VERSION ""

NS_ :

BS_:

BU_: GW_A CRR ADAS CRL MRR PDC VCU WCBS Tester

BO_ 128 ACU_ChimeTelltaleReq: 8 GW_A
 SG_ ACU_CoDSeatOccupSensorStat : 1|2@0+ (1,0) [0|3] ""  CRR,ADAS,CRL
 SG_ ACU_DSeatOccupSensorStat : 3|2@0+ (1,0) [0|3] ""  CRR,ADAS,CRL
 SG_ ACU_CoDSeatbeltBucklestatus : 4|1@0+ (1,0) [0|1] ""  CRR,ADAS,CRL
 SG_ ACU_DSeatbeltBucklestatus : 5|1@0+ (1,0) [0|1] ""  CRR,ADAS,CRL
 SG_ ACU_CoDAirbagStatus : 6|1@0+ (1,0) [0|1] ""  CRR,ADAS,CRL
 SG_ ACU_DAirbagStatus : 7|1@0+ (1,0) [0|1] ""  CRR,ADAS,CRL
 SG_ ACU_RPSeatOccupSensorStat : 9|2@0+ (1,0) [0|3] ""  CRR,ADAS,CRL
 SG_ ACU_MPSeatOccupSensorStat : 11|2@0+ (1,0) [0|3] ""  CRR,ADAS,CRL
 SG_ ACU_LPSeatOccupSensorStat : 13|2@0+ (1,0) [0|3] ""  CRR,ADAS,CRL
 SG_ ACU_RCABsts : 16|1@0+ (1,0) [0|1] ""  CRR,ADAS,CRL
 SG_ ACU_LCABsts : 17|1@0+ (1,0) [0|1] ""  CRR,ADAS,CRL
 SG_ ACU_RSABsts : 18|1@0+ (1,0) [0|1] ""  CRR,ADAS,CRL
 SG_ ACU_LSABsts : 19|1@0+ (1,0) [0|1] ""  CRR,ADAS,CRL
 SG_ ACU_RPSeatbeltBucklestatus : 20|1@0+ (1,0) [0|1] ""  CRR,ADAS,CRL
 SG_ ACU_MPSeatbeltBucklestatus : 21|1@0+ (1,0) [0|1] ""  CRR,ADAS,CRL
 SG_ ACU_LPSeatbeltBucklestatus : 22|1@0+ (1,0) [0|1] ""  CRR,ADAS,CRL
 SG_ ACU_CrashSts : 24|1@0+ (1,0) [0|1] ""  CRR,ADAS,CRL
 SG_ ACU_CrashRearOutputSts : 28|1@0+ (1,0) [0|1] ""  CRR,ADAS,CRL
 SG_ ACU_CrashRightOutputSts : 29|1@0+ (1,0) [0|1] ""  CRR,ADAS,CRL
 SG_ ACU_CrashLeftOutputSts : 30|1@0+ (1,0) [0|1] ""  CRR,ADAS,CRL
 SG_ ACU_CrashFrontOutputSts : 31|1@0+ (1,0) [0|1] ""  CRR,ADAS,CRL
 SG_ ACU_AirbagWarningStatus : 37|2@0+ (1,0) [0|3] ""  CRR,ADAS,CRL
 SG_ ACU_CoDSeatbletPTighten : 45|2@0+ (1,0) [0|3] ""  CRR,ADAS,CRL
 SG_ ACU_DSeatbletPTighten : 47|2@0+ (1,0) [0|3] ""  CRR,ADAS,CRL
 SG_ ACU_AliveCounter : 51|4@0+ (1,0) [0|15] ""  CRR,ADAS,CRL
 SG_ ACU_CheckSum : 63|8@0+ (1,0) [0|255] ""  CRR,ADAS,CRL

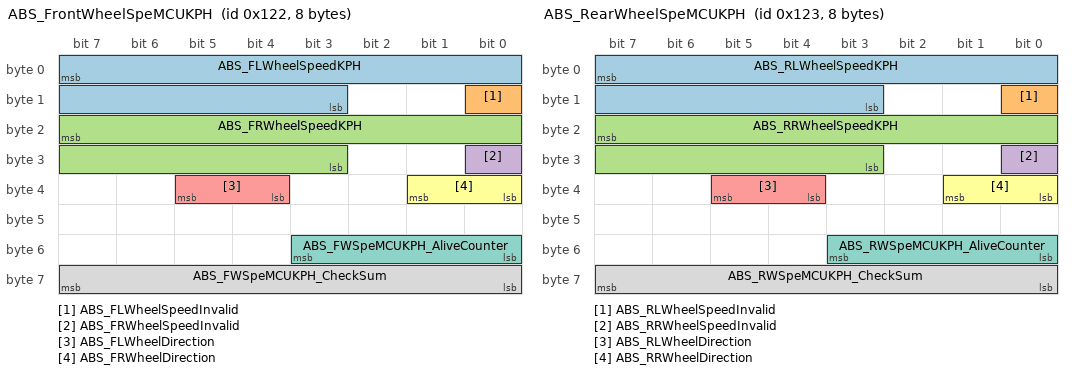
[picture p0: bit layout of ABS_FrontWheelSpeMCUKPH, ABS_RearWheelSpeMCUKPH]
BO_ 290 ABS_FrontWheelSpeMCUKPH: 8 GW_A
 SG_ ABS_FLWheelSpeedKPH : 7|13@0+ (0.05625,0) [0|460.6875] "Km/h"  CRR,ADAS,CRL,MRR
 SG_ ABS_FLWheelSpeedInvalid : 8|1@0+ (1,0) [0|1] ""  CRR,ADAS,CRL,MRR
 SG_ ABS_FRWheelSpeedKPH : 23|13@0+ (0.05625,0) [0|460.6875] "Km/h"  CRR,ADAS,CRL,MRR
 SG_ ABS_FRWheelSpeedInvalid : 24|1@0+ (1,0) [0|1] ""  CRR,ADAS,CRL,MRR
 SG_ ABS_FLWheelDirection : 37|2@0+ (1,0) [0|3] ""  CRR,ADAS,CRL,MRR
 SG_ ABS_FRWheelDirection : 33|2@0+ (1,0) [0|3] ""  CRR,ADAS,CRL,MRR
 SG_ ABS_FWSpeMCUKPH_AliveCounter : 51|4@0+ (1,0) [0|15] ""  CRR,ADAS,CRL,MRR
 SG_ ABS_FWSpeMCUKPH_CheckSum : 63|8@0+ (1,0) [0|255] ""  CRR,ADAS,CRL,MRR

BO_ 291 ABS_RearWheelSpeMCUKPH: 8 GW_A
 SG_ ABS_RLWheelSpeedKPH : 7|13@0+ (0.05625,0) [0|460.6875] "Km/h"  CRR,ADAS,CRL,MRR
 SG_ ABS_RLWheelSpeedInvalid : 8|1@0+ (1,0) [0|1] ""  CRR,ADAS,CRL,MRR
 SG_ ABS_RRWheelSpeedKPH : 23|13@0+ (0.05625,0) [0|460.6875] "Km/h"  CRR,ADAS,CRL,MRR
 SG_ ABS_RRWheelSpeedInvalid : 24|1@0+ (1,0) [0|1] ""  CRR,ADAS,CRL,MRR
 SG_ ABS_RLWheelDirection : 37|2@0+ (1,0) [0|3] ""  CRR,ADAS,CRL,MRR
 SG_ ABS_RRWheelDirection : 33|2@0+ (1,0) [0|3] ""  CRR,ADAS,CRL,MRR
 SG_ ABS_RWSpeMCUKPH_AliveCounter : 51|4@0+ (1,0) [0|15] ""  CRR,ADAS,CRL,MRR
 SG_ ABS_RWSpeMCUKPH_CheckSum : 63|8@0+ (1,0) [0|255] ""  CRR,ADAS,CRL,MRR

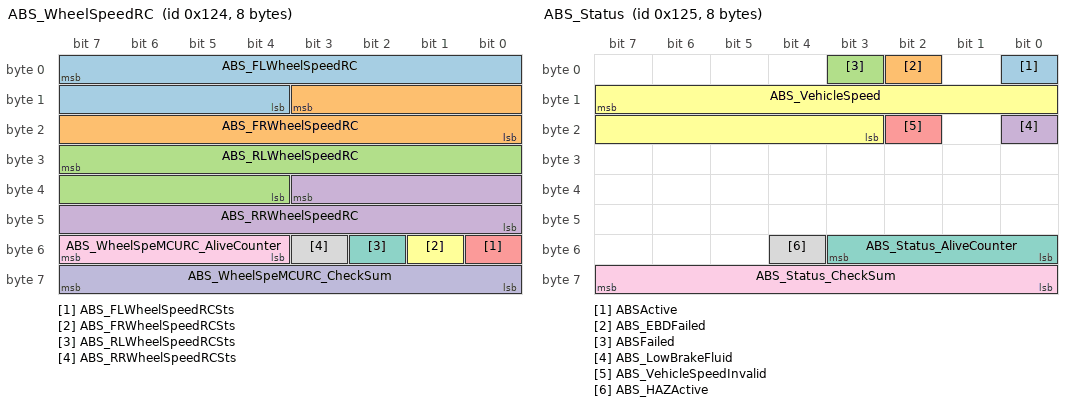
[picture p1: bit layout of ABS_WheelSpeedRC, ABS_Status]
BO_ 292 ABS_WheelSpeedRC: 8 GW_A
 SG_ ABS_FLWheelSpeedRC : 7|12@0+ (1,0) [0|4095] ""  ADAS
 SG_ ABS_FRWheelSpeedRC : 11|12@0+ (1,0) [0|4095] ""  ADAS
 SG_ ABS_RLWheelSpeedRC : 31|12@0+ (1,0) [0|4095] ""  ADAS
 SG_ ABS_RRWheelSpeedRC : 35|12@0+ (1,0) [0|4095] ""  ADAS
 SG_ ABS_FLWheelSpeedRCSts : 48|1@0+ (1,0) [0|1] ""  ADAS
 SG_ ABS_FRWheelSpeedRCSts : 49|1@0+ (1,0) [0|1] ""  ADAS
 SG_ ABS_RLWheelSpeedRCSts : 50|1@0+ (1,0) [0|1] ""  ADAS
 SG_ ABS_RRWheelSpeedRCSts : 51|1@0+ (1,0) [0|1] ""  ADAS
 SG_ ABS_WheelSpeMCURC_AliveCounter : 55|4@0+ (1,0) [0|15] ""  ADAS
 SG_ ABS_WheelSpeMCURC_CheckSum : 63|8@0+ (1,0) [0|255] ""  ADAS

BO_ 262 BCM_LIGHT_0x106: 8 GW_A
 SG_ CheckSum_0x106 : 7|8@0+ (1,0) [0|255] ""  CRR,ADAS,CRL,PDC
 SG_ RollingCounter_0x106 : 11|4@0+ (1,0) [0|15] ""  CRR,ADAS,CRL,PDC
 SG_ BCM_TurnIndicatorSts : 17|2@0+ (1,0) [0|3] ""  CRR,ADAS,CRL,PDC
 SG_ BCM_PosLmpSts : 19|2@0+ (1,0) [0|3] ""  CRR,ADAS,CRL,PDC
 SG_ BCM_LowBeamSts : 21|2@0+ (1,0) [0|3] ""  CRR,ADAS,CRL,PDC
 SG_ BCM_HighBeamSts : 23|2@0+ (1,0) [0|3] ""  CRR,ADAS,CRL,PDC
 SG_ BCM_RearFogLampLightSts : 25|2@0+ (1,0) [0|3] ""  CRR,ADAS,CRL,PDC
 SG_ BCM_BrakeLightSts : 27|2@0+ (1,0) [0|3] ""  CRR,ADAS,CRL,PDC
 SG_ BCM_ReverseLightSts : 29|2@0+ (1,0) [0|3] ""  CRR,ADAS,CRL,PDC
 SG_ BCM_DayRunningLampSts : 31|2@0+ (1,0) [0|3] ""  CRR,ADAS,CRL,PDC
 SG_ BCM_RMarkerLightSts : 33|2@0+ (1,0) [0|3] ""  CRR,ADAS,CRL,PDC
 SG_ BCM_Rr_domelampSts : 35|2@0+ (1,0) [0|3] ""  CRR,ADAS,CRL,PDC
 SG_ BCM_Fr_domelampSts : 37|2@0+ (1,0) [0|3] ""  CRR,ADAS,CRL,PDC
 SG_ BCM_LicensePlateLightSts : 39|2@0+ (1,0) [0|3] ""  CRR,ADAS,CRL,PDC
 SG_ BCM_HeadLight_adjustSts : 43|4@0+ (1,0) [0|15] ""  CRR,ADAS,CRL,PDC
 SG_ BCM_FrontFogLampLightSts : 45|2@0+ (1,0) [0|3] ""  CRR,ADAS,CRL,PDC
 SG_ BCM_STAT_InteriorLight : 47|2@0+ (1,0) [0|3] ""  CRR,ADAS,CRL,PDC
 SG_ BCM_STAT_SwLightBrightness : 54|7@0+ (1,0) [0|100] "%"  CRR,ADAS,CRL,PDC
 SG_ BCM_TurnLight_FaultSts : 59|2@0+ (1,0) [0|3] ""  CRR,ADAS,CRL,PDC
 SG_ BCM_AmbeLightZone2Sts : 61|2@0+ (1,0) [0|3] ""  CRR,ADAS,CRL,PDC
 SG_ BCM_AmbeLightZone1Sts : 63|2@0+ (1,0) [0|3] ""  CRR,ADAS,CRL,PDC

BO_ 293 ABS_Status: 8 GW_A
 SG_ ABSActive : 0|1@0+ (1,0) [0|1] ""  CRR,ADAS,CRL,MRR,PDC
 SG_ ABS_EBDFailed : 2|1@0+ (1,0) [0|1] ""  CRR,ADAS,CRL,MRR,PDC
 SG_ ABSFailed : 3|1@0+ (1,0) [0|1] ""  CRR,ADAS,CRL,MRR,PDC
 SG_ ABS_LowBrakeFluid : 16|1@0+ (1,0) [0|1] ""  CRR,ADAS,CRL,MRR,PDC
 SG_ ABS_VehicleSpeedInvalid : 18|1@0+ (1,0) [0|1] ""  CRR,ADAS,CRL,MRR,PDC
 SG_ ABS_VehicleSpeed : 15|13@0+ (0.05625,0) [0|460.63125] "Km/h"  CRR,ADAS,CRL,MRR,PDC
 SG_ ABS_Status_AliveCounter : 51|4@0+ (1,0) [0|15] ""  CRR,ADAS,CRL,MRR,PDC
 SG_ ABS_HAZActive : 52|1@0+ (1,0) [0|1] ""  CRR,ADAS,CRL,MRR,PDC
 SG_ ABS_Status_CheckSum : 63|8@0+ (1,0) [0|255] ""  CRR,ADAS,CRL,MRR,PDC

BO_ 306 ESC_Status_0x132: 8 GW_A
 SG_ Checksum_0x132 : 7|8@0+ (1,0) [0|255] ""  ADAS
 SG_ RollingCounter_0x132 : 11|4@0+ (1,0) [0|15] ""  ADAS
 SG_ ESC_SlopeGradeAngle : 23|8@0+ (0.35433,-45) [-45|45] "deg"  ADAS
 SG_ ESC_MasterCylinderPressureV : 28|1@0+ (1,0) [0|1] ""  ADAS
 SG_ ESC_MasterCylinderPressure : 27|12@0+ (0.1,-100) [-100|309.4] "bar"  ADAS
 SG_ ESC_HSA_Control_Status : 40|1@0+ (1,0) [0|1] ""  ADAS
 SG_ ESC_HSA_Status_Fault : 41|1@0+ (1,0) [0|1] ""  ADAS
 SG_ ESC_TcsDisableSts : 42|1@0+ (1,0) [0|1] ""  ADAS
 SG_ ESC_EscCtrlActv : 43|1@0+ (1,0) [0|1] ""  ADAS
 SG_ ESC_TcsCtrlActv : 44|1@0+ (1,0) [0|1] ""  ADAS
 SG_ ESC_EscFlgFlt : 45|1@0+ (1,0) [0|1] ""  ADAS
 SG_ ESC_TcsFlgFlt : 46|1@0+ (1,0) [0|1] ""  ADAS
 SG_ ESC_EscDisableSts : 47|1@0+ (1,0) [0|1] ""  ADAS
 SG_ ESC_HBAFlgFlt : 48|1@0+ (1,0) [0|1] ""  ADAS
 SG_ ESC_HbaCtrlActv : 49|1@0+ (1,0) [0|1] ""  ADAS
 SG_ BAS_FlgFlt : 50|1@0+ (1,0) [0|1] ""  ADAS
 SG_ BAS_CtrlActv : 51|1@0+ (1,0) [0|1] ""  ADAS
 SG_ IBS_ESCOFF_StsFB : 52|1@0+ (1,0) [0|1] ""  ADAS

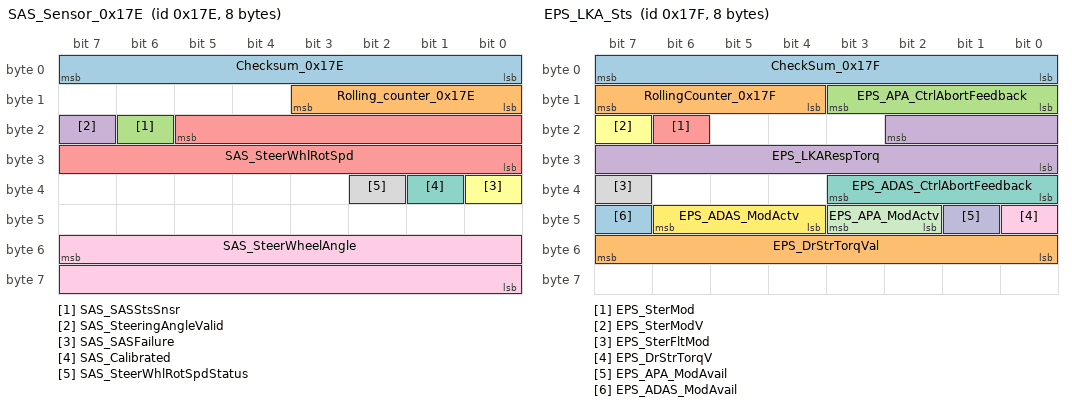
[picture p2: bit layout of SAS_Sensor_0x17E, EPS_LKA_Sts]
BO_ 382 SAS_Sensor_0x17E: 8 GW_A
 SG_ Checksum_0x17E : 7|8@0+ (1,0) [0|255] ""  CRR,ADAS,CRL,MRR,PDC
 SG_ Rolling_counter_0x17E : 11|4@0+ (1,0) [0|15] ""  CRR,ADAS,CRL,MRR,PDC
 SG_ SAS_SASStsSnsr : 22|1@0+ (1,0) [0|1] ""  CRR,ADAS,CRL,MRR,PDC
 SG_ SAS_SteeringAngleValid : 23|1@0+ (1,0) [0|1] ""  CRR,ADAS,CRL,MRR,PDC
 SG_ SAS_SteerWhlRotSpd : 21|14@0+ (0.125,-1024) [-1024|1023.75] "deg/s"  CRR,ADAS,CRL,MRR,PDC
 SG_ SAS_SASFailure : 32|1@0+ (1,0) [0|1] ""  CRR,ADAS,CRL,MRR,PDC
 SG_ SAS_Calibrated : 33|1@0+ (1,0) [0|1] ""  CRR,ADAS,CRL,MRR,PDC
 SG_ SAS_SteerWhlRotSpdStatus : 34|1@0+ (1,0) [0|1] ""  CRR,ADAS,CRL,MRR,PDC
 SG_ SAS_SteerWheelAngle : 55|16@0+ (0.0238,-780) [-780|779.7] "deg"  CRR,ADAS,CRL,MRR,PDC

BO_ 383 EPS_LKA_Sts: 8 GW_A
 SG_ CheckSum_0x17F : 7|8@0+ (1,0) [0|255] ""  ADAS
 SG_ RollingCounter_0x17F : 15|4@0+ (1,0) [0|15] ""  ADAS
 SG_ EPS_APA_CtrlAbortFeedback : 11|4@0+ (1,0) [0|15] ""  ADAS
 SG_ EPS_LKARespTorq : 18|11@0+ (0.01,-10) [-10|10] "Nm"  ADAS
 SG_ EPS_SterMod : 22|1@0+ (1,0) [0|1] ""  ADAS
 SG_ EPS_SterModV : 23|1@0+ (1,0) [0|1] ""  ADAS
 SG_ EPS_ADAS_CtrlAbortFeedback : 35|4@0+ (1,0) [0|15] ""  ADAS
 SG_ EPS_SterFltMod : 39|1@0+ (1,0) [0|1] ""  ADAS
 SG_ EPS_DrStrTorqV : 40|1@0+ (1,0) [0|1] ""  ADAS
 SG_ EPS_APA_ModAvail : 41|1@0+ (1,0) [0|1] ""  ADAS
 SG_ EPS_APA_ModActv : 43|2@0+ (1,0) [0|1] "" Vector__XXX
 SG_ EPS_ADAS_ModActv : 46|3@0+ (1,0) [0|2] "" Vector__XXX
 SG_ EPS_ADAS_ModAvail : 47|1@0+ (1,0) [0|1] "" Vector__XXX
 SG_ EPS_DrStrTorqVal : 55|8@0+ (0.1,-10) [-10|10] "Nm"  ADAS

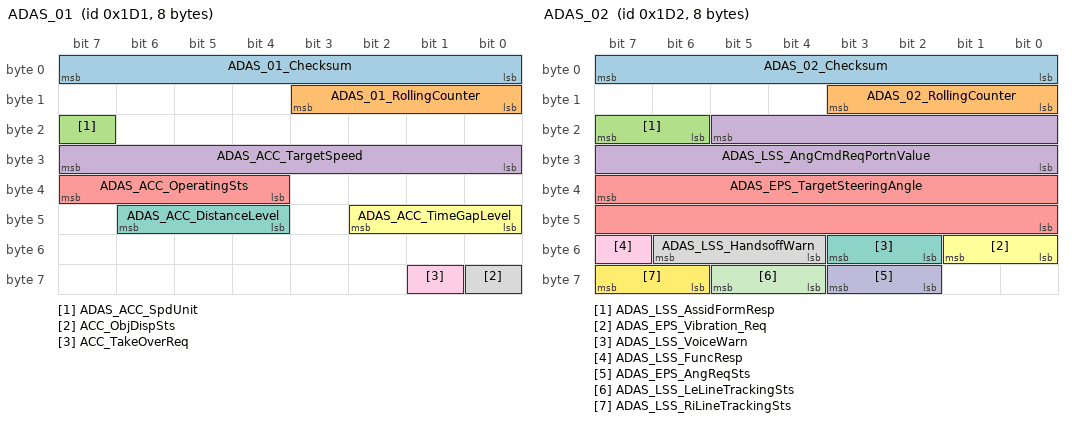
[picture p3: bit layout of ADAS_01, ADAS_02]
BO_ 465 ADAS_01: 8 ADAS
 SG_ ADAS_01_Checksum : 7|8@0+ (1,0) [0|255] ""  GW_A,VCU
 SG_ ADAS_01_RollingCounter : 11|4@0+ (1,0) [0|15] ""  GW_A,VCU
 SG_ ADAS_ACC_SpdUnit : 23|1@0+ (1,0) [0|1] ""  GW_A,VCU
 SG_ ADAS_ACC_TargetSpeed : 31|8@0+ (1,0) [0|255] ""  GW_A,VCU
 SG_ ADAS_ACC_OperatingSts : 39|4@0+ (1,0) [0|15] ""  GW_A,VCU
 SG_ ADAS_ACC_TimeGapLevel : 42|3@0+ (1,0) [0|7] ""  GW_A,VCU
 SG_ ADAS_ACC_DistanceLevel : 46|3@0+ (1,0) [0|7] ""  GW_A,VCU
 SG_ ACC_ObjDispSts : 56|1@0+ (1,0) [0|1] ""  GW_A,VCU
 SG_ ACC_TakeOverReq : 57|1@0+ (1,0) [0|1] ""  GW_A,VCU

BO_ 466 ADAS_02: 8 ADAS
 SG_ ADAS_02_Checksum : 7|8@0+ (1,0) [0|255] ""  GW_A
 SG_ ADAS_02_RollingCounter : 11|4@0+ (1,0) [0|15] ""  GW_A
 SG_ ADAS_LSS_AssidFormResp : 23|2@0+ (1,0) [0|3] ""  GW_A
 SG_ ADAS_LSS_AngCmdReqPortnValue : 21|14@0+ (0.1,-780) [-780|780] ""  GW_A
 SG_ ADAS_EPS_TargetSteeringAngle : 39|16@0+ (0.0238,-780) [-780|779.7] "deg"  GW_A
 SG_ ADAS_EPS_Vibration_Req : 49|2@0+ (1,0) [0|3] ""  GW_A
 SG_ ADAS_LSS_VoiceWarn : 51|2@0+ (1,0) [0|3] ""  GW_A
 SG_ ADAS_LSS_HandsoffWarn : 54|3@0+ (1,0) [0|7] ""  GW_A
 SG_ ADAS_LSS_FuncResp : 55|1@0+ (1,0) [0|1] ""  GW_A
 SG_ ADAS_EPS_AngReqSts : 59|2@0+ (1,0) [0|3] ""  GW_A
 SG_ ADAS_LSS_LeLineTrackingSts : 61|2@0+ (1,0) [0|3] ""  GW_A
 SG_ ADAS_LSS_RiLineTrackingSts : 63|2@0+ (1,0) [0|3] ""  GW_A

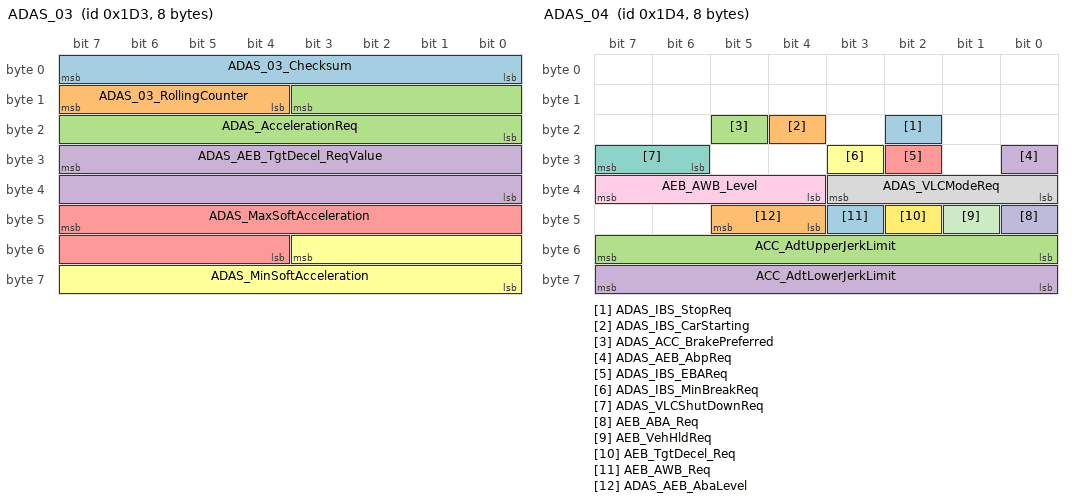
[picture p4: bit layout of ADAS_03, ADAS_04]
BO_ 467 ADAS_03: 8 ADAS
 SG_ ADAS_03_Checksum : 7|8@0+ (1,0) [0|255] ""  GW_A
 SG_ ADAS_03_RollingCounter : 15|4@0+ (1,0) [0|15] ""  GW_A
 SG_ ADAS_AccelerationReq : 11|12@0+ (0.005,-5) [-5|5] "m/s2"  GW_A
 SG_ ADAS_AEB_TgtDecel_ReqValue : 31|16@0+ (0.000488,-16) [-16|15.98059] "m/s2"  GW_A
 SG_ ADAS_MaxSoftAcceleration : 47|12@0+ (0.005,-5) [-5|5] "m/s2"  GW_A
 SG_ ADAS_MinSoftAcceleration : 51|12@0+ (0.005,-5) [-5|5] "m/s2"  GW_A

BO_ 468 ADAS_04: 8 ADAS
 SG_ ADAS_IBS_StopReq : 18|1@0+ (1,0) [0|1] ""  GW_A
 SG_ ADAS_IBS_CarStarting : 20|1@0+ (1,0) [0|1] ""  GW_A
 SG_ ADAS_ACC_BrakePreferred : 21|1@0+ (1,0) [0|1] ""  GW_A
 SG_ ADAS_AEB_AbpReq : 24|1@0+ (1,0) [0|1] ""  GW_A
 SG_ ADAS_IBS_EBAReq : 26|1@0+ (1,0) [0|1] ""  GW_A
 SG_ ADAS_IBS_MinBreakReq : 27|1@0+ (1,0) [0|1] ""  GW_A
 SG_ ADAS_VLCShutDownReq : 31|2@0+ (1,0) [0|3] ""  GW_A
 SG_ ADAS_VLCModeReq : 35|4@0+ (1,0) [0|15] ""  GW_A
 SG_ AEB_AWB_Level : 39|4@0+ (1,0) [0|15] ""  GW_A
 SG_ AEB_ABA_Req : 40|1@0+ (1,0) [0|1] ""  GW_A
 SG_ AEB_VehHldReq : 41|1@0+ (1,0) [0|1] ""  GW_A
 SG_ AEB_TgtDecel_Req : 42|1@0+ (1,0) [0|1] ""  GW_A
 SG_ AEB_AWB_Req : 43|1@0+ (1,0) [0|1] ""  GW_A
 SG_ ADAS_AEB_AbaLevel : 45|2@0+ (1,0) [0|3] ""  GW_A
 SG_ ACC_AdtUpperJerkLimit : 55|8@0+ (0.1,0) [0|12.7] "m/s3"  GW_A
 SG_ ACC_AdtLowerJerkLimit : 63|8@0+ (0.1,-12.7) [-12.7|0] "m/s3"  GW_A

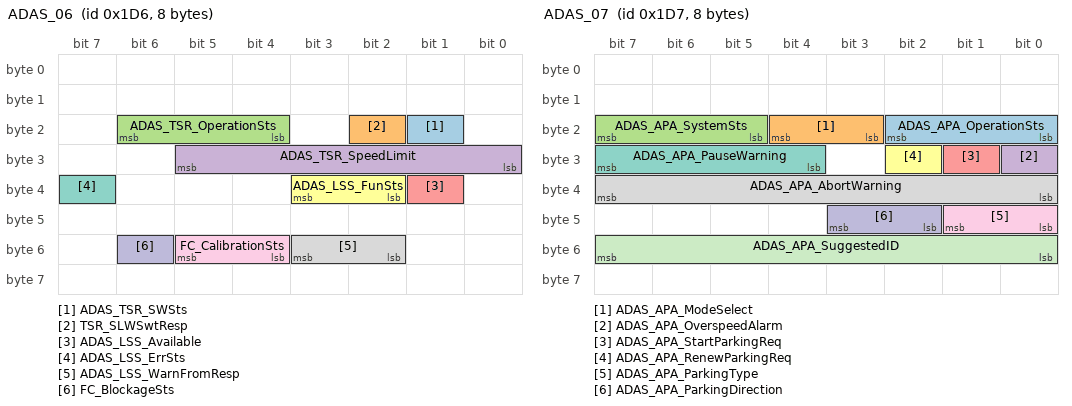
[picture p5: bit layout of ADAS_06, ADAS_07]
BO_ 470 ADAS_06: 8 ADAS
 SG_ ADAS_TSR_SWSts : 17|1@0+ (1,0) [0|1] ""  GW_A
 SG_ TSR_SLWSwtResp : 18|1@0+ (1,0) [0|1] ""  GW_A
 SG_ ADAS_TSR_OperationSts : 22|3@0+ (1,0) [0|7] ""  GW_A
 SG_ ADAS_TSR_SpeedLimit : 29|6@0+ (1,0) [0|63] ""  GW_A
 SG_ ADAS_LSS_Available : 33|1@0+ (1,0) [0|1] ""  GW_A
 SG_ ADAS_LSS_FunSts : 35|2@0+ (1,0) [0|3] ""  GW_A
 SG_ ADAS_LSS_ErrSts : 39|1@0+ (1,0) [0|1] ""  GW_A
 SG_ ADAS_LSS_WarnFromResp : 51|2@0+ (1,0) [0|3] ""  GW_A
 SG_ FC_CalibrationSts : 53|2@0+ (1,0) [0|3] ""  GW_A
 SG_ FC_BlockageSts : 54|1@0+ (1,0) [0|1] ""  GW_A

BO_ 471 ADAS_07: 8 ADAS
 SG_ ADAS_APA_OperationSts : 18|3@0+ (1,0) [0|7] ""  GW_A
 SG_ ADAS_APA_ModeSelect : 20|2@0+ (1,0) [0|3] ""  GW_A
 SG_ ADAS_APA_SystemSts : 23|3@0+ (1,0) [0|7] ""  GW_A
 SG_ ADAS_APA_OverspeedAlarm : 24|1@0+ (1,0) [0|1] ""  GW_A
 SG_ ADAS_APA_StartParkingReq : 25|1@0+ (1,0) [0|1] ""  GW_A
 SG_ ADAS_APA_RenewParkingReq : 26|1@0+ (1,0) [0|1] ""  GW_A
 SG_ ADAS_APA_PauseWarning : 31|4@0+ (1,0) [0|15] ""  GW_A
 SG_ ADAS_APA_AbortWarning : 39|8@0+ (1,0) [0|255] ""  GW_A
 SG_ ADAS_APA_ParkingType : 41|2@0+ (1,0) [0|3] ""  GW_A
 SG_ ADAS_APA_ParkingDirection : 43|2@0+ (1,0) [0|3] ""  GW_A
 SG_ ADAS_APA_SuggestedID : 55|8@0+ (1,0) [0|255] ""  GW_A

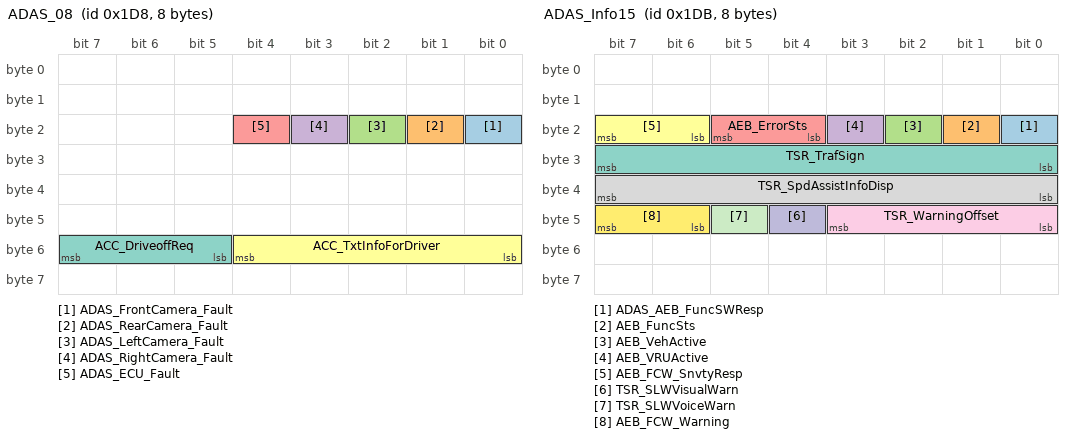
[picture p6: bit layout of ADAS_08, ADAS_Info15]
BO_ 472 ADAS_08: 8 ADAS
 SG_ ADAS_FrontCamera_Fault : 16|1@0+ (1,0) [0|1] ""  GW_A
 SG_ ADAS_RearCamera_Fault : 17|1@0+ (1,0) [0|1] ""  GW_A
 SG_ ADAS_LeftCamera_Fault : 18|1@0+ (1,0) [0|1] ""  GW_A
 SG_ ADAS_RightCamera_Fault : 19|1@0+ (1,0) [0|1] ""  GW_A
 SG_ ADAS_ECU_Fault : 20|1@0+ (1,0) [0|1] ""  GW_A
 SG_ ACC_TxtInfoForDriver : 52|5@0+ (1,0) [0|31] ""  GW_A
 SG_ ACC_DriveoffReq : 55|3@0+ (1,0) [0|7] ""  GW_A

BO_ 475 ADAS_Info15: 8 ADAS
 SG_ ADAS_AEB_FuncSWResp : 16|1@0+ (1,0) [0|1] ""  GW_A
 SG_ AEB_FuncSts : 17|1@0+ (1,0) [0|1] ""  GW_A
 SG_ AEB_VehActive : 18|1@0+ (1,0) [0|1] ""  GW_A
 SG_ AEB_VRUActive : 19|1@0+ (1,0) [0|1] ""  GW_A
 SG_ AEB_ErrorSts : 21|2@0+ (1,0) [0|3] ""  GW_A
 SG_ AEB_FCW_SnvtyResp : 23|2@0+ (1,0) [0|3] ""  GW_A
 SG_ TSR_TrafSign : 31|8@0+ (1,0) [0|255] ""  GW_A
 SG_ TSR_SpdAssistInfoDisp : 39|8@0+ (1,0) [0|255] ""  GW_A
 SG_ TSR_WarningOffset : 43|4@0+ (1,0) [0|15] ""  GW_A
 SG_ TSR_SLWVisualWarn : 44|1@0+ (1,0) [0|1] ""  GW_A
 SG_ TSR_SLWVoiceWarn : 45|1@0+ (1,0) [0|1] ""  GW_A
 SG_ AEB_FCW_Warning : 47|2@0+ (1,0) [0|3] ""  GW_A

BO_ 476 ADAS_Info16: 8 CRL
 SG_ BSD_LCA_FuncSwtResp : 18|1@0+ (1,0) [0|1] ""  GW_A
 SG_ RCTA_FuncSwtResp : 19|1@0+ (1,0) [0|1] ""  GW_A
 SG_ RCTA_FuncSts : 25|2@0+ (1,0) [0|3] ""  GW_A
 SG_ RCW_FuncSts : 27|2@0+ (1,0) [0|3] ""  GW_A
 SG_ RCR_SysErrorSts : 29|2@0+ (1,0) [0|3] ""  GW_A
 SG_ BSD_LCA_FuncSts : 31|2@0+ (1,0) [0|3] ""  GW_A
 SG_ BSD_LCA_WarningReqRight : 33|2@0+ (1,0) [0|3] ""  GW_A
 SG_ RCR_BlockagedSts : 34|1@0+ (1,0) [0|1] ""  GW_A
 SG_ RCW_FuncSwtResp : 35|1@0+ (1,0) [0|1] ""  GW_A
 SG_ BSD_LCA_WarningReqLeft : 37|2@0+ (1,0) [0|3] ""  GW_A
 SG_ RCR_VoiceWarningReq : 39|2@0+ (1,0) [0|3] ""  GW_A
 SG_ RCTA_WarningReqRight : 40|1@0+ (1,0) [0|1] ""  GW_A
 SG_ RCTA_WarningReqLeft : 41|1@0+ (1,0) [0|1] ""  GW_A
 SG_ RCW_WarningReq : 42|1@0+ (1,0) [0|1] ""  GW_A
 SG_ RCW_Hazard_lightReq : 43|1@0+ (1,0) [0|1] ""  GW_A
 SG_ DOW_WarningReqRight : 45|2@0+ (1,0) [0|3] ""  GW_A
 SG_ DOW_WarningReqLeft : 47|2@0+ (1,0) [0|3] ""  GW_A
 SG_ DOW_FuncSts : 49|2@0+ (1,0) [0|3] ""  GW_A
 SG_ DOW_FuncSwtResp : 52|1@0+ (1,0) [0|1] ""  GW_A

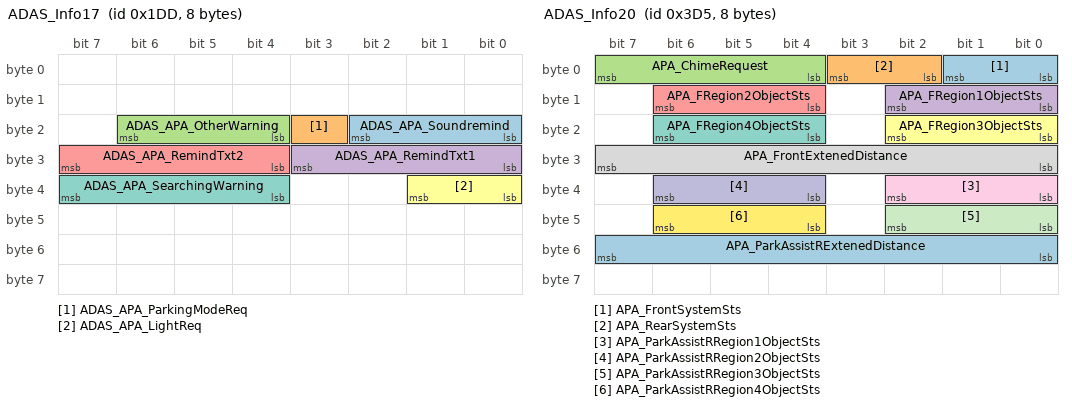
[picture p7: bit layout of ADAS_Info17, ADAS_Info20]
BO_ 477 ADAS_Info17: 8 ADAS
 SG_ ADAS_APA_Soundremind : 18|3@0+ (1,0) [0|7] ""  GW_A
 SG_ ADAS_APA_ParkingModeReq : 19|1@0+ (1,0) [0|1] ""  GW_A
 SG_ ADAS_APA_OtherWarning : 22|3@0+ (1,0) [0|7] ""  GW_A
 SG_ ADAS_APA_RemindTxt1 : 27|4@0+ (1,0) [0|15] ""  GW_A
 SG_ ADAS_APA_RemindTxt2 : 31|4@0+ (1,0) [0|15] ""  GW_A
 SG_ ADAS_APA_LightReq : 33|2@0+ (1,0) [0|3] ""  GW_A
 SG_ ADAS_APA_SearchingWarning : 39|4@0+ (1,0) [0|15] ""  GW_A

BO_ 981 ADAS_Info20: 8 ADAS
 SG_ APA_FrontSystemSts : 1|2@0+ (1,0) [0|3] ""  GW_A
 SG_ APA_RearSystemSts : 3|2@0+ (1,0) [0|3] ""  GW_A
 SG_ APA_ChimeRequest : 7|4@0+ (1,0) [0|15] ""  GW_A
 SG_ APA_FRegion1ObjectSts : 10|3@0+ (1,0) [0|7] ""  GW_A
 SG_ APA_FRegion2ObjectSts : 14|3@0+ (1,0) [0|7] ""  GW_A
 SG_ APA_FRegion3ObjectSts : 18|3@0+ (1,0) [0|7] ""  GW_A
 SG_ APA_FRegion4ObjectSts : 22|3@0+ (1,0) [0|7] ""  GW_A
 SG_ APA_FrontExtenedDistance : 31|8@0+ (1,0) [0|255] "cm"  GW_A
 SG_ APA_ParkAssistRRegion1ObjectSts : 34|3@0+ (1,0) [0|7] ""  GW_A
 SG_ APA_ParkAssistRRegion2ObjectSts : 38|3@0+ (1,0) [0|7] ""  GW_A
 SG_ APA_ParkAssistRRegion3ObjectSts : 42|3@0+ (1,0) [0|7] ""  GW_A
 SG_ APA_ParkAssistRRegion4ObjectSts : 46|3@0+ (1,0) [0|7] ""  GW_A
 SG_ APA_ParkAssistRExtenedDistance : 55|8@0+ (1,0) [0|255] "cm"  GW_A

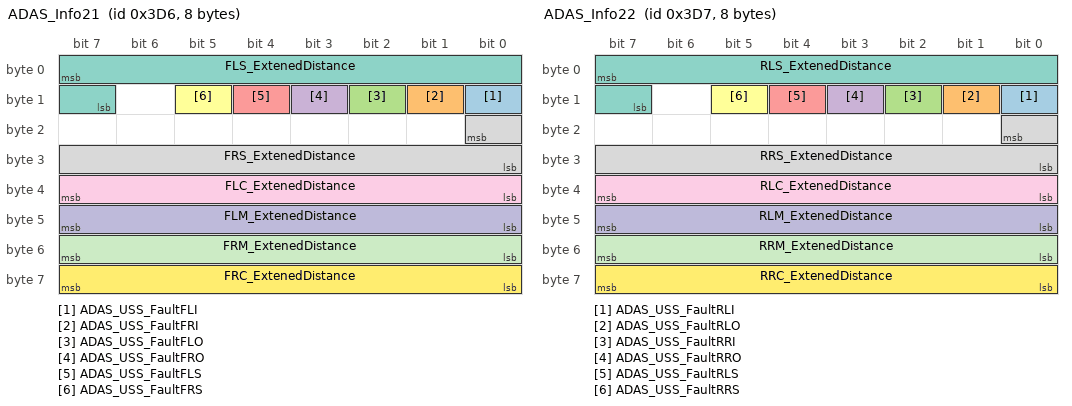
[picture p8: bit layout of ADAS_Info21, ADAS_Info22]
BO_ 982 ADAS_Info21: 8 ADAS
 SG_ ADAS_USS_FaultFLI : 8|1@0+ (1,0) [0|1] ""  GW_A
 SG_ ADAS_USS_FaultFRI : 9|1@0+ (1,0) [0|1] ""  GW_A
 SG_ ADAS_USS_FaultFLO : 10|1@0+ (1,0) [0|1] ""  GW_A
 SG_ ADAS_USS_FaultFRO : 11|1@0+ (1,0) [0|1] ""  GW_A
 SG_ ADAS_USS_FaultFLS : 12|1@0+ (1,0) [0|1] ""  GW_A
 SG_ ADAS_USS_FaultFRS : 13|1@0+ (1,0) [0|1] ""  GW_A
 SG_ FLS_ExtenedDistance : 7|9@0+ (1,0) [0|511] "cm"  GW_A
 SG_ FRS_ExtenedDistance : 16|9@0+ (1,0) [0|511] "cm"  GW_A
 SG_ FLC_ExtenedDistance : 39|8@0+ (1,0) [0|255] "cm"  GW_A
 SG_ FLM_ExtenedDistance : 47|8@0+ (1,0) [0|255] "cm"  GW_A
 SG_ FRM_ExtenedDistance : 55|8@0+ (1,0) [0|255] "cm"  GW_A
 SG_ FRC_ExtenedDistance : 63|8@0+ (1,0) [0|255] "cm"  GW_A

BO_ 983 ADAS_Info22: 8 ADAS
 SG_ ADAS_USS_FaultRLI : 8|1@0+ (1,0) [0|1] ""  GW_A
 SG_ ADAS_USS_FaultRLO : 9|1@0+ (1,0) [0|1] ""  GW_A
 SG_ ADAS_USS_FaultRRI : 10|1@0+ (1,0) [0|1] ""  GW_A
 SG_ ADAS_USS_FaultRRO : 11|1@0+ (1,0) [0|1] ""  GW_A
 SG_ ADAS_USS_FaultRLS : 12|1@0+ (1,0) [0|1] ""  GW_A
 SG_ ADAS_USS_FaultRRS : 13|1@0+ (1,0) [0|1] ""  GW_A
 SG_ RLS_ExtenedDistance : 7|9@0+ (1,0) [0|511] "cm"  GW_A
 SG_ RRS_ExtenedDistance : 16|9@0+ (1,0) [0|511] "cm"  GW_A
 SG_ RLC_ExtenedDistance : 39|8@0+ (1,0) [0|255] "cm"  GW_A
 SG_ RLM_ExtenedDistance : 47|8@0+ (1,0) [0|255] "cm"  GW_A
 SG_ RRM_ExtenedDistance : 55|8@0+ (1,0) [0|255] "cm"  GW_A
 SG_ RRC_ExtenedDistance : 63|8@0+ (1,0) [0|255] "cm"  GW_A

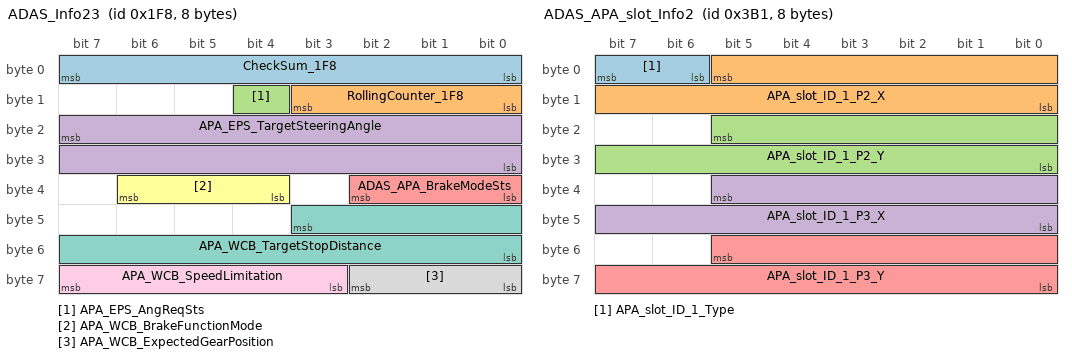
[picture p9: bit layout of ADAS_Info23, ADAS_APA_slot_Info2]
BO_ 504 ADAS_Info23: 8 ADAS
 SG_ CheckSum_1F8 : 7|8@0+ (1,0) [0|255] ""  GW_A
 SG_ RollingCounter_1F8 : 11|4@0+ (1,0) [0|15] ""  GW_A
 SG_ APA_EPS_AngReqSts : 12|1@0+ (1,0) [0|1] ""  GW_A
 SG_ APA_EPS_TargetSteeringAngle : 23|16@0+ (0.0238,-780) [-780|779.7] "deg"  GW_A
 SG_ ADAS_APA_BrakeModeSts : 34|3@0+ (1,0) [0|7] ""  GW_A
 SG_ APA_WCB_BrakeFunctionMode : 38|3@0+ (1,0) [0|7] ""  GW_A
 SG_ APA_WCB_TargetStopDistance : 43|12@0+ (1,0) [0|4095] "cm"  GW_A
 SG_ APA_WCB_ExpectedGearPosition : 58|3@0+ (1,0) [0|7] ""  GW_A
 SG_ APA_WCB_SpeedLimitation : 63|5@0+ (1,0) [0|31] "Km/h"  GW_A

BO_ 929 ADAS_APA_slot_Info1: 8 ADAS
 SG_ APA_slot_1 : 7|8@0+ (1,0) [0|255] ""  GW_A
 SG_ APA_slot_ID_1_P0_X : 15|14@0+ (1,0) [0|16383] ""  GW_A
 SG_ APA_slot_ID_1_P0_Y : 17|14@0+ (1,0) [0|16383] ""  GW_A
 SG_ APA_slot_ID_1_P1_X : 35|14@0+ (1,0) [0|16383] ""  GW_A
 SG_ APA_slot_ID_1_P1_Y : 53|14@0+ (1,0) [0|16383] ""  GW_A

BO_ 945 ADAS_APA_slot_Info2: 8 ADAS
 SG_ APA_slot_ID_1_Type : 7|2@0+ (1,0) [0|3] ""  GW_A
 SG_ APA_slot_ID_1_P2_X : 5|14@0+ (1,0) [0|16383] ""  GW_A
 SG_ APA_slot_ID_1_P2_Y : 21|14@0+ (1,0) [0|16383] ""  GW_A
 SG_ APA_slot_ID_1_P3_X : 37|14@0+ (1,0) [0|16383] ""  GW_A
 SG_ APA_slot_ID_1_P3_Y : 53|14@0+ (1,0) [0|16383] ""  GW_A

BO_ 930 ADAS_APA_slot_Info3: 8 ADAS
 SG_ APA_slot_2 : 7|8@0+ (1,0) [0|255] ""  GW_A
 SG_ APA_slot_ID_2_P0_X : 15|14@0+ (1,0) [0|16383] ""  GW_A
 SG_ APA_slot_ID_2_P0_Y : 17|14@0+ (1,0) [0|16383] ""  GW_A
 SG_ APA_slot_ID_2_P1_X : 35|14@0+ (1,0) [0|16383] ""  GW_A
 SG_ APA_slot_ID_2_P1_Y : 53|14@0+ (1,0) [0|16383] ""  GW_A

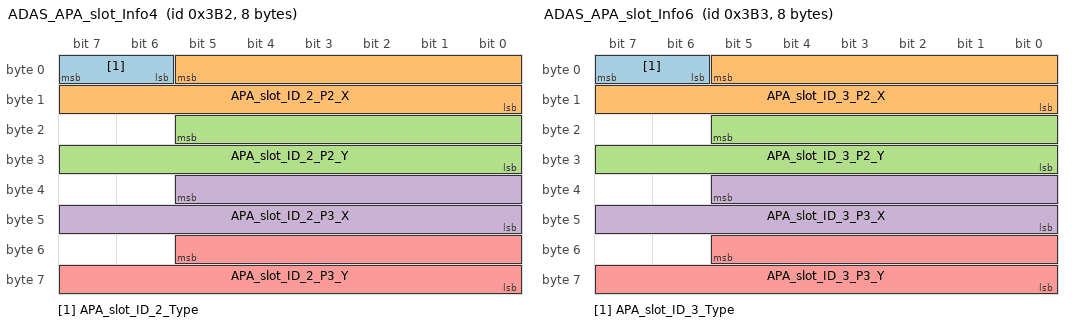
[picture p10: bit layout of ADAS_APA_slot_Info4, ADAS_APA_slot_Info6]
BO_ 946 ADAS_APA_slot_Info4: 8 ADAS
 SG_ APA_slot_ID_2_Type : 7|2@0+ (1,0) [0|3] ""  GW_A
 SG_ APA_slot_ID_2_P2_X : 5|14@0+ (1,0) [0|16383] ""  GW_A
 SG_ APA_slot_ID_2_P2_Y : 21|14@0+ (1,0) [0|16383] ""  GW_A
 SG_ APA_slot_ID_2_P3_X : 37|14@0+ (1,0) [0|16383] ""  GW_A
 SG_ APA_slot_ID_2_P3_Y : 53|14@0+ (1,0) [0|16383] ""  GW_A

BO_ 931 ADAS_APA_slot_Info5: 8 ADAS
 SG_ APA_slot_3 : 7|8@0+ (1,0) [0|255] ""  GW_A
 SG_ APA_slot_ID_3_P0_X : 15|14@0+ (1,0) [0|16383] ""  GW_A
 SG_ APA_slot_ID_3_P0_Y : 17|14@0+ (1,0) [0|16383] ""  GW_A
 SG_ APA_slot_ID_3_P1_X : 35|14@0+ (1,0) [0|16383] ""  GW_A
 SG_ APA_slot_ID_3_P1_Y : 53|14@0+ (1,0) [0|16383] ""  GW_A

BO_ 947 ADAS_APA_slot_Info6: 8 ADAS
 SG_ APA_slot_ID_3_Type : 7|2@0+ (1,0) [0|3] ""  GW_A
 SG_ APA_slot_ID_3_P2_X : 5|14@0+ (1,0) [0|16383] ""  GW_A
 SG_ APA_slot_ID_3_P2_Y : 21|14@0+ (1,0) [0|16383] ""  GW_A
 SG_ APA_slot_ID_3_P3_X : 37|14@0+ (1,0) [0|16383] ""  GW_A
 SG_ APA_slot_ID_3_P3_Y : 53|14@0+ (1,0) [0|16383] ""  GW_A

BO_ 932 ADAS_APA_slot_Info7: 8 ADAS
 SG_ APA_slot_4 : 7|8@0+ (1,0) [0|255] ""  GW_A
 SG_ APA_slot_ID_4_P0_X : 15|14@0+ (1,0) [0|16383] ""  GW_A
 SG_ APA_slot_ID_4_P0_Y : 17|14@0+ (1,0) [0|16383] ""  GW_A
 SG_ APA_slot_ID_4_P1_X : 35|14@0+ (1,0) [0|16383] ""  GW_A
 SG_ APA_slot_ID_4_P1_Y : 53|14@0+ (1,0) [0|16383] ""  GW_A

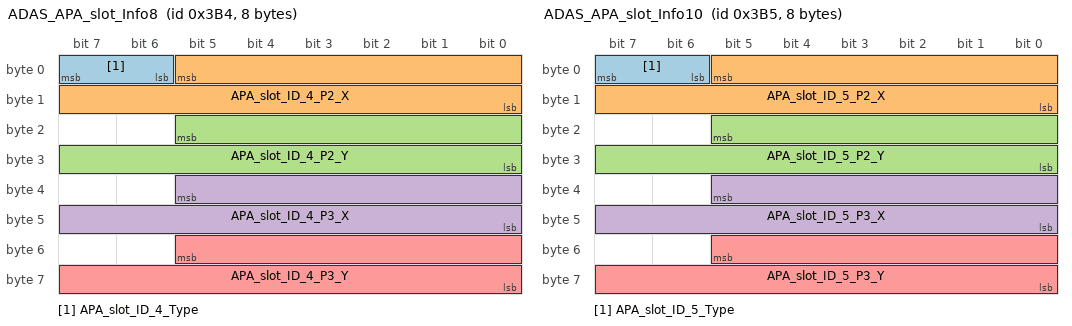
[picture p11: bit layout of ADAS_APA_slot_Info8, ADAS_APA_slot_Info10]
BO_ 948 ADAS_APA_slot_Info8: 8 ADAS
 SG_ APA_slot_ID_4_Type : 7|2@0+ (1,0) [0|3] ""  GW_A
 SG_ APA_slot_ID_4_P2_X : 5|14@0+ (1,0) [0|16383] ""  GW_A
 SG_ APA_slot_ID_4_P2_Y : 21|14@0+ (1,0) [0|16383] ""  GW_A
 SG_ APA_slot_ID_4_P3_X : 37|14@0+ (1,0) [0|16383] ""  GW_A
 SG_ APA_slot_ID_4_P3_Y : 53|14@0+ (1,0) [0|16383] ""  GW_A

BO_ 933 ADAS_APA_slot_Info9: 8 ADAS
 SG_ APA_slot_5 : 7|8@0+ (1,0) [0|255] ""  GW_A
 SG_ APA_slot_ID_5_P0_X : 15|14@0+ (1,0) [0|16383] ""  GW_A
 SG_ APA_slot_ID_5_P0_Y : 17|14@0+ (1,0) [0|16383] ""  GW_A
 SG_ APA_slot_ID_5_P1_X : 35|14@0+ (1,0) [0|16383] ""  GW_A
 SG_ APA_slot_ID_5_P1_Y : 53|14@0+ (1,0) [0|16383] ""  GW_A

BO_ 949 ADAS_APA_slot_Info10: 8 ADAS
 SG_ APA_slot_ID_5_Type : 7|2@0+ (1,0) [0|3] ""  GW_A
 SG_ APA_slot_ID_5_P2_X : 5|14@0+ (1,0) [0|16383] ""  GW_A
 SG_ APA_slot_ID_5_P2_Y : 21|14@0+ (1,0) [0|16383] ""  GW_A
 SG_ APA_slot_ID_5_P3_X : 37|14@0+ (1,0) [0|16383] ""  GW_A
 SG_ APA_slot_ID_5_P3_Y : 53|14@0+ (1,0) [0|16383] ""  GW_A

BO_ 934 ADAS_APA_slot_Info11: 8 ADAS
 SG_ APA_slot_6 : 7|8@0+ (1,0) [0|255] ""  GW_A
 SG_ APA_slot_ID_6_P0_X : 15|14@0+ (1,0) [0|16383] ""  GW_A
 SG_ APA_slot_ID_6_P0_Y : 17|14@0+ (1,0) [0|16383] ""  GW_A
 SG_ APA_slot_ID_6_P1_X : 35|14@0+ (1,0) [0|16383] ""  GW_A
 SG_ APA_slot_ID_6_P1_Y : 53|14@0+ (1,0) [0|16383] ""  GW_A

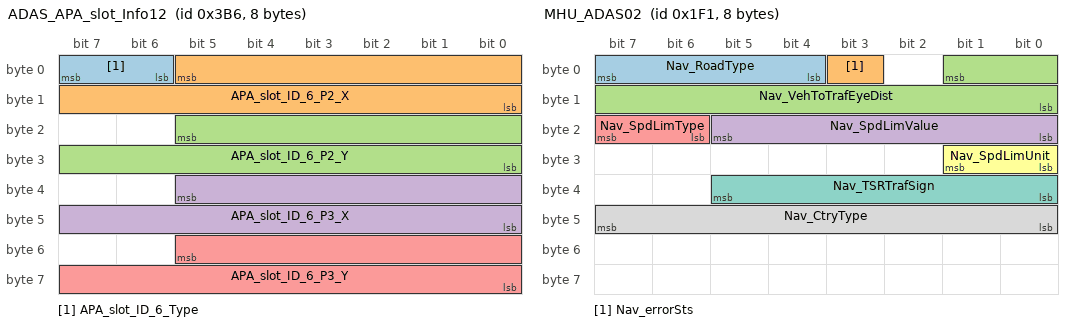
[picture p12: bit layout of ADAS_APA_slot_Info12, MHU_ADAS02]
BO_ 950 ADAS_APA_slot_Info12: 8 ADAS
 SG_ APA_slot_ID_6_Type : 7|2@0+ (1,0) [0|3] ""  GW_A
 SG_ APA_slot_ID_6_P2_X : 5|14@0+ (1,0) [0|16383] ""  GW_A
 SG_ APA_slot_ID_6_P2_Y : 21|14@0+ (1,0) [0|16383] ""  GW_A
 SG_ APA_slot_ID_6_P3_X : 37|14@0+ (1,0) [0|16383] ""  GW_A
 SG_ APA_slot_ID_6_P3_Y : 53|14@0+ (1,0) [0|16383] ""  GW_A

BO_ 935 ADAS_APA_slot_Info13: 8 ADAS
 SG_ APA_slot_7 : 7|8@0+ (1,0) [0|255] ""  GW_A
 SG_ APA_slot_ID_7_P0_X : 15|14@0+ (1,0) [0|16383] ""  GW_A
 SG_ APA_slot_ID_7_P0_Y : 17|14@0+ (1,0) [0|16383] ""  GW_A
 SG_ APA_slot_ID_7_P1_X : 35|14@0+ (1,0) [0|16383] ""  GW_A
 SG_ APA_slot_ID_7_P1_Y : 53|14@0+ (1,0) [0|16383] ""  GW_A

BO_ 951 ADAS_APA_slot_Info14: 8 ADAS
 SG_ APA_slot_ID_7_Type : 7|2@0+ (1,0) [0|3] ""  GW_A
 SG_ APA_slot_ID_7_P2_X : 5|14@0+ (1,0) [0|16383] ""  GW_A
 SG_ APA_slot_ID_7_P2_Y : 21|14@0+ (1,0) [0|16383] ""  GW_A
 SG_ APA_slot_ID_7_P3_X : 37|14@0+ (1,0) [0|16383] ""  GW_A
 SG_ APA_slot_ID_7_P3_Y : 53|14@0+ (1,0) [0|16383] ""  GW_A

BO_ 936 ADAS_APA_slot_Info15: 8 ADAS
 SG_ APA_slot_8 : 7|8@0+ (1,0) [0|255] ""  GW_A
 SG_ APA_slot_ID_8_P0_X : 15|14@0+ (1,0) [0|16383] ""  GW_A
 SG_ APA_slot_ID_8_P0_Y : 17|14@0+ (1,0) [0|16383] ""  GW_A
 SG_ APA_slot_ID_8_P1_X : 35|14@0+ (1,0) [0|16383] ""  GW_A
 SG_ APA_slot_ID_8_P1_Y : 53|14@0+ (1,0) [0|16383] ""  GW_A

BO_ 952 ADAS_APA_slot_Info16: 8 ADAS
 SG_ APA_slot_ID_8_Type : 7|2@0+ (1,0) [0|3] ""  GW_A
 SG_ APA_slot_ID_8_P2_X : 5|14@0+ (1,0) [0|16383] ""  GW_A
 SG_ APA_slot_ID_8_P2_Y : 21|14@0+ (1,0) [0|16383] ""  GW_A
 SG_ APA_slot_ID_8_P3_X : 37|14@0+ (1,0) [0|16383] ""  GW_A
 SG_ APA_slot_ID_8_P3_Y : 53|14@0+ (1,0) [0|16383] ""  GW_A

BO_ 937 ADAS_APA_slot_Info17: 8 ADAS
 SG_ APA_slot_9 : 7|8@0+ (1,0) [0|255] ""  GW_A
 SG_ APA_slot_ID_9_P0_X : 15|14@0+ (1,0) [0|16383] ""  GW_A
 SG_ APA_slot_ID_9_P0_Y : 17|14@0+ (1,0) [0|16383] ""  GW_A
 SG_ APA_slot_ID_9_P1_X : 35|14@0+ (1,0) [0|16383] ""  GW_A
 SG_ APA_slot_ID_9_P1_Y : 53|14@0+ (1,0) [0|16383] ""  GW_A

BO_ 953 ADAS_APA_slot_Info18: 8 ADAS
 SG_ APA_slot_ID_9_Type : 7|2@0+ (1,0) [0|3] ""  GW_A
 SG_ APA_slot_ID_9_P2_X : 5|14@0+ (1,0) [0|16383] ""  GW_A
 SG_ APA_slot_ID_9_P2_Y : 21|14@0+ (1,0) [0|16383] ""  GW_A
 SG_ APA_slot_ID_9_P3_X : 37|14@0+ (1,0) [0|16383] ""  GW_A
 SG_ APA_slot_ID_9_P3_Y : 53|14@0+ (1,0) [0|16383] ""  GW_A

BO_ 938 ADAS_APA_slot_Info19: 8 ADAS
 SG_ APA_slot_10 : 7|8@0+ (1,0) [0|255] ""  GW_A
 SG_ APA_slot_ID_10_P0_X : 15|14@0+ (1,0) [0|16383] ""  GW_A
 SG_ APA_slot_ID_10_P0_Y : 17|14@0+ (1,0) [0|16383] ""  GW_A
 SG_ APA_slot_ID_10_P1_X : 35|14@0+ (1,0) [0|16383] ""  GW_A
 SG_ APA_slot_ID_10_P1_Y : 53|14@0+ (1,0) [0|16383] ""  GW_A

BO_ 954 ADAS_APA_slot_Info20: 8 ADAS
 SG_ APA_slot_ID_10_Type : 7|2@0+ (1,0) [0|3] ""  GW_A
 SG_ APA_slot_ID_10_P2_X : 5|14@0+ (1,0) [0|16383] ""  GW_A
 SG_ APA_slot_ID_10_P2_Y : 21|14@0+ (1,0) [0|16383] ""  GW_A
 SG_ APA_slot_ID_10_P3_X : 37|14@0+ (1,0) [0|16383] ""  GW_A
 SG_ APA_slot_ID_10_P3_Y : 53|14@0+ (1,0) [0|16383] ""  GW_A

BO_ 939 ADAS_APA_slot_Info21: 8 ADAS
 SG_ APA_slot_11 : 7|8@0+ (1,0) [0|255] ""  GW_A
 SG_ APA_slot_ID_11_P0_X : 15|14@0+ (1,0) [0|16383] ""  GW_A
 SG_ APA_slot_ID_11_P0_Y : 17|14@0+ (1,0) [0|16383] ""  GW_A
 SG_ APA_slot_ID_11_P1_X : 35|14@0+ (1,0) [0|16383] ""  GW_A
 SG_ APA_slot_ID_11_P1_Y : 53|14@0+ (1,0) [0|16383] ""  GW_A

BO_ 955 ADAS_APA_slot_Info22: 8 ADAS
 SG_ APA_slot_ID_11_Type : 7|2@0+ (1,0) [0|3] ""  GW_A
 SG_ APA_slot_ID_11_P2_X : 5|14@0+ (1,0) [0|16383] ""  GW_A
 SG_ APA_slot_ID_11_P2_Y : 21|14@0+ (1,0) [0|16383] ""  GW_A
 SG_ APA_slot_ID_11_P3_X : 37|14@0+ (1,0) [0|16383] ""  GW_A
 SG_ APA_slot_ID_11_P3_Y : 53|14@0+ (1,0) [0|16383] ""  GW_A

BO_ 940 ADAS_APA_slot_Info23: 8 ADAS
 SG_ APA_slot_12 : 7|8@0+ (1,0) [0|255] ""  GW_A
 SG_ APA_slot_ID_12_P0_X : 15|14@0+ (1,0) [0|16383] ""  GW_A
 SG_ APA_slot_ID_12_P0_Y : 17|14@0+ (1,0) [0|16383] ""  GW_A
 SG_ APA_slot_ID_12_P1_X : 35|14@0+ (1,0) [0|16383] ""  GW_A
 SG_ APA_slot_ID_12_P1_Y : 53|14@0+ (1,0) [0|16383] ""  GW_A

BO_ 956 ADAS_APA_slot_Info24: 8 ADAS
 SG_ APA_slot_ID_12_Type : 7|2@0+ (1,0) [0|3] ""  GW_A
 SG_ APA_slot_ID_12_P2_X : 5|14@0+ (1,0) [0|16383] ""  GW_A
 SG_ APA_slot_ID_12_P2_Y : 21|14@0+ (1,0) [0|16383] ""  GW_A
 SG_ APA_slot_ID_12_P3_X : 37|14@0+ (1,0) [0|16383] ""  GW_A
 SG_ APA_slot_ID_12_P3_Y : 53|14@0+ (1,0) [0|16383] ""  GW_A

BO_ 496 MHU_ADSA01: 8 GW_A
 SG_ MHU_APA_Req : 1|2@0+ (1,0) [0|3] ""  ADAS,CRL
 SG_ MHU_APA_ParkIn_Req : 3|2@0+ (1,0) [0|3] ""  ADAS,CRL
 SG_ MHU_APA_ParkOut_Req : 5|2@0+ (1,0) [0|3] ""  ADAS,CRL
 SG_ MHU_APA_ParkingStart_Req : 7|2@0+ (1,0) [0|3] ""  ADAS,CRL
 SG_ MHU_APA_ParkingReCover_Req : 9|2@0+ (1,0) [0|3] ""  ADAS,CRL
 SG_ MHU_APA_ParkOut_Direction : 11|2@0+ (1,0) [0|3] ""  ADAS,CRL
 SG_ MHU_APA_ParkOut_Mode : 14|3@0+ (1,0) [0|7] ""  ADAS,CRL
 SG_ MHU_LSS_Req : 29|2@0+ (1,0) [0|3] ""  ADAS,CRL
 SG_ MHU_LSS_Mode : 31|2@0+ (1,0) [0|3] ""  ADAS,CRL
 SG_ MHU_LSS_WarningMethod : 33|2@0+ (1,0) [0|3] ""  ADAS,CRL
 SG_ MHU_TSR_Req : 35|2@0+ (1,0) [0|3] ""  ADAS,CRL
 SG_ TSR_SpdWarningOffs_S : 39|4@0+ (1,0) [0|15] ""  ADAS,CRL
 SG_ TSR_SLWFuncSwtReq : 41|2@0+ (1,0) [0|3] ""  ADAS,CRL
 SG_ AEB_FuncSwtReq : 43|2@0+ (1,0) [0|3] ""  ADAS,CRL
 SG_ AEB_FCW_SnvtyReq : 46|3@0+ (1,0) [0|7] ""  ADAS,CRL
 SG_ BSD_LCA_FuncSWReq : 49|2@0+ (1,0) [0|3] ""  ADAS,CRL
 SG_ RCTA_FuncSWReq : 51|2@0+ (1,0) [0|3] ""  ADAS,CRL
 SG_ DOW_FuncSWReq : 53|2@0+ (1,0) [0|3] ""  ADAS,CRL
 SG_ RCW_FuncSWReq : 55|2@0+ (1,0) [0|3] ""  ADAS,CRL
 SG_ MHU_APA_ParkingSpace_ID : 63|8@0+ (1,0) [0|255] ""  ADAS,CRL

BO_ 497 MHU_ADAS02: 8 GW_A
 SG_ Nav_RoadType : 7|4@0+ (1,0) [0|15] ""  ADAS
 SG_ Nav_errorSts : 3|1@0+ (1,0) [0|1] ""  ADAS
 SG_ Nav_VehToTrafEyeDist : 1|10@0+ (1,0) [0|1000] "m"  ADAS
 SG_ Nav_SpdLimValue : 21|6@0+ (1,0) [0|63] ""  ADAS
 SG_ Nav_SpdLimType : 23|2@0+ (1,0) [0|3] ""  ADAS
 SG_ Nav_SpdLimUnit : 25|2@0+ (1,0) [0|3] ""  ADAS
 SG_ Nav_TSRTrafSign : 37|6@0+ (1,0) [0|63] ""  ADAS
 SG_ Nav_CtryType : 47|8@0+ (1,0) [0|255] ""  ADAS

BO_ 498 MHU_ADAS03: 8 GW_A
 SG_ Nav_TimeMod : 0|1@0+ (1,0) [0|1] ""  ADAS
 SG_ Nav_TimeIndcn : 5|2@0+ (1,0) [0|3] ""  ADAS

BO_ 514 BCM_WindowSts: 8 GW_A
 SG_ BCM_FLWin_Postion : 19|4@0+ (1,0) [0|15] ""  ADAS
 SG_ BCM_FRWin_Postion : 23|4@0+ (1,0) [0|15] ""  ADAS
 SG_ BCM_RLWinIN_Postion : 27|4@0+ (1,0) [0|15] ""  ADAS
 SG_ BCM_RRWin_Postion : 31|4@0+ (1,0) [0|15] ""  ADAS
 SG_ BCM_WinLockSts : 36|1@0+ (1,0) [0|1] ""  ADAS
 SG_ BCM_RLWinAntipinchSts : 40|1@0+ (1,0) [0|1] ""  ADAS
 SG_ BCM_RRWinAntipinchSts : 42|1@0+ (1,0) [0|1] ""  ADAS
 SG_ BCM_FLWinAntipinchSts : 44|1@0+ (1,0) [0|1] ""  ADAS
 SG_ BCM_FRWinAntipinchSts : 46|1@0+ (1,0) [0|1] ""  ADAS
 SG_ BCM_FrontWipeSWSts : 50|3@0+ (1,0) [0|7] ""  ADAS
 SG_ BCM_AutoWipeSts : 51|1@0+ (1,0) [0|1] ""  ADAS
 SG_ BCM_FrontWipeSts : 53|2@0+ (1,0) [0|3] ""  ADAS
 SG_ BCM_FrontWipeReturn : 54|1@0+ (1,0) [0|1] ""  ADAS
 SG_ BCM_FrontWinWashSWSts : 55|1@0+ (1,0) [0|1] ""  ADAS
 SG_ BCM_RearWipeSWSts : 58|3@0+ (1,0) [0|7] ""  ADAS
 SG_ BCM_RearWipeSts : 61|2@0+ (1,0) [0|3] ""  ADAS
 SG_ BCM_RearWipeReturn : 62|1@0+ (1,0) [0|1] ""  ADAS
 SG_ BCM_RearWinWashSWSts : 63|1@0+ (1,0) [0|1] ""  ADAS

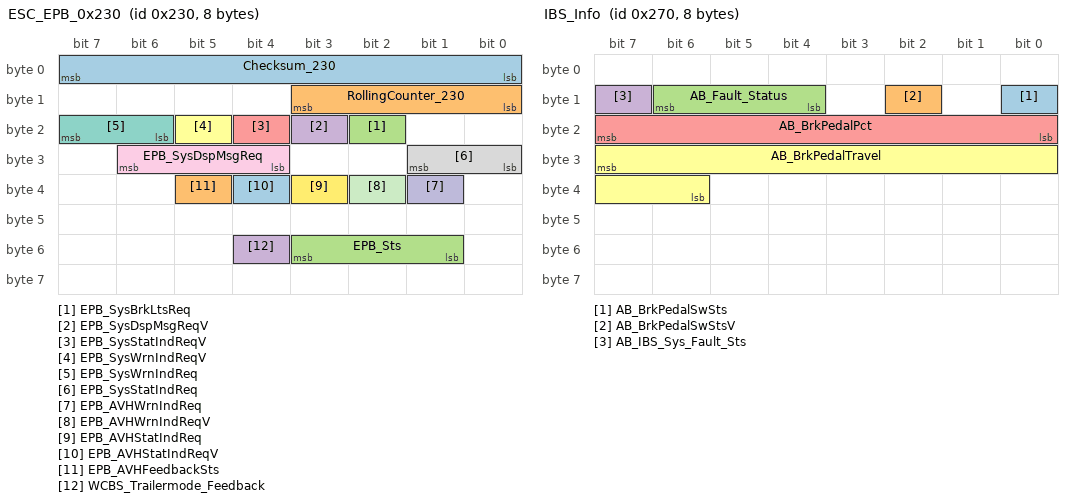
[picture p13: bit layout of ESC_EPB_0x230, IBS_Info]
BO_ 560 ESC_EPB_0x230: 8 GW_A
 SG_ Checksum_230 : 7|8@0+ (1,0) [0|255] ""  CRR,ADAS,CRL,MRR,PDC
 SG_ RollingCounter_230 : 11|4@0+ (1,0) [0|15] ""  CRR,ADAS,CRL,MRR,PDC
 SG_ EPB_SysBrkLtsReq : 18|1@0+ (1,0) [0|1] ""  CRR,ADAS,CRL,MRR,PDC
 SG_ EPB_SysDspMsgReqV : 19|1@0+ (1,0) [0|1] ""  CRR,ADAS,CRL,MRR,PDC
 SG_ EPB_SysStatIndReqV : 20|1@0+ (1,0) [0|1] ""  CRR,ADAS,CRL,MRR,PDC
 SG_ EPB_SysWrnIndReqV : 21|1@0+ (1,0) [0|1] ""  CRR,ADAS,CRL,MRR,PDC
 SG_ EPB_SysWrnIndReq : 23|2@0+ (1,0) [0|3] ""  CRR,ADAS,CRL,MRR,PDC
 SG_ EPB_SysStatIndReq : 25|2@0+ (1,0) [0|3] ""  CRR,ADAS,CRL,MRR,PDC
 SG_ EPB_SysDspMsgReq : 30|3@0+ (1,0) [0|7] ""  CRR,ADAS,CRL,MRR,PDC
 SG_ EPB_AVHWrnIndReq : 33|1@0+ (1,0) [0|1] ""  CRR,ADAS,CRL,MRR,PDC
 SG_ EPB_AVHWrnIndReqV : 34|1@0+ (1,0) [0|1] ""  CRR,ADAS,CRL,MRR,PDC
 SG_ EPB_AVHStatIndReq : 35|1@0+ (1,0) [0|1] ""  CRR,ADAS,CRL,MRR,PDC
 SG_ EPB_AVHStatIndReqV : 36|1@0+ (1,0) [0|1] ""  CRR,ADAS,CRL,MRR,PDC
 SG_ EPB_AVHFeedbackSts : 37|1@0+ (1,0) [0|1] ""  CRR,ADAS,CRL,MRR,PDC
 SG_ EPB_Sts : 51|3@0+ (1,0) [0|7] ""  CRR,ADAS,CRL,MRR,PDC
 SG_ WCBS_Trailermode_Feedback : 52|1@0+ (1,0) [0|1] ""  CRR,ADAS,CRL,MRR,PDC

BO_ 617 IBS_ADAS_Info: 8 GW_A
 SG_ WCBS_ACC_VLC_Active : 4|1@0+ (1,0) [0|1] ""  ADAS
 SG_ WCBS_ACC_CDD_Active : 5|1@0+ (1,0) [0|1] ""  ADAS
 SG_ WCBS_ACC_VLC_Avl : 6|1@0+ (1,0) [0|1] ""  ADAS
 SG_ WCBS_ACC_CDD_Avl : 7|1@0+ (1,0) [0|1] ""  ADAS
 SG_ WCBS_ACC_VLC_AccInTar : 3|12@0+ (0.003125,-7) [-7|5] "m/s2"  ADAS
 SG_ WCBS_ABAAtv : 28|1@0+ (1,0) [0|1] ""  ADAS
 SG_ WCBS_ABAAva : 29|1@0+ (1,0) [0|1] ""  ADAS
 SG_ WCBS_ABPAtv : 30|1@0+ (1,0) [0|1] ""  ADAS
 SG_ WCBS_ABPAva : 31|1@0+ (1,0) [0|1] ""  ADAS
 SG_ WCBS_AWBAtv : 32|1@0+ (1,0) [0|1] ""  ADAS
 SG_ WCBS_AWBAvl : 33|1@0+ (1,0) [0|1] ""  ADAS
 SG_ WCBS_AEBAtv : 34|1@0+ (1,0) [0|1] ""  ADAS
 SG_ WCBS_AEBAva : 35|1@0+ (1,0) [0|1] ""  ADAS
 SG_ WCBS_VStandstillSta : 37|2@0+ (1,0) [0|3] ""  ADAS
 SG_ WCBS_BrkFrcSta : 38|1@0+ (1,0) [0|1] ""  ADAS
 SG_ WCBS_ESCDeteACCErroSta : 47|2@0+ (1,0) [0|3] ""  ADAS
 SG_ WCBS_APA_VLC_FailureStatus : 51|4@0+ (1,0) [0|15] ""  ADAS
 SG_ WCBS_APA_VLC_Status : 54|3@0+ (1,0) [0|7] ""  ADAS
 SG_ WCBS_APA_VLC_Available : 56|1@0+ (1,0) [0|1] ""  ADAS
 SG_ WCBS_APA_VLC_Active : 57|1@0+ (1,0) [0|1] ""  ADAS
 SG_ WCBS_APA_EmgyBrkAvlb : 58|1@0+ (1,0) [0|1] ""  ADAS
 SG_ WCBS_APA_CDD_Active : 59|1@0+ (1,0) [0|1] ""  ADAS

BO_ 624 IBS_Info: 8 GW_A
 SG_ AB_BrkPedalSwSts : 8|1@0+ (1,0) [0|1] ""  ADAS
 SG_ AB_BrkPedalSwStsV : 10|1@0+ (1,0) [0|1] ""  ADAS
 SG_ AB_Fault_Status : 14|3@0+ (1,0) [0|7] ""  ADAS
 SG_ AB_IBS_Sys_Fault_Sts : 15|1@0+ (1,0) [0|1] ""  ADAS
 SG_ AB_BrkPedalPct : 23|8@0+ (0.4,0) [0|100] "%"  ADAS
 SG_ AB_BrkPedalTravel : 31|10@0+ (0.1,0) [0|100] "%"  ADAS

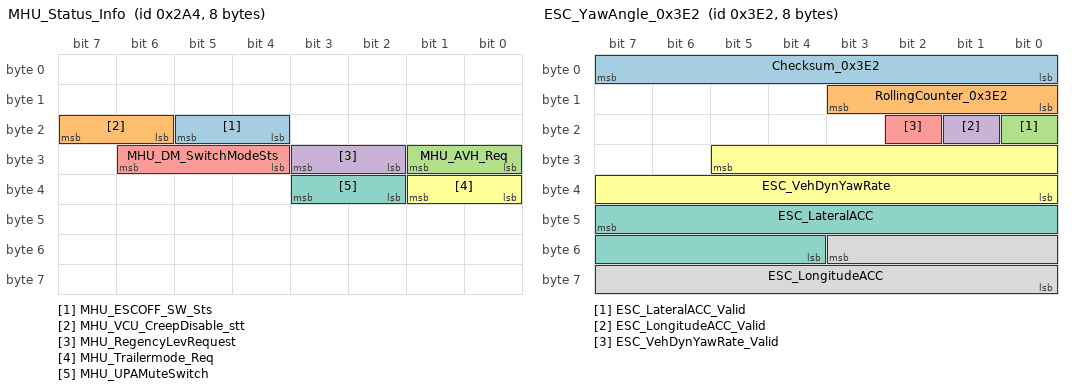
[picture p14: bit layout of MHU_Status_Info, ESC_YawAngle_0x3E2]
BO_ 676 MHU_Status_Info: 8 GW_A
 SG_ MHU_ESCOFF_SW_Sts : 21|2@0+ (1,0) [0|3] ""  ADAS
 SG_ MHU_VCU_CreepDisable_stt : 23|2@0+ (1,0) [0|3] ""  ADAS
 SG_ MHU_AVH_Req : 25|2@0+ (1,0) [0|3] ""  ADAS
 SG_ MHU_RegencyLevRequest : 27|2@0+ (1,0) [0|3] ""  ADAS
 SG_ MHU_DM_SwitchModeSts : 30|3@0+ (1,0) [0|7] ""  ADAS
 SG_ MHU_Trailermode_Req : 33|2@0+ (1,0) [0|3] ""  ADAS
 SG_ MHU_UPAMuteSwitch : 35|2@0+ (1,0) [0|3] ""  ADAS

BO_ 994 ESC_YawAngle_0x3E2: 8 WCBS
 SG_ Checksum_0x3E2 : 7|8@0+ (1,0) [0|255] ""  CRR,ADAS,CRL,MRR
 SG_ RollingCounter_0x3E2 : 11|4@0+ (1,0) [0|15] ""  CRR,ADAS,CRL,MRR
 SG_ ESC_LateralACC_Valid : 16|1@0+ (1,0) [0|1] ""  CRR,ADAS,CRL,MRR
 SG_ ESC_LongitudeACC_Valid : 17|1@0+ (1,0) [0|1] ""  CRR,ADAS,CRL,MRR
 SG_ ESC_VehDynYawRate_Valid : 18|1@0+ (1,0) [0|1] ""  CRR,ADAS,CRL,MRR
 SG_ ESC_VehDynYawRate : 29|14@0+ (0.03125,-256) [-256|255.96875] "deg/s"  CRR,ADAS,CRL,MRR
 SG_ ESC_LateralACC : 47|12@0+ (0.01,-20) [-20|20] "m/s2"  CRR,ADAS,CRL,MRR
 SG_ ESC_LongitudeACC : 51|12@0+ (0.01,-20) [-20|20] "m/s2"  CRR,ADAS,CRL,MRR

BO_ 1009 IPC_TotalOdometer: 8 GW_A
 SG_ IPC_IPCTotalOdometer : 7|24@0+ (0.1,0) [0|999999] "km"  CRR,ADAS,CRL,MRR,PDC
 SG_ IPC_IPCTotalOdometerV : 24|1@0+ (1,0) [0|1] ""  CRR,ADAS,CRL,MRR,PDC
 SG_ IPC_Remain_Maintenance : 39|16@0+ (1,0) [0|50000] "km"  CRR,ADAS,CRL,MRR,PDC
 SG_ RollingCounter_0x3F1 : 51|4@0+ (1,0) [0|15] ""  CRR,ADAS,CRL,MRR,PDC
 SG_ CheckSum_0x3F1 : 63|8@0+ (1,0) [0|255] ""  CRR,ADAS,CRL,MRR,PDC

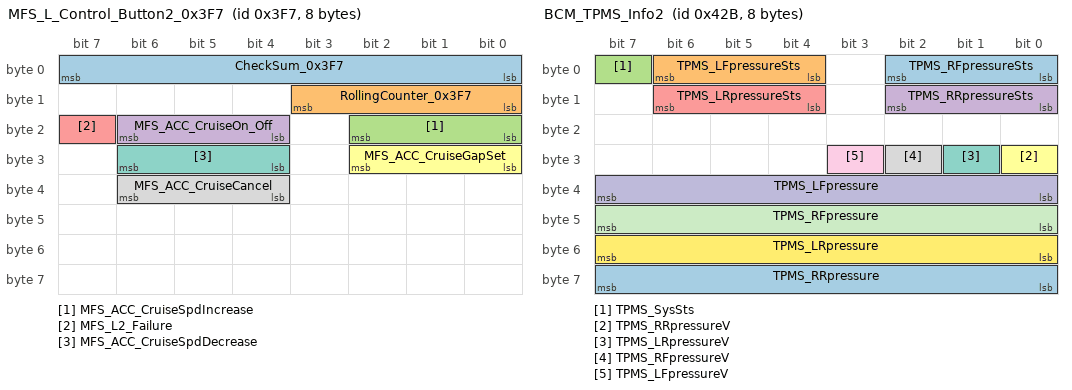
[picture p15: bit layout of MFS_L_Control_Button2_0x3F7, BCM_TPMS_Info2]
BO_ 1015 MFS_L_Control_Button2_0x3F7: 8 GW_A
 SG_ CheckSum_0x3F7 : 7|8@0+ (1,0) [0|255] ""  ADAS
 SG_ RollingCounter_0x3F7 : 11|4@0+ (1,0) [0|15] ""  ADAS
 SG_ MFS_ACC_CruiseSpdIncrease : 18|3@0+ (1,0) [0|7] ""  ADAS
 SG_ MFS_ACC_CruiseOn_Off : 22|3@0+ (1,0) [0|7] ""  ADAS
 SG_ MFS_L2_Failure : 23|1@0+ (1,0) [0|1] ""  ADAS
 SG_ MFS_ACC_CruiseGapSet : 26|3@0+ (1,0) [0|7] ""  ADAS
 SG_ MFS_ACC_CruiseSpdDecrease : 30|3@0+ (1,0) [0|7] ""  ADAS
 SG_ MFS_ACC_CruiseCancel : 38|3@0+ (1,0) [0|7] ""  ADAS

BO_ 1067 BCM_TPMS_Info2: 8 GW_A
 SG_ TPMS_RFpressureSts : 2|3@0+ (1,0) [0|7] ""  ADAS
 SG_ TPMS_LFpressureSts : 6|3@0+ (1,0) [0|7] ""  ADAS
 SG_ TPMS_SysSts : 7|1@0+ (1,0) [0|1] ""  ADAS
 SG_ TPMS_RRpressureSts : 10|3@0+ (1,0) [0|7] ""  ADAS
 SG_ TPMS_LRpressureSts : 14|3@0+ (1,0) [0|7] ""  ADAS
 SG_ TPMS_RRpressureV : 24|1@0+ (1,0) [0|1] ""  ADAS
 SG_ TPMS_LRpressureV : 25|1@0+ (1,0) [0|1] ""  ADAS
 SG_ TPMS_RFpressureV : 26|1@0+ (1,0) [0|1] ""  ADAS
 SG_ TPMS_LFpressureV : 27|1@0+ (1,0) [0|1] ""  ADAS
 SG_ TPMS_LFpressure : 39|8@0+ (0.014,0) [0|3.5] "Bar"  ADAS
 SG_ TPMS_RFpressure : 47|8@0+ (0.014,0) [0|3.5] "Bar"  ADAS
 SG_ TPMS_LRpressure : 55|8@0+ (0.014,0) [0|3.5] "Bar"  ADAS
 SG_ TPMS_RRpressure : 63|8@0+ (0.014,0) [0|3.5] "Bar"  ADAS

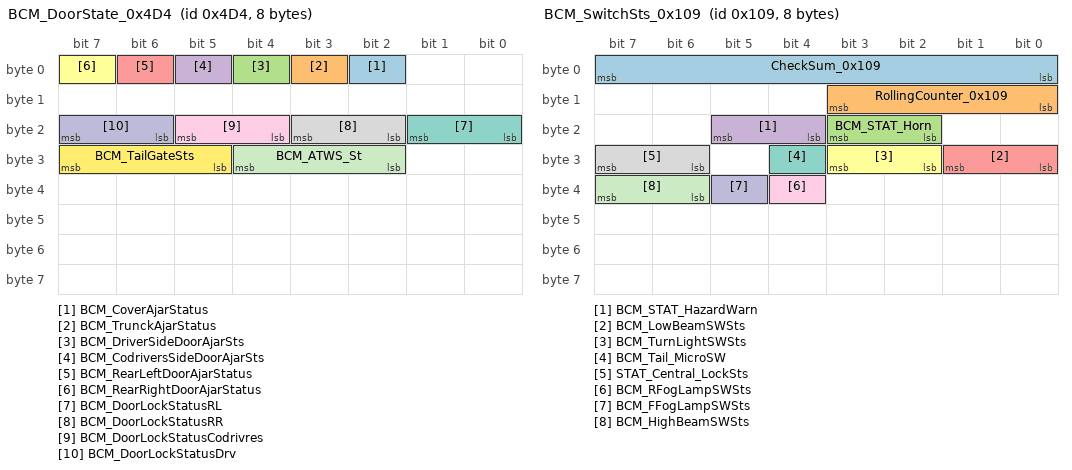
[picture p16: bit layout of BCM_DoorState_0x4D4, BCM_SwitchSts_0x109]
BO_ 1236 BCM_DoorState_0x4D4: 8 GW_A
 SG_ BCM_CoverAjarStatus : 2|1@0+ (1,0) [0|1] ""  CRR,ADAS,CRL,PDC
 SG_ BCM_TrunckAjarStatus : 3|1@0+ (1,0) [0|1] ""  CRR,ADAS,CRL,PDC
 SG_ BCM_DriverSideDoorAjarSts : 4|1@0+ (1,0) [0|1] ""  CRR,ADAS,CRL,PDC
 SG_ BCM_CodriversSideDoorAjarSts : 5|1@0+ (1,0) [0|1] ""  CRR,ADAS,CRL,PDC
 SG_ BCM_RearLeftDoorAjarStatus : 6|1@0+ (1,0) [0|1] ""  CRR,ADAS,CRL,PDC
 SG_ BCM_RearRightDoorAjarStatus : 7|1@0+ (1,0) [0|1] ""  CRR,ADAS,CRL,PDC
 SG_ BCM_DoorLockStatusRL : 17|2@0+ (1,0) [0|3] ""  CRR,ADAS,CRL,PDC
 SG_ BCM_DoorLockStatusRR : 19|2@0+ (1,0) [0|3] ""  CRR,ADAS,CRL,PDC
 SG_ BCM_DoorLockStatusCodrivres : 21|2@0+ (1,0) [0|3] ""  CRR,ADAS,CRL,PDC
 SG_ BCM_DoorLockStatusDrv : 23|2@0+ (1,0) [0|3] ""  CRR,ADAS,CRL,PDC
 SG_ BCM_ATWS_St : 28|3@0+ (1,0) [0|7] ""  CRR,ADAS,CRL,PDC
 SG_ BCM_TailGateSts : 31|3@0+ (1,0) [0|7] ""  CRR,ADAS,CRL,PDC

BO_ 265 BCM_SwitchSts_0x109: 8 GW_A
 SG_ CheckSum_0x109 : 7|8@0+ (1,0) [0|255] ""  CRR,ADAS,CRL,PDC
 SG_ RollingCounter_0x109 : 11|4@0+ (1,0) [0|15] ""  CRR,ADAS,CRL,PDC
 SG_ BCM_STAT_Horn : 19|2@0+ (1,0) [0|3] ""  CRR,ADAS,CRL,PDC
 SG_ BCM_STAT_HazardWarn : 21|2@0+ (1,0) [0|3] ""  CRR,ADAS,CRL,PDC
 SG_ BCM_LowBeamSWSts : 25|2@0+ (1,0) [0|3] ""  CRR,ADAS,CRL,PDC
 SG_ BCM_TurnLightSWSts : 27|2@0+ (1,0) [0|3] ""  CRR,ADAS,CRL,PDC
 SG_ BCM_Tail_MicroSW : 28|1@0+ (1,0) [0|1] ""  CRR,ADAS,CRL,PDC
 SG_ STAT_Central_LockSts : 31|2@0+ (1,0) [0|3] ""  CRR,ADAS,CRL,PDC
 SG_ BCM_RFogLampSWSts : 36|1@0+ (1,0) [0|1] ""  CRR,ADAS,CRL,PDC
 SG_ BCM_FFogLampSWSts : 37|1@0+ (1,0) [0|1] ""  CRR,ADAS,CRL,PDC
 SG_ BCM_HighBeamSWSts : 39|2@0+ (1,0) [0|3] ""  CRR,ADAS,CRL,PDC

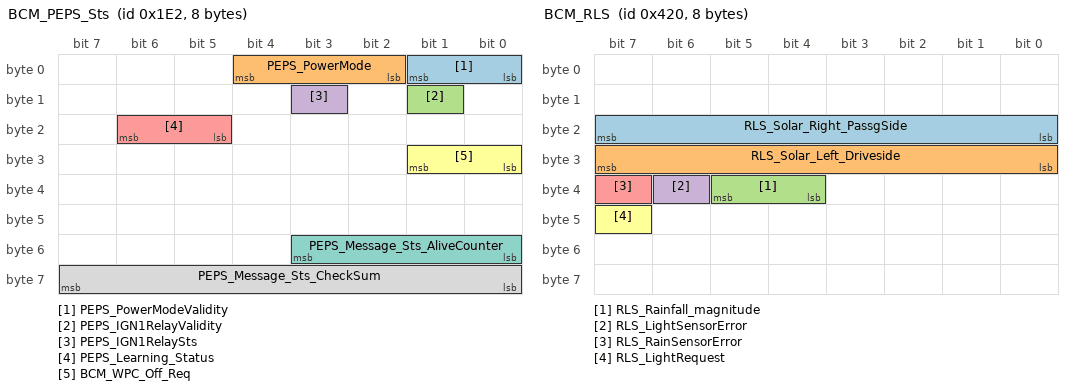
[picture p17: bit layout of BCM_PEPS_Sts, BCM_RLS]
BO_ 482 BCM_PEPS_Sts: 8 GW_A
 SG_ PEPS_PowerModeValidity : 1|2@0+ (1,0) [0|3] ""  CRR,ADAS,CRL,MRR
 SG_ PEPS_PowerMode : 4|3@0+ (1,0) [0|7] ""  CRR,ADAS,CRL,MRR
 SG_ PEPS_IGN1RelayValidity : 9|1@0+ (1,0) [0|1] ""  CRR,ADAS,CRL,MRR
 SG_ PEPS_IGN1RelaySts : 11|1@0+ (1,0) [0|1] ""  CRR,ADAS,CRL,MRR
 SG_ PEPS_Learning_Status : 22|2@0+ (1,0) [0|3] ""  CRR,ADAS,CRL,MRR
 SG_ BCM_WPC_Off_Req : 25|2@0+ (1,0) [0|3] ""  CRR,ADAS,CRL,MRR
 SG_ PEPS_Message_Sts_AliveCounter : 51|4@0+ (1,0) [0|15] ""  CRR,ADAS,CRL,MRR
 SG_ PEPS_Message_Sts_CheckSum : 63|8@0+ (1,0) [0|255] ""  CRR,ADAS,CRL,MRR

BO_ 1056 BCM_RLS: 8 GW_A
 SG_ RLS_Solar_Right_PassgSide : 23|8@0+ (5,0) [0|1200] "W/m2"  ADAS,PDC
 SG_ RLS_Solar_Left_Driveside : 31|8@0+ (5,0) [0|1200] "W/m2"  ADAS,PDC
 SG_ RLS_Rainfall_magnitude : 37|2@0+ (1,0) [0|3] ""  ADAS,PDC
 SG_ RLS_LightSensorError : 38|1@0+ (1,0) [0|1] ""  ADAS,PDC
 SG_ RLS_RainSensorError : 39|1@0+ (1,0) [0|1] ""  ADAS,PDC
 SG_ RLS_LightRequest : 47|1@0+ (1,0) [0|1] ""  ADAS,PDC

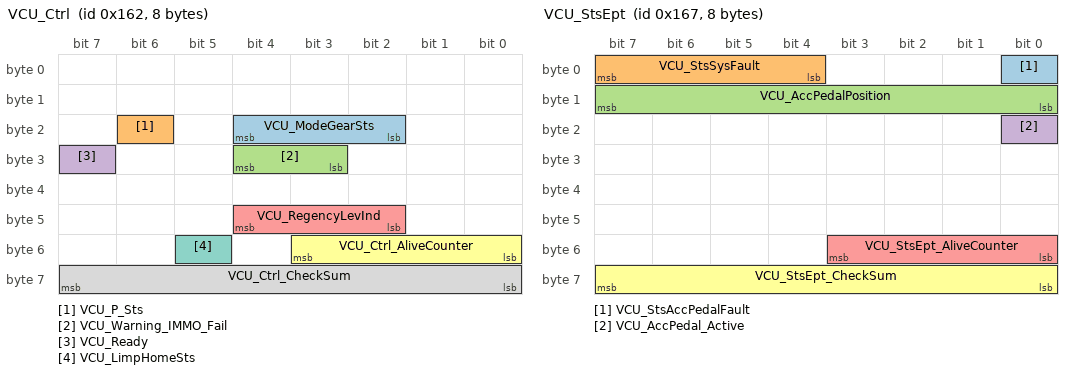
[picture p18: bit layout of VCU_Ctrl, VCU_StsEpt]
BO_ 354 VCU_Ctrl: 8 VCU
 SG_ VCU_ModeGearSts : 20|3@0+ (1,0) [0|7] ""  CRR,ADAS,CRL,MRR,PDC
 SG_ VCU_P_Sts : 22|1@0+ (1,0) [0|1] ""  CRR,ADAS,CRL,MRR,PDC
 SG_ VCU_Warning_IMMO_Fail : 28|2@0+ (1,0) [0|3] ""  CRR,ADAS,CRL,MRR,PDC
 SG_ VCU_Ready : 31|1@0+ (1,0) [0|1] ""  CRR,ADAS,CRL,MRR,PDC
 SG_ VCU_RegencyLevInd : 44|3@0+ (1,0) [0|7] ""  CRR,ADAS,CRL,MRR,PDC
 SG_ VCU_Ctrl_AliveCounter : 51|4@0+ (1,0) [0|15] ""  CRR,ADAS,CRL,MRR,PDC
 SG_ VCU_LimpHomeSts : 53|1@0+ (1,0) [0|1] ""  CRR,ADAS,CRL,MRR,PDC
 SG_ VCU_Ctrl_CheckSum : 63|8@0+ (1,0) [0|255] ""  CRR,ADAS,CRL,MRR,PDC

BO_ 359 VCU_StsEpt: 8 VCU
 SG_ VCU_StsAccPedalFault : 0|1@0+ (1,0) [0|1] ""  ADAS
 SG_ VCU_StsSysFault : 7|4@0+ (1,0) [0|15] ""  ADAS
 SG_ VCU_AccPedalPosition : 15|8@0+ (0.4,0) [0|100] ""  ADAS
 SG_ VCU_AccPedal_Active : 16|1@0+ (1,0) [0|1] ""  ADAS
 SG_ VCU_StsEpt_AliveCounter : 51|4@0+ (1,0) [0|15] ""  ADAS
 SG_ VCU_StsEpt_CheckSum : 63|8@0+ (1,0) [0|255] ""  ADAS

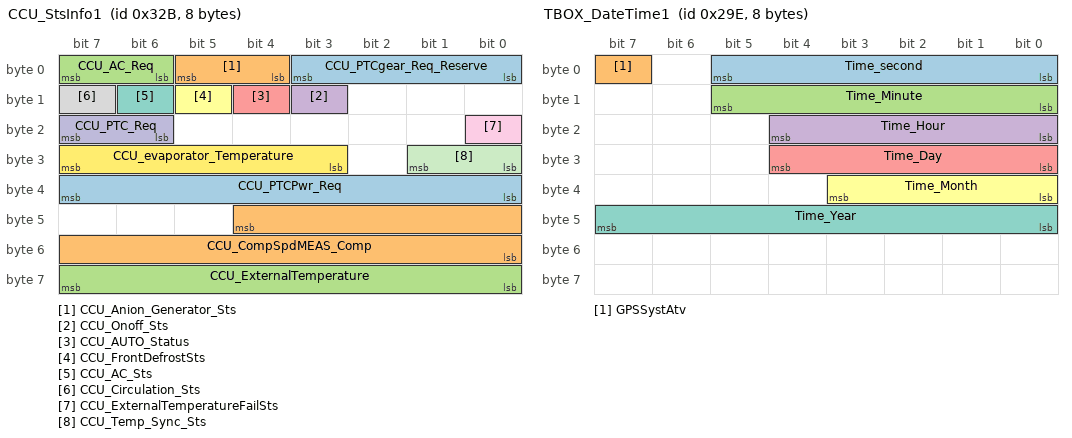
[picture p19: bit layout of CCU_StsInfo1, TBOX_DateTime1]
BO_ 811 CCU_StsInfo1: 8 GW_A
 SG_ CCU_PTCgear_Req_Reserve : 3|4@0+ (1,0) [0|15] ""  ADAS,PDC
 SG_ CCU_Anion_Generator_Sts : 5|2@0+ (1,0) [0|3] ""  ADAS,PDC
 SG_ CCU_AC_Req : 7|2@0+ (1,0) [0|3] ""  ADAS,PDC
 SG_ CCU_Onoff_Sts : 11|1@0+ (1,0) [0|1] ""  ADAS,PDC
 SG_ CCU_AUTO_Status : 12|1@0+ (1,0) [0|1] ""  ADAS,PDC
 SG_ CCU_FrontDefrostSts : 13|1@0+ (1,0) [0|1] ""  ADAS,PDC
 SG_ CCU_AC_Sts : 14|1@0+ (1,0) [0|1] ""  ADAS,PDC
 SG_ CCU_Circulation_Sts : 15|1@0+ (1,0) [0|1] ""  ADAS,PDC
 SG_ CCU_ExternalTemperatureFailSts : 16|1@0+ (1,0) [0|1] ""  ADAS,PDC
 SG_ CCU_PTC_Req : 23|2@0+ (1,0) [0|3] ""  ADAS,PDC
 SG_ CCU_Temp_Sync_Sts : 25|2@0+ (1,0) [0|3] ""  ADAS,PDC
 SG_ CCU_evaporator_Temperature : 31|5@0+ (1,-10) [-10|15] "°C"  ADAS,PDC
 SG_ CCU_PTCPwr_Req : 39|8@0+ (0.1,0) [0|10] "KW"  ADAS,PDC
 SG_ CCU_CompSpdMEAS_Comp : 44|13@0+ (1,0) [0|8191] "rpm"  ADAS,PDC
 SG_ CCU_ExternalTemperature : 63|8@0+ (0.5,-40) [-40|87] "°C"  ADAS,PDC

BO_ 670 TBOX_DateTime1: 8 GW_A
 SG_ Time_second : 5|6@0+ (1,0) [0|59] "second"  CRR,ADAS,CRL,MRR,PDC
 SG_ GPSSystAtv : 7|1@0+ (1,0) [0|1] ""  CRR,ADAS,CRL,MRR,PDC
 SG_ Time_Minute : 13|6@0+ (1,0) [0|59] "min"  CRR,ADAS,CRL,MRR,PDC
 SG_ Time_Hour : 20|5@0+ (1,0) [0|23] "hour"  CRR,ADAS,CRL,MRR,PDC
 SG_ Time_Day : 28|5@0+ (1,0) [1|31] "day"  CRR,ADAS,CRL,MRR,PDC
 SG_ Time_Month : 35|4@0+ (1,0) [1|12] "month"  CRR,ADAS,CRL,MRR,PDC
 SG_ Time_Year : 47|8@0+ (1,2000) [2000|2200] "year"  CRR,ADAS,CRL,MRR,PDC

BO_ 1760 VCA_NM: 8 VCU
 SG_ VCU_ECUAddress : 7|8@0+ (1,0) [0|255] ""  ADAS,CRL
 SG_ VCU_CBV : 15|8@0+ (1,0) [0|255] ""  ADAS,CRL
 SG_ VCU_NM_Ststus : 22|7@0+ (1,0) [0|127] ""  ADAS,CRL
 SG_ VCU_Awaken_Reason : 31|8@0+ (1,0) [0|255] ""  ADAS,CRL

BO_ 1713 ADAS_NM: 8 ADAS
 SG_ ADAS_ECUAddress : 7|8@0+ (1,0) [0|255] ""  CRL,VCU
 SG_ ADAS_CBV : 15|8@0+ (1,0) [0|255] ""  CRL,VCU
 SG_ ADAS_NM_Ststus : 22|7@0+ (1,0) [0|127] ""  CRL,VCU
 SG_ ADAS_Awaken_Reason : 31|8@0+ (1,0) [0|255] ""  CRL,VCU

BO_ 1718 CRL_NM: 8 CRL
 SG_ CRL_ECUAddress : 7|8@0+ (1,0) [0|255] ""  VCU
 SG_ CRL_CBV : 15|8@0+ (1,0) [0|255] ""  VCU
 SG_ CRL_NM_Status : 22|7@0+ (1,0) [0|127] ""  VCU
 SG_ CRL_Awaken_Reason : 31|8@0+ (1,0) [0|255] ""  VCU

BO_ 1969 UDS_PhyDiagReq_ADAS: 8 Tester
 SG_ Diag_PhyReq : 7|64@0+ (1,0) [0|0] ""  ADAS

BO_ 1977 UDS_DiagResp_PNG: 8 ADAS
 SG_ Diag_PhyResp : 7|64@0+ (1,0) [0|0] ""  Tester

BO_ 2015 UDS_FuncDiagReq: 8 Tester
 SG_ Diag_FuncReq : 7|64@0+ (1,0) [0|0] ""  ADAS

CM_ SG_ 128 ACU_CoDSeatOccupSensorStat "Signal from ACU for Passenter seat belt warning indicator
ACU信号提示副驾驶承重信号";
CM_ SG_ 128 ACU_DSeatOccupSensorStat "Signal from ACU for Driver seat belt warning indicator(Reserve)
ACU信号提示主驾驶承重信号（保留）";
CM_ SG_ 128 ACU_CoDSeatbeltBucklestatus "Signal from ACU for CoDriver seat belt warning indicator
ACU信号提示副驾驶安全带未系";
CM_ SG_ 128 ACU_DSeatbeltBucklestatus "Signal from ACU for Driver seat belt warning indicator
ACU信号提示主驾驶安全带未系";
CM_ SG_ 128 ACU_CoDAirbagStatus "Signal from ACU for CoDriver seat on/off indicator 
ACU信号提示副驾驶座安全气囊状态";
CM_ SG_ 128 ACU_DAirbagStatus "Signal from ACU for Driver seat on/off indicator 
ACU信号提示主驾驶座安全气囊状态";
CM_ SG_ 128 ACU_RPSeatOccupSensorStat "Signal from ACU for Passenger Right seat belt warning indicator
ACU信号提示右边乘客承重信号";
CM_ SG_ 128 ACU_MPSeatOccupSensorStat "Signal from ACU for Passenger Middle seat warning indicator
ACU信号提示中间乘客承重信号";
CM_ SG_ 128 ACU_LPSeatOccupSensorStat "Signal from ACU for Passenger Left seat belt warning indicator
ACU信号提示左边乘客承重信号";
CM_ SG_ 128 ACU_RCABsts "Right curtain airbag status
右侧帘安全气囊状态";
CM_ SG_ 128 ACU_LCABsts "Left curtain airbag status
左侧帘安全气囊状态";
CM_ SG_ 128 ACU_RSABsts "Right side airbag status
右侧面安全气囊状态";
CM_ SG_ 128 ACU_LSABsts "Left side airbag status
左侧面安全气囊状态";
CM_ SG_ 128 ACU_RPSeatbeltBucklestatus "Signal from ACU for Passenger Right seat belt warning indicator
ACU信号提示右边乘客安全带未系";
CM_ SG_ 128 ACU_MPSeatbeltBucklestatus "Signal from ACU for Passenger Middle seat belt warning indicator
ACU信号提示中间乘客安全带未系";
CM_ SG_ 128 ACU_LPSeatbeltBucklestatus "Signal from ACU for Passenger Left seat belt warning indicator
ACU信号提示左边乘客安全带未系";
CM_ SG_ 128 ACU_CrashSts "Car Crash status
车辆碰撞状态";
CM_ SG_ 128 ACU_CrashRearOutputSts "Rear collision status(reserve)
后方碰撞状态(保留)";
CM_ SG_ 128 ACU_CrashRightOutputSts "Right side collision status
右方碰撞状态";
CM_ SG_ 128 ACU_CrashLeftOutputSts "Left collision status
左方碰撞状态";
CM_ SG_ 128 ACU_CrashFrontOutputSts "Forward collision status
前方碰撞状态";
CM_ SG_ 128 ACU_AirbagWarningStatus "Signal from ACU for Airbag Controll Unit Warning LED status
安全气囊控制单元ACU发出的信号警告LED状态";
CM_ SG_ 128 ACU_CoDSeatbletPTighten "CoDriver seat belt pre-tighten
副驾安全带预紧";
CM_ SG_ 128 ACU_DSeatbletPTighten "Driver seat belt pre-tighten
主驾安全带预紧";
CM_ SG_ 290 ABS_FLWheelSpeedKPH "Signal from ABS to indicate the front left wheel speed in kph";
CM_ SG_ 290 ABS_FLWheelSpeedInvalid "signal to identify if the wheel speed value valid";
CM_ SG_ 290 ABS_FRWheelSpeedKPH "Signal from ABS to indicate the front right wheel speed in kph";
CM_ SG_ 290 ABS_FRWheelSpeedInvalid "signal to identify if the wheel speed value valid";
CM_ SG_ 290 ABS_FLWheelDirection "indicate the front left wheel direction";
CM_ SG_ 290 ABS_FRWheelDirection "indicate the front right wheel direction";
CM_ SG_ 290 ABS_FWSpeMCUKPH_AliveCounter "signal couting the times of this message";
CM_ SG_ 290 ABS_FWSpeMCUKPH_CheckSum "CRC code to check the data integrity";
CM_ SG_ 291 ABS_RLWheelSpeedKPH "Signal from ABS to indicate the rear left wheel speed in kph";
CM_ SG_ 291 ABS_RLWheelSpeedInvalid "signal to identify if the wheel speed value valid";
CM_ SG_ 291 ABS_RRWheelSpeedKPH "Signal from ABS to indicate the rear right wheel speed in kph";
CM_ SG_ 291 ABS_RRWheelSpeedInvalid "signal to identify if the wheel speed value valid";
CM_ SG_ 291 ABS_RLWheelDirection "indicate the rear left wheel direction";
CM_ SG_ 291 ABS_RRWheelDirection "indicate the rear right wheel direction";
CM_ SG_ 291 ABS_RWSpeMCUKPH_AliveCounter "signal couting the times of this message";
CM_ SG_ 291 ABS_RWSpeMCUKPH_CheckSum "CRC code to check the data integrity";
CM_ SG_ 292 ABS_FLWheelSpeedRC "Signal from ABS to indicate the front left wheel speed pulse";
CM_ SG_ 292 ABS_FRWheelSpeedRC "Signal from ABS to indicate the front right wheel speed pulse";
CM_ SG_ 292 ABS_RLWheelSpeedRC "Signal from ABS to indicate the rear left wheel speed pulse";
CM_ SG_ 292 ABS_RRWheelSpeedRC "Signal from ABS to indicate the rear right wheel speed pulse";
CM_ SG_ 292 ABS_FLWheelSpeedRCSts "Signal from ABS to indicate the front left wheel speed pulse";
CM_ SG_ 292 ABS_FRWheelSpeedRCSts "Signal from ABS to indicate the front right wheel speed pulse";
CM_ SG_ 292 ABS_RLWheelSpeedRCSts "Signal from ABS to indicate the rear left wheel speed pulse";
CM_ SG_ 292 ABS_RRWheelSpeedRCSts "Signal from ABS to indicate the rear right wheel speed pulse";
CM_ SG_ 292 ABS_WheelSpeMCURC_AliveCounter "signal couting the times of this message";
CM_ SG_ 292 ABS_WheelSpeMCURC_CheckSum "CRC code to check the data integrity";
CM_ SG_ 262 CheckSum_0x106 "CheckSum_0x106
校验和";
CM_ SG_ 262 RollingCounter_0x106 "RollingCounter_0x106
循环计数";
CM_ SG_ 262 BCM_TurnIndicatorSts "Turn light output  Status
转向灯输出状态";
CM_ SG_ 262 BCM_PosLmpSts "Position light output Status
位置灯输出状态";
CM_ SG_ 262 BCM_LowBeamSts "Low beam output  Status
近光灯输出状态";
CM_ SG_ 262 BCM_HighBeamSts "High beam output Status
远光灯输出状态";
CM_ SG_ 262 BCM_RearFogLampLightSts "Rear Fog Lamp output Status
后雾灯输出状态";
CM_ SG_ 262 BCM_BrakeLightSts "Brake Light output Status
制动灯输出状态";
CM_ SG_ 262 BCM_ReverseLightSts "Reverse light output Status
倒车灯输出状态";
CM_ SG_ 262 BCM_DayRunningLampSts "Daytime Running Lamp output Status
日间行车灯输出状态";
CM_ SG_ 262 BCM_RMarkerLightSts "rear side marker light status
后侧标志灯状态";
CM_ SG_ 262 BCM_Rr_domelampSts "Dimming dome lamp Rear Status
后调光顶灯状态";
CM_ SG_ 262 BCM_Fr_domelampSts "Dimming dome lamp Front Status
前调光顶灯状态";
CM_ SG_ 262 BCM_LicensePlateLightSts "License plate light output
牌照灯输出状态";
CM_ SG_ 262 BCM_HeadLight_adjustSts "Headlight height adjustment Status
大灯高度调节状态";
CM_ SG_ 262 BCM_FrontFogLampLightSts "Front Fog Lamp output Status
前雾灯输出状态";
CM_ SG_ 262 BCM_STAT_InteriorLight "status of backlight illumination
背光照明状态";
CM_ SG_ 262 BCM_STAT_SwLightBrightness "Confirm Brighness level of Switch illumination
确定开关光亮亮度";
CM_ SG_ 262 BCM_TurnLight_FaultSts "Turn light Fault  Status
转向灯故障状态";
CM_ SG_ 262 BCM_AmbeLightZone2Sts "控制副仪表台区域氛围灯状态
Ambient lighting Zone 2 Status";
CM_ SG_ 262 BCM_AmbeLightZone1Sts "控制仪表台区域氛围灯状态
Ambient lighting Zone 1 Status";
CM_ SG_ 293 ABSActive "Signal from ABS/ABS to indicate if ABS is activate or not";
CM_ SG_ 293 ABS_EBDFailed "Signal from ABS/ABS to indicate EBD failure for driver";
CM_ SG_ 293 ABSFailed "Signal from ABS/ABS to indicate Failure/Normal state of current running";
CM_ SG_ 293 ABS_LowBrakeFluid "Detect the brake fluid level";
CM_ SG_ 293 ABS_VehicleSpeedInvalid "Signal from ABS to indicate if VehicleSpeed is valid";
CM_ SG_ 293 ABS_VehicleSpeed "Vehicle Speed";
CM_ SG_ 293 ABS_Status_AliveCounter "signal couting the times of this message";
CM_ SG_ 293 ABS_HAZActive "Emergency Stop Active";
CM_ SG_ 293 ABS_Status_CheckSum "CRC code to check the data integrity";
CM_ SG_ 306 ESC_SlopeGradeAngle "Vehicle slope,Uphill is negative (head is higher than tail), downhill is positive (tail is higher than head)";
CM_ SG_ 306 ESC_MasterCylinderPressureV "Master cylinder pressure Validity";
CM_ SG_ 306 ESC_MasterCylinderPressure "Master cylinder pressure";
CM_ SG_ 306 ESC_HSA_Control_Status "Indicate HSA function is active or not
上坡辅助系统是否激活";
CM_ SG_ 306 ESC_HSA_Status_Fault "Detect the HAS Fault status";
CM_ SG_ 306 ESC_TcsDisableSts "Indicate the TCS function can use or not";
CM_ SG_ 306 ESC_EscCtrlActv "Indicate ESC  function is active or not";
CM_ SG_ 306 ESC_TcsCtrlActv "Indicate TCS  function is active or not";
CM_ SG_ 306 ESC_EscFlgFlt "Detect the ESC function fault status";
CM_ SG_ 306 ESC_TcsFlgFlt "Detect the TCS function fault status";
CM_ SG_ 306 ESC_EscDisableSts "Indicate the ESC function can use or not";
CM_ SG_ 306 ESC_HBAFlgFlt "Detect the HBA(Hydraulic Brake Assist) function status";
CM_ SG_ 306 ESC_HbaCtrlActv "Indicate HBA(Hydraulic Brake Assist)   function is active or not";
CM_ SG_ 306 BAS_FlgFlt "Detect the BAS(Brake Assist Systems) function fault status";
CM_ SG_ 306 BAS_CtrlActv "Indicate the BAS function can use or not";
CM_ SG_ 306 IBS_ESCOFF_StsFB "Feedback of the ESC OFF  is active or not";
CM_ SG_ 382 Checksum_0x17E "Checksum_0x17E";
CM_ SG_ 382 Rolling_counter_0x17E "Rolling_counter_0x17E";
CM_ SG_ 382 SAS_SASStsSnsr "the flag of  SAS status Punch:Steering angle status";
CM_ SG_ 382 SAS_SteeringAngleValid "Effective signal for steering angle";
CM_ SG_ 382 SAS_SteerWhlRotSpd "The current rotation speed of the steering wheel.";
CM_ SG_ 382 SAS_SASFailure "Angle sensor disabled.";
CM_ SG_ 382 SAS_Calibrated "SAS calibration state of Steer Angle Sensor";
CM_ SG_ 382 SAS_SteerWhlRotSpdStatus "The status of SteerWheel Rotation Speed valid";
CM_ SG_ 382 SAS_SteerWheelAngle "The current angle of the steering wheel(Positive, to left; Negative, to right)";
CM_ SG_ 383 CheckSum_0x17F "CheckSum_0x17F
校验和";
CM_ SG_ 383 RollingCounter_0x17F "RollingCounter_0x17F
循环计数";
CM_ SG_ 383 EPS_APA_CtrlAbortFeedback "EPS主动终止泊车的原因";
CM_ SG_ 383 EPS_LKARespTorq "EPS LKA Response Torque
EPS LKA的响应扭矩";
CM_ SG_ 383 EPS_SterMod "Steering Mode
转向模式";
CM_ SG_ 383 EPS_SterModV "Steering Mode Validity
转向模式有效性";
CM_ SG_ 383 EPS_ADAS_CtrlAbortFeedback "EPS主动终止ADAS的原因";
CM_ SG_ 383 EPS_SterFltMod "EPS Fault
EPS 故障";
CM_ SG_ 383 EPS_DrStrTorqV "Driver Steering Torque Validity
驾驶员转向扭矩有效性";
CM_ SG_ 383 EPS_APA_ModAvail "EPS APA Mode Available
EPS APA模式可用";
CM_ SG_ 383 EPS_APA_ModActv "EPS APA Mode Active
EPS APA功能激活";
CM_ SG_ 383 EPS_ADAS_ModActv "EPS ADAS Mode Active
EPS ADAS功能激活";
CM_ SG_ 383 EPS_ADAS_ModAvail "EPS ADAS Mode Available
EPS ADAS模式可用";
CM_ SG_ 383 EPS_DrStrTorqVal "Driver Steering Torque Value
驾驶员转向扭矩值";
CM_ SG_ 465 ADAS_ACC_SpdUnit "ACC巡航车速单位";
CM_ SG_ 465 ADAS_ACC_TargetSpeed "ACC目标车速";
CM_ SG_ 465 ADAS_ACC_OperatingSts "ACC运行状态";
CM_ SG_ 465 ADAS_ACC_TimeGapLevel "ACC跟车时距等级";
CM_ SG_ 465 ADAS_ACC_DistanceLevel "ACC跟车距离等级";
CM_ SG_ 465 ACC_ObjDispSts "显示目标状态";
CM_ SG_ 465 ACC_TakeOverReq "接管请求";
CM_ SG_ 466 ADAS_LSS_AssidFormResp "辅助模式选择";
CM_ SG_ 466 ADAS_LSS_AngCmdReqPortnValue "LSS角度请求保护值";
CM_ SG_ 466 ADAS_EPS_TargetSteeringAngle "ADAS目标转向角度";
CM_ SG_ 466 ADAS_EPS_Vibration_Req "方向盘振动请求";
CM_ SG_ 466 ADAS_LSS_VoiceWarn "LSS声音报警";
CM_ SG_ 466 ADAS_LSS_HandsoffWarn "LSS脱手报警";
CM_ SG_ 466 ADAS_LSS_FuncResp "LSS功能开关反馈";
CM_ SG_ 466 ADAS_EPS_AngReqSts "ADAS请求控制EPS状态";
CM_ SG_ 466 ADAS_LSS_LeLineTrackingSts "左侧车道线显示状态";
CM_ SG_ 466 ADAS_LSS_RiLineTrackingSts "右侧车道线显示状态";
CM_ SG_ 467 ADAS_AccelerationReq "ADAS加速请求值";
CM_ SG_ 467 ADAS_AEB_TgtDecel_ReqValue "AEB/EBA的目标减速度值";
CM_ SG_ 467 ADAS_MaxSoftAcceleration "ADAS舒适加速度上限";
CM_ SG_ 467 ADAS_MinSoftAcceleration "ADAS舒适加速度下限";
CM_ SG_ 468 ADAS_IBS_StopReq "ADAS请求刹车至停止";
CM_ SG_ 468 ADAS_IBS_CarStarting "ADAS请求汽车起步";
CM_ SG_ 468 ADAS_ACC_BrakePreferred "ADAS请求制动优先请求";
CM_ SG_ 468 ADAS_AEB_AbpReq "ADAS请求AEB预填充";
CM_ SG_ 468 ADAS_IBS_EBAReq "ADAS请求EBA功能";
CM_ SG_ 468 ADAS_IBS_MinBreakReq "ADAS最小制动请求";
CM_ SG_ 468 ADAS_VLCShutDownReq "退出模式，决定降扭速率";
CM_ SG_ 468 ADAS_VLCModeReq "请求VLC的工作模式";
CM_ SG_ 468 AEB_AWB_Level "制动的不同等级要求";
CM_ SG_ 468 AEB_ABA_Req "ADAS请求ABA";
CM_ SG_ 468 AEB_VehHldReq "AEB请求WCBS hold车";
CM_ SG_ 468 AEB_TgtDecel_Req "AEB减速请求";
CM_ SG_ 468 AEB_AWB_Req "向WCBS请求短促制动警告";
CM_ SG_ 468 ADAS_AEB_AbaLevel "自适应制动辅助灵敏度级别";
CM_ SG_ 468 ACC_AdtUpperJerkLimit "加速度变化率上限";
CM_ SG_ 468 ACC_AdtLowerJerkLimit "加速度变化率下限";
CM_ SG_ 470 ADAS_TSR_SWSts "TSR开关状态";
CM_ SG_ 470 TSR_SLWSwtResp "TSR报警功能开关反馈";
CM_ SG_ 470 ADAS_TSR_OperationSts "TSR运行状态";
CM_ SG_ 470 ADAS_TSR_SpeedLimit "TSR最高限速";
CM_ SG_ 470 ADAS_LSS_Available "LSS可激活";
CM_ SG_ 470 ADAS_LSS_FunSts "LSS功能状态";
CM_ SG_ 470 ADAS_LSS_ErrSts "ADAS LSS故障状态";
CM_ SG_ 470 ADAS_LSS_WarnFromResp "LSS预警方式选择";
CM_ SG_ 470 FC_CalibrationSts "前视相机标定状态";
CM_ SG_ 470 FC_BlockageSts "前视相机遮挡状态";
CM_ SG_ 471 ADAS_APA_OperationSts "APA运行状态";
CM_ SG_ 471 ADAS_APA_ModeSelect "APA运行模式选择";
CM_ SG_ 471 ADAS_APA_SystemSts "APA系统状态";
CM_ SG_ 471 ADAS_APA_OverspeedAlarm "APA超速提醒";
CM_ SG_ 471 ADAS_APA_StartParkingReq "APA开始泊车请求";
CM_ SG_ 471 ADAS_APA_RenewParkingReq "APA恢复泊车请求";
CM_ SG_ 471 ADAS_APA_PauseWarning "APA暂停提醒";
CM_ SG_ 471 ADAS_APA_AbortWarning "APA中止提醒";
CM_ SG_ 471 ADAS_APA_ParkingType "APA泊车类型";
CM_ SG_ 471 ADAS_APA_ParkingDirection "APA泊车方向";
CM_ SG_ 471 ADAS_APA_SuggestedID "APA推荐车位ID";
CM_ SG_ 472 ADAS_FrontCamera_Fault "AVM前相机故障";
CM_ SG_ 472 ADAS_RearCamera_Fault "AVM后相机故障";
CM_ SG_ 472 ADAS_LeftCamera_Fault "AVM左相机故障";
CM_ SG_ 472 ADAS_RightCamera_Fault "AVM右相机故障";
CM_ SG_ 472 ADAS_ECU_Fault "ADAS ECU状态";
CM_ SG_ 472 ACC_TxtInfoForDriver "ACC给驾驶员的文字提醒";
CM_ SG_ 472 ACC_DriveoffReq "前车驶离提醒";
CM_ SG_ 475 TSR_TrafSign "TSR交通标识信息";
CM_ SG_ 475 TSR_SpdAssistInfoDisp "TSR隐藏速度限制及附加标识";
CM_ SG_ 475 TSR_WarningOffset "TSR报警偏差值";
CM_ SG_ 475 TSR_SLWVisualWarn "TSR报警功能视觉报警";
CM_ SG_ 475 TSR_SLWVoiceWarn "TSR报警功能听觉报警";
CM_ SG_ 477 ADAS_APA_Soundremind "APA期间声音提醒";
CM_ SG_ 477 ADAS_APA_ParkingModeReq "APA功能模式选择";
CM_ SG_ 477 ADAS_APA_OtherWarning "APA期间用户操作反馈提醒";
CM_ SG_ 477 ADAS_APA_RemindTxt1 "APA无法开启原因";
CM_ SG_ 477 ADAS_APA_RemindTxt2 "APA正常工作提醒";
CM_ SG_ 477 ADAS_APA_LightReq "APA灯光请求";
CM_ SG_ 477 ADAS_APA_SearchingWarning "APA搜车位期间信息提醒";
CM_ SG_ 981 APA_FrontSystemSts "前进雷达工作状态";
CM_ SG_ 981 APA_RearSystemSts "倒车雷达工作状态";
CM_ SG_ 981 APA_ChimeRequest "系统鸣叫请求";
CM_ SG_ 981 APA_FRegion1ObjectSts "前进雷达区域1障碍物状态";
CM_ SG_ 981 APA_FRegion2ObjectSts "前进雷达区域2障碍物状态";
CM_ SG_ 981 APA_FRegion3ObjectSts "前进雷达区域3障碍物状态";
CM_ SG_ 981 APA_FRegion4ObjectSts "前进雷达区域4障碍物状态";
CM_ SG_ 981 APA_FrontExtenedDistance "前进雷达最近障碍物距离";
CM_ SG_ 981 APA_ParkAssistRRegion1ObjectSts "倒车雷达区域1障碍物状态";
CM_ SG_ 981 APA_ParkAssistRRegion2ObjectSts "倒车雷达区域2障碍物状态";
CM_ SG_ 981 APA_ParkAssistRRegion3ObjectSts "倒车雷达区域3障碍物状态";
CM_ SG_ 981 APA_ParkAssistRRegion4ObjectSts "倒车雷达区域4障碍物状态";
CM_ SG_ 981 APA_ParkAssistRExtenedDistance "倒车雷达最近障碍物距离";
CM_ SG_ 982 ADAS_USS_FaultFLI "前左中探头工作状态";
CM_ SG_ 982 ADAS_USS_FaultFRI "前右中探头工作状态";
CM_ SG_ 982 ADAS_USS_FaultFLO "前左角探头工作状态";
CM_ SG_ 982 ADAS_USS_FaultFRO "前右角探头工作状态";
CM_ SG_ 982 ADAS_USS_FaultFLS "前左侧探头工作状态";
CM_ SG_ 982 ADAS_USS_FaultFRS "前右侧探头工作状态";
CM_ SG_ 982 FLS_ExtenedDistance "前左侧探头最近障碍物距离";
CM_ SG_ 982 FRS_ExtenedDistance "前右侧探头最近障碍物距离";
CM_ SG_ 982 FLC_ExtenedDistance "前左角探头最近障碍物距离";
CM_ SG_ 982 FLM_ExtenedDistance "前左中探头最近障碍物距离";
CM_ SG_ 982 FRM_ExtenedDistance "前右中探头最近障碍物距离";
CM_ SG_ 982 FRC_ExtenedDistance "前右角探头最近障碍物距离";
CM_ SG_ 983 ADAS_USS_FaultRLI "后左中探头工作状态";
CM_ SG_ 983 ADAS_USS_FaultRLO "后左角探头工作状态";
CM_ SG_ 983 ADAS_USS_FaultRRI "后右中探头工作状态";
CM_ SG_ 983 ADAS_USS_FaultRRO "后右角探头工作状态";
CM_ SG_ 983 ADAS_USS_FaultRLS "后左侧探头工作状态";
CM_ SG_ 983 ADAS_USS_FaultRRS "后右侧探头工作状态";
CM_ SG_ 983 RLS_ExtenedDistance "后左侧探头最近障碍物距离";
CM_ SG_ 983 RRS_ExtenedDistance "后右侧探头最近障碍物距离";
CM_ SG_ 983 RLC_ExtenedDistance "后左角探头最近障碍物距离";
CM_ SG_ 983 RLM_ExtenedDistance "后左中探头最近障碍物距离";
CM_ SG_ 983 RRM_ExtenedDistance "后右中探头最近障碍物距离";
CM_ SG_ 983 RRC_ExtenedDistance "后右角探头最近障碍物距离";
CM_ SG_ 504 APA_EPS_AngReqSts "APA请求控制EPS状态";
CM_ SG_ 504 APA_EPS_TargetSteeringAngle "APA目标转向角度";
CM_ SG_ 504 ADAS_APA_BrakeModeSts "请求制动工作模式";
CM_ SG_ 504 APA_WCB_BrakeFunctionMode "APA请求控制WCBS功能模式";
CM_ SG_ 504 APA_WCB_TargetStopDistance "APA期望停车距离";
CM_ SG_ 504 APA_WCB_ExpectedGearPosition "APA期望挡位";
CM_ SG_ 504 APA_WCB_SpeedLimitation "APA期望速度";
CM_ SG_ 929 APA_slot_1 "库位ID";
CM_ SG_ 929 APA_slot_ID_1_P0_X "APA库位1的P0点X坐标";
CM_ SG_ 929 APA_slot_ID_1_P0_Y "APA库位1的P0点Y坐标";
CM_ SG_ 929 APA_slot_ID_1_P1_X "APA库位1的P1点X坐标";
CM_ SG_ 929 APA_slot_ID_1_P1_Y "APA库位1的P1点Y坐标";
CM_ SG_ 945 APA_slot_ID_1_Type "库位1类型";
CM_ SG_ 945 APA_slot_ID_1_P2_X "APA库位1的P2点X坐标";
CM_ SG_ 945 APA_slot_ID_1_P2_Y "APA库位1的P2点Y坐标";
CM_ SG_ 945 APA_slot_ID_1_P3_X "APA库位1的P3点X坐标";
CM_ SG_ 945 APA_slot_ID_1_P3_Y "APA库位1的P3点Y坐标";
CM_ SG_ 930 APA_slot_2 "库位ID";
CM_ SG_ 930 APA_slot_ID_2_P0_X "APA库位2的P0点X坐标";
CM_ SG_ 930 APA_slot_ID_2_P0_Y "APA库位2的P0点Y坐标";
CM_ SG_ 930 APA_slot_ID_2_P1_X "APA库位2的P1点X坐标";
CM_ SG_ 930 APA_slot_ID_2_P1_Y "APA库位2的P1点Y坐标";
CM_ SG_ 946 APA_slot_ID_2_Type "库位2类型";
CM_ SG_ 946 APA_slot_ID_2_P2_X "APA库位2的P2点X坐标";
CM_ SG_ 946 APA_slot_ID_2_P2_Y "APA库位2的P2点Y坐标";
CM_ SG_ 946 APA_slot_ID_2_P3_X "APA库位2的P3点X坐标";
CM_ SG_ 946 APA_slot_ID_2_P3_Y "APA库位2的P3点Y坐标";
CM_ SG_ 931 APA_slot_3 "库位ID";
CM_ SG_ 931 APA_slot_ID_3_P0_X "APA库位3的P0点X坐标";
CM_ SG_ 931 APA_slot_ID_3_P0_Y "APA库位3的P0点Y坐标";
CM_ SG_ 931 APA_slot_ID_3_P1_X "APA库位3的P1点X坐标";
CM_ SG_ 931 APA_slot_ID_3_P1_Y "APA库位3的P1点Y坐标";
CM_ SG_ 947 APA_slot_ID_3_Type "库位3类型";
CM_ SG_ 947 APA_slot_ID_3_P2_X "APA库位3的P2点X坐标";
CM_ SG_ 947 APA_slot_ID_3_P2_Y "APA库位3的P2点Y坐标";
CM_ SG_ 947 APA_slot_ID_3_P3_X "APA库位3的P3点X坐标";
CM_ SG_ 947 APA_slot_ID_3_P3_Y "APA库位3的P3点Y坐标";
CM_ SG_ 932 APA_slot_4 "库位ID";
CM_ SG_ 932 APA_slot_ID_4_P0_X "APA库位4的P0点X坐标";
CM_ SG_ 932 APA_slot_ID_4_P0_Y "APA库位4的P0点Y坐标";
CM_ SG_ 932 APA_slot_ID_4_P1_X "APA库位4的P1点X坐标";
CM_ SG_ 932 APA_slot_ID_4_P1_Y "APA库位4的P1点Y坐标";
CM_ SG_ 948 APA_slot_ID_4_Type "库位4类型";
CM_ SG_ 948 APA_slot_ID_4_P2_X "APA库位4的P2点X坐标";
CM_ SG_ 948 APA_slot_ID_4_P2_Y "APA库位4的P2点Y坐标";
CM_ SG_ 948 APA_slot_ID_4_P3_X "APA库位4的P3点X坐标";
CM_ SG_ 948 APA_slot_ID_4_P3_Y "APA库位4的P3点Y坐标";
CM_ SG_ 933 APA_slot_5 "库位ID";
CM_ SG_ 933 APA_slot_ID_5_P0_X "APA库位5的P0点X坐标";
CM_ SG_ 933 APA_slot_ID_5_P0_Y "APA库位5的P0点Y坐标";
CM_ SG_ 933 APA_slot_ID_5_P1_X "APA库位5的P1点X坐标";
CM_ SG_ 933 APA_slot_ID_5_P1_Y "APA库位5的P1点Y坐标";
CM_ SG_ 949 APA_slot_ID_5_Type "库位5类型";
CM_ SG_ 949 APA_slot_ID_5_P2_X "APA库位5的P2点X坐标";
CM_ SG_ 949 APA_slot_ID_5_P2_Y "APA库位5的P2点Y坐标";
CM_ SG_ 949 APA_slot_ID_5_P3_X "APA库位5的P3点X坐标";
CM_ SG_ 949 APA_slot_ID_5_P3_Y "APA库位5的P3点Y坐标";
CM_ SG_ 934 APA_slot_6 "库位ID";
CM_ SG_ 934 APA_slot_ID_6_P0_X "APA库位6的P0点X坐标";
CM_ SG_ 934 APA_slot_ID_6_P0_Y "APA库位6的P0点Y坐标";
CM_ SG_ 934 APA_slot_ID_6_P1_X "APA库位6的P1点X坐标";
CM_ SG_ 934 APA_slot_ID_6_P1_Y "APA库位6的P1点Y坐标";
CM_ SG_ 950 APA_slot_ID_6_Type "库位6类型";
CM_ SG_ 950 APA_slot_ID_6_P2_X "APA库位6的P2点X坐标";
CM_ SG_ 950 APA_slot_ID_6_P2_Y "APA库位6的P2点Y坐标";
CM_ SG_ 950 APA_slot_ID_6_P3_X "APA库位6的P3点X坐标";
CM_ SG_ 950 APA_slot_ID_6_P3_Y "APA库位6的P3点Y坐标";
CM_ SG_ 935 APA_slot_7 "库位ID";
CM_ SG_ 935 APA_slot_ID_7_P0_X "APA库位7的P0点X坐标";
CM_ SG_ 935 APA_slot_ID_7_P0_Y "APA库位7的P0点Y坐标";
CM_ SG_ 935 APA_slot_ID_7_P1_X "APA库位7的P1点X坐标";
CM_ SG_ 935 APA_slot_ID_7_P1_Y "APA库位7的P1点Y坐标";
CM_ SG_ 951 APA_slot_ID_7_Type "库位7类型";
CM_ SG_ 951 APA_slot_ID_7_P2_X "APA库位7的P2点X坐标";
CM_ SG_ 951 APA_slot_ID_7_P2_Y "APA库位7的P2点Y坐标";
CM_ SG_ 951 APA_slot_ID_7_P3_X "APA库位7的P3点X坐标";
CM_ SG_ 951 APA_slot_ID_7_P3_Y "APA库位7的P3点Y坐标";
CM_ SG_ 936 APA_slot_8 "库位ID";
CM_ SG_ 936 APA_slot_ID_8_P0_X "APA库位8的P0点X坐标";
CM_ SG_ 936 APA_slot_ID_8_P0_Y "APA库位8的P0点Y坐标";
CM_ SG_ 936 APA_slot_ID_8_P1_X "APA库位8的P1点X坐标";
CM_ SG_ 936 APA_slot_ID_8_P1_Y "APA库位8的P1点Y坐标";
CM_ SG_ 952 APA_slot_ID_8_Type "库位8类型";
CM_ SG_ 952 APA_slot_ID_8_P2_X "APA库位8的P2点X坐标";
CM_ SG_ 952 APA_slot_ID_8_P2_Y "APA库位8的P2点Y坐标";
CM_ SG_ 952 APA_slot_ID_8_P3_X "APA库位8的P3点X坐标";
CM_ SG_ 952 APA_slot_ID_8_P3_Y "APA库位8的P3点Y坐标";
CM_ SG_ 937 APA_slot_9 "库位ID";
CM_ SG_ 937 APA_slot_ID_9_P0_X "APA库位9的P0点X坐标";
CM_ SG_ 937 APA_slot_ID_9_P0_Y "APA库位9的P0点Y坐标";
CM_ SG_ 937 APA_slot_ID_9_P1_X "APA库位9的P1点X坐标";
CM_ SG_ 937 APA_slot_ID_9_P1_Y "APA库位9的P1点Y坐标";
CM_ SG_ 953 APA_slot_ID_9_Type "库位9类型";
CM_ SG_ 953 APA_slot_ID_9_P2_X "APA库位9的P2点X坐标";
CM_ SG_ 953 APA_slot_ID_9_P2_Y "APA库位9的P2点Y坐标";
CM_ SG_ 953 APA_slot_ID_9_P3_X "APA库位9的P3点X坐标";
CM_ SG_ 953 APA_slot_ID_9_P3_Y "APA库位9的P3点Y坐标";
CM_ SG_ 938 APA_slot_10 "库位ID";
CM_ SG_ 938 APA_slot_ID_10_P0_X "APA库位10的P0点X坐标";
CM_ SG_ 938 APA_slot_ID_10_P0_Y "APA库位10的P0点Y坐标";
CM_ SG_ 938 APA_slot_ID_10_P1_X "APA库位10的P1点X坐标";
CM_ SG_ 938 APA_slot_ID_10_P1_Y "APA库位10的P1点Y坐标";
CM_ SG_ 954 APA_slot_ID_10_Type "库位10类型";
CM_ SG_ 954 APA_slot_ID_10_P2_X "APA库位10的P2点X坐标";
CM_ SG_ 954 APA_slot_ID_10_P2_Y "APA库位10的P2点Y坐标";
CM_ SG_ 954 APA_slot_ID_10_P3_X "APA库位10的P3点X坐标";
CM_ SG_ 954 APA_slot_ID_10_P3_Y "APA库位10的P3点Y坐标";
CM_ SG_ 939 APA_slot_11 "库位ID";
CM_ SG_ 939 APA_slot_ID_11_P0_X "APA库位11的P0点X坐标";
CM_ SG_ 939 APA_slot_ID_11_P0_Y "APA库位11的P0点Y坐标";
CM_ SG_ 939 APA_slot_ID_11_P1_X "APA库位11的P1点X坐标";
CM_ SG_ 939 APA_slot_ID_11_P1_Y "APA库位11的P1点Y坐标";
CM_ SG_ 955 APA_slot_ID_11_Type "库位11类型";
CM_ SG_ 955 APA_slot_ID_11_P2_X "APA库位11的P2点X坐标";
CM_ SG_ 955 APA_slot_ID_11_P2_Y "APA库位11的P2点Y坐标";
CM_ SG_ 955 APA_slot_ID_11_P3_X "APA库位11的P3点X坐标";
CM_ SG_ 955 APA_slot_ID_11_P3_Y "APA库位11的P3点Y坐标";
CM_ SG_ 940 APA_slot_12 "库位ID";
CM_ SG_ 940 APA_slot_ID_12_P0_X "APA库位12的P0点X坐标";
CM_ SG_ 940 APA_slot_ID_12_P0_Y "APA库位12的P0点Y坐标";
CM_ SG_ 940 APA_slot_ID_12_P1_X "APA库位12的P1点X坐标";
CM_ SG_ 940 APA_slot_ID_12_P1_Y "APA库位12的P1点Y坐标";
CM_ SG_ 956 APA_slot_ID_12_Type "库位12类型";
CM_ SG_ 956 APA_slot_ID_12_P2_X "APA库位12的P2点X坐标";
CM_ SG_ 956 APA_slot_ID_12_P2_Y "APA库位12的P2点Y坐标";
CM_ SG_ 956 APA_slot_ID_12_P3_X "APA库位12的P3点X坐标";
CM_ SG_ 956 APA_slot_ID_12_P3_Y "APA库位12的P3点Y坐标";
CM_ SG_ 496 MHU_APA_Req "泊车按键";
CM_ SG_ 496 MHU_APA_ParkIn_Req "自动泊入按键";
CM_ SG_ 496 MHU_APA_ParkOut_Req "自动泊出按键";
CM_ SG_ 496 MHU_APA_ParkingStart_Req "开始泊车按键";
CM_ SG_ 496 MHU_APA_ParkingReCover_Req "恢复泊车按键";
CM_ SG_ 496 MHU_APA_ParkOut_Direction "泊出方向按键";
CM_ SG_ 496 MHU_APA_ParkOut_Mode "泊出类型按键";
CM_ SG_ 496 MHU_LSS_Req "LSS功能按键";
CM_ SG_ 496 MHU_LSS_Mode "LSS辅助形式按键";
CM_ SG_ 496 MHU_LSS_WarningMethod "LSS预警方式按键";
CM_ SG_ 496 MHU_TSR_Req "TSR功能按键";
CM_ SG_ 496 TSR_SpdWarningOffs_S "TSR超速报警偏差值设置";
CM_ SG_ 496 TSR_SLWFuncSwtReq "TSR超速报警开关请求";
CM_ SG_ 496 AEB_FuncSwtReq "AEB功能开关请求";
CM_ SG_ 496 AEB_FCW_SnvtyReq "FCW灵敏度请求";
CM_ SG_ 496 BSD_LCA_FuncSWReq "LCA功能开关请求";
CM_ SG_ 496 RCTA_FuncSWReq "RCTA功能请求";
CM_ SG_ 496 DOW_FuncSWReq "DOW功能开关请求";
CM_ SG_ 496 RCW_FuncSWReq "RCW功能开关请求";
CM_ SG_ 496 MHU_APA_ParkingSpace_ID "用户点击库位ID";
CM_ SG_ 497 Nav_RoadType "导航道路类型";
CM_ SG_ 497 Nav_errorSts "导航故障状态";
CM_ SG_ 497 Nav_VehToTrafEyeDist "导航车辆距离电子标志的距离";
CM_ SG_ 497 Nav_SpdLimValue "导航速度限制";
CM_ SG_ 497 Nav_SpdLimType "导航速度限制类型";
CM_ SG_ 497 Nav_SpdLimUnit "导航速度限制单位";
CM_ SG_ 497 Nav_TSRTrafSign "导航交通标志信息";
CM_ SG_ 497 Nav_CtryType "导航国家分类";
CM_ SG_ 498 Nav_TimeMod "导航时间模式";
CM_ SG_ 498 Nav_TimeIndcn "导航指示时段";
CM_ SG_ 514 BCM_FLWin_Postion "FL window postion
左前窗位置";
CM_ SG_ 514 BCM_FRWin_Postion "FR window postion
右前窗位置";
CM_ SG_ 514 BCM_RLWinIN_Postion "RL window postion
左后窗位置";
CM_ SG_ 514 BCM_RRWin_Postion "RR window postion
右后窗位置";
CM_ SG_ 514 BCM_WinLockSts "Window locked Status
车窗锁止状态";
CM_ SG_ 514 BCM_RLWinAntipinchSts "RL Window anti-pinch status
左后车窗防夹状态";
CM_ SG_ 514 BCM_RRWinAntipinchSts "RR Window anti-pinch status
右后车窗防夹状态";
CM_ SG_ 514 BCM_FLWinAntipinchSts "FL Window anti-pinch status
左前车窗防夹状态";
CM_ SG_ 514 BCM_FRWinAntipinchSts "FR Window anti-pinch status
右前车窗防夹状态";
CM_ SG_ 514 BCM_FrontWipeSWSts "Front Wipe Switch Status
前雨刮开关状态";
CM_ SG_ 514 BCM_AutoWipeSts "Auto Wipe Status
自动雨刮开关状态";
CM_ SG_ 514 BCM_FrontWipeSts "Front Wipe Status
前雨刮状态";
CM_ SG_ 514 BCM_FrontWipeReturn "Front Wipe Return
前雨刮归位信号";
CM_ SG_ 514 BCM_FrontWinWashSWSts "Front Window Wash Switch Status
前挡风玻璃清洗开关状态";
CM_ SG_ 514 BCM_RearWipeSWSts "Rear Wipe Switch Status
后雨刮开关状态";
CM_ SG_ 514 BCM_RearWipeSts "Rear Wipe Status
后雨刮状态";
CM_ SG_ 514 BCM_RearWipeReturn "Rear Wipe Return
后雨刮归位信号";
CM_ SG_ 514 BCM_RearWinWashSWSts "Rear Window Wash Switch Status
后挡风玻璃清洗开关状态";
CM_ SG_ 560 Checksum_230 "check sum";
CM_ SG_ 560 RollingCounter_230 "Rolling counter";
CM_ SG_ 560 EPB_SysBrkLtsReq "Brake System Brake Lights Requested
制动系统制动灯点亮要求";
CM_ SG_ 560 EPB_SysDspMsgReqV "Electric Park Brake System Display Message Request Validity
EPB显示信息要求有效性";
CM_ SG_ 560 EPB_SysStatIndReqV "Electric Park Brake System Status Indication Request Validity
EPB系统状态指示灯需求有效性";
CM_ SG_ 560 EPB_SysWrnIndReqV "Electric Park Brake System Warning Indication Request Validity
EPB系统报警显示要求有效性";
CM_ SG_ 560 EPB_SysWrnIndReq "Electric Park Brake System Warning Indication Request
EPB系统报警显示要求";
CM_ SG_ 560 EPB_SysStatIndReq "Electric Park Brake System Status Indication Request
EPB系统状态指示灯需求";
CM_ SG_ 560 EPB_SysDspMsgReq "Electric Park Brake System Display Message Request
EPB显示信息要求";
CM_ SG_ 560 EPB_AVHWrnIndReq "Automatic Vehicle Hold Warning Indication Request
AVH报警显示要求";
CM_ SG_ 560 EPB_AVHWrnIndReqV "Automatic Vehicle Hold Warning Indication RequestValidity
AVH报警显示要求有效性";
CM_ SG_ 560 EPB_AVHStatIndReq "Automatic Vehicle Hold Status Indication Request
AVH状态指示灯显示要求";
CM_ SG_ 560 EPB_AVHStatIndReqV "Automatic Vehicle Hold Status Indication RequestValidity
自动车辆保持状态指示灯显示要求有效性";
CM_ SG_ 560 EPB_AVHFeedbackSts "AVH状态";
CM_ SG_ 560 EPB_Sts "Electric Park Brake Status
EPB系统工作状态";
CM_ SG_ 560 WCBS_Trailermode_Feedback "拖车模式反馈";
CM_ SG_ 617 WCBS_ACC_VLC_Active "ACC 车辆纵向控制功能激活";
CM_ SG_ 617 WCBS_ACC_CDD_Active "ACC 车辆CDD功能激活";
CM_ SG_ 617 WCBS_ACC_VLC_Avl "ACC 车辆纵向控制功能可用";
CM_ SG_ 617 WCBS_ACC_CDD_Avl "ACC 车辆CDD功能可用";
CM_ SG_ 617 WCBS_ACC_VLC_AccInTar "WCBS 内部车辆目标纵向加速度";
CM_ SG_ 617 WCBS_ABAAtv "Automatic Braking Auxiliary Active
ABA激活";
CM_ SG_ 617 WCBS_ABAAva "Automatic Braking Auxiliary Available
ABA可用";
CM_ SG_ 617 WCBS_ABPAtv "Automatic Emergency Braking Prefill Active
AEB预填充激活";
CM_ SG_ 617 WCBS_ABPAva "Automatic Emergency Braking Prefill Available
AEB预填充可用";
CM_ SG_ 617 WCBS_AWBAtv "自动警告制动功能激活";
CM_ SG_ 617 WCBS_AWBAvl "自动警告制动功能可用";
CM_ SG_ 617 WCBS_AEBAtv "Automatic Emergency Braking Active
AEB激活";
CM_ SG_ 617 WCBS_AEBAva "Automatic Emergency Braking Vailable
AEB可用";
CM_ SG_ 617 WCBS_VStandstillSta "Vehicle Standstill State
整车静止状态";
CM_ SG_ 617 WCBS_BrkFrcSta "BrakeForce State
制动压力状态";
CM_ SG_ 617 WCBS_ESCDeteACCErroSta "车辆纵向控制失效状态";
CM_ SG_ 617 WCBS_APA_VLC_FailureStatus "WCBS反馈故障状态";
CM_ SG_ 617 WCBS_APA_VLC_Status "WBCS制动模式状态";
CM_ SG_ 617 WCBS_APA_VLC_Available "WCBS指示当前是否支持APA可用";
CM_ SG_ 617 WCBS_APA_VLC_Active "自动泊车纵向控制激活";
CM_ SG_ 617 WCBS_APA_EmgyBrkAvlb "APA 紧急制动功能可用";
CM_ SG_ 617 WCBS_APA_CDD_Active "自动泊车CDD激活";
CM_ SG_ 624 AB_BrkPedalSwSts "Brake pedal switch status
制动踏板开关状态";
CM_ SG_ 624 AB_BrkPedalSwStsV "Brake pedal switch status
制动踏板开关状态";
CM_ SG_ 624 AB_Fault_Status "制动系统故障状态";
CM_ SG_ 624 AB_IBS_Sys_Fault_Sts "IBS sysstem fault status
IBS系统故障状态";
CM_ SG_ 624 AB_BrkPedalPct "The percent of brake pedal
制动踏板百分比";
CM_ SG_ 624 AB_BrkPedalTravel "brake pedal travel
制动踏板行程";
CM_ SG_ 676 MHU_ESCOFF_SW_Sts "ESC Off Switch Status
ESC OFF开关状态";
CM_ SG_ 676 MHU_VCU_CreepDisable_stt "Request for VCU to disable creep function
请求VCU禁用爬行模式";
CM_ SG_ 676 MHU_AVH_Req "AVH 请求";
CM_ SG_ 676 MHU_RegencyLevRequest "Switch of Regen Level on MHU
能量回收等级请求";
CM_ SG_ 676 MHU_DM_SwitchModeSts "Switch of drive mode  on MHU
驾驶模式请求";
CM_ SG_ 676 MHU_Trailermode_Req "拖车模式请求";
CM_ SG_ 676 MHU_UPAMuteSwitch "前雷达静音开关";
CM_ SG_ 994 ESC_LateralACC_Valid "Valid flag of lateral acceleration";
CM_ SG_ 994 ESC_LongitudeACC_Valid "Valid flag of longitude acceleration";
CM_ SG_ 994 ESC_VehDynYawRate_Valid "Valid flag of yaw rate";
CM_ SG_ 994 ESC_VehDynYawRate "Indicate the yaw rate";
CM_ SG_ 994 ESC_LateralACC "Indicate lateral acceleration";
CM_ SG_ 994 ESC_LongitudeACC "Indicate longitude acceleration";
CM_ SG_ 1009 IPC_IPCTotalOdometer "the total odometer displayed in IPC
仪表显示总里程";
CM_ SG_ 1009 IPC_IPCTotalOdometerV "Odometer infomation validity
总里程信息有效性";
CM_ SG_ 1009 IPC_Remain_Maintenance "Remaining maintenance mileage
剩余保养里程";
CM_ SG_ 1009 RollingCounter_0x3F1 "RollingCounter_0x3F1
循环计数";
CM_ SG_ 1009 CheckSum_0x3F1 "CheckSum_0x3F1
校验和";
CM_ SG_ 1015 MFS_ACC_CruiseSpdIncrease "Up Control
方向上控制,巡航车速增加";
CM_ SG_ 1015 MFS_ACC_CruiseOn_Off "Central key Control
中键控制，ACC开关";
CM_ SG_ 1015 MFS_L2_Failure "Left Multi-Funtion Switch Failure
左边开关故障";
CM_ SG_ 1015 MFS_ACC_CruiseGapSet "Left Control
方向左控制，跟车时距设定（循环）";
CM_ SG_ 1015 MFS_ACC_CruiseSpdDecrease "Down Control
方向下控制,巡航车速降低";
CM_ SG_ 1015 MFS_ACC_CruiseCancel "Right Control
方向右控制，取消巡航";
CM_ SG_ 1067 TPMS_RFpressureSts "Tire Right Front Pressure Status
右前轮压力状态";
CM_ SG_ 1067 TPMS_LFpressureSts "Tire Left Front Pressure Status
左前轮压力状态";
CM_ SG_ 1067 TPMS_SysSts "Tire Pressure System Failure Status
TPMS故障状态";
CM_ SG_ 1067 TPMS_RRpressureSts "Tire Right Rear Pressure Status
右后轮压力状态";
CM_ SG_ 1067 TPMS_LRpressureSts "Tire Left Rear Pressure Status
左后轮压力状态";
CM_ SG_ 1067 TPMS_RRpressureV "Tire Right Rear Pressure Validity
右后轮压力有效性";
CM_ SG_ 1067 TPMS_LRpressureV "Tire Left Rear Pressure Validity
左后轮压力有效性";
CM_ SG_ 1067 TPMS_RFpressureV "Tire Right Front Pressure Validity
右前轮压力有效性";
CM_ SG_ 1067 TPMS_LFpressureV "Tire Left Front Pressure Validity
左前轮压力有效性";
CM_ SG_ 1067 TPMS_LFpressure "Tire Left Front Pressure
左前轮压力";
CM_ SG_ 1067 TPMS_RFpressure "Tire Right Front Pressure
右前轮压力";
CM_ SG_ 1067 TPMS_LRpressure "Tire Left Rear Pressure
左后轮压力";
CM_ SG_ 1067 TPMS_RRpressure "Tire Right Rear Pressure
右后轮压力";
CM_ SG_ 1236 BCM_CoverAjarStatus "Signal from BCM to indicate the ajar/close status of Cover
BCM信号提示前舱盖门开启／关闭";
CM_ SG_ 1236 BCM_TrunckAjarStatus "Signal from BCM to indicate the ajar/close status of Truncklid
BCM信号提示后盖箱／后车门开启／关闭";
CM_ SG_ 1236 BCM_DriverSideDoorAjarSts "Signal from BCM to indicate the ajar/close status of driver door
BCM信号提示驾驶员侧车门开启／关闭状态";
CM_ SG_ 1236 BCM_CodriversSideDoorAjarSts "Signal from BCM to indicate the ajar/close status of codrivers door
BCM信号提示副驾侧车门开启／关闭状态";
CM_ SG_ 1236 BCM_RearLeftDoorAjarStatus "Signal from BCM to indicate the ajar/close status of Rear Left Door
BCM信号提示左后车门开启／关闭状态";
CM_ SG_ 1236 BCM_RearRightDoorAjarStatus "Signal from BCM to indicate the ajar/close status of Rear Right Door
BCM信号提示右后车门开启／关闭状态";
CM_ SG_ 1236 BCM_DoorLockStatusRL "Rear Left Doo rLock Status（Reserve）
左后门锁状态（保留）";
CM_ SG_ 1236 BCM_DoorLockStatusRR "Rear Right Door Lock Status（Reserve）
右后门锁状态保留）";
CM_ SG_ 1236 BCM_DoorLockStatusCodrivres "Codrivers Door Lock Status（Reserve）
副驾驶员门锁状态保留）";
CM_ SG_ 1236 BCM_DoorLockStatusDrv "Driver Door Lock Status
主驾门锁状态";
CM_ SG_ 1236 BCM_ATWS_St "BCM Anti thelf warning status
防盗报警状态";
CM_ SG_ 1236 BCM_TailGateSts "Tail-gate Status
尾门状态（低配）";
CM_ SG_ 265 CheckSum_0x109 "CheckSum_0x109
校验和";
CM_ SG_ 265 RollingCounter_0x109 "RollingCounter_0x109
循环计数";
CM_ SG_ 265 BCM_STAT_Horn "Horn switch status
喇叭开关状态";
CM_ SG_ 265 BCM_STAT_HazardWarn "Hazard Warning switch activation
危险警告开关激活";
CM_ SG_ 265 BCM_LowBeamSWSts "Low Beam Switch Status
近光灯开关状态";
CM_ SG_ 265 BCM_TurnLightSWSts "Turn light Switch Status
转向灯开关状态";
CM_ SG_ 265 BCM_Tail_MicroSW "Tail door microswitch
尾门微动开关";
CM_ SG_ 265 STAT_Central_LockSts "Central_Lock_Status
中控锁状态";
CM_ SG_ 265 BCM_RFogLampSWSts "Rear Fog Lamp Switch Status
后雾灯开关状态";
CM_ SG_ 265 BCM_FFogLampSWSts "Front Fog Lamp Switch Status
前雾灯开关状态";
CM_ SG_ 265 BCM_HighBeamSWSts "High Beam Switch Status
远光灯开关状态";
CM_ SG_ 482 PEPS_PowerModeValidity "PEPS Power Distribution StatusValidity bit";
CM_ SG_ 482 PEPS_PowerMode "PEPS Power Distribution Status";
CM_ SG_ 482 PEPS_IGN1RelayValidity "IGN1 output validity";
CM_ SG_ 482 PEPS_IGN1RelaySts "IGN1 output status";
CM_ SG_ 482 PEPS_Learning_Status "PEPS System learning status";
CM_ SG_ 482 BCM_WPC_Off_Req "BCM request WPC Off";
CM_ SG_ 1056 RLS_Solar_Right_PassgSide "Transmits the value of solar sensor element 2 to the heating/air-conditioning automatic control";
CM_ SG_ 1056 RLS_Solar_Left_Driveside "Transmits the value of solar sensor element 1 to the heating/air-conditioning automatic control";
CM_ SG_ 1056 RLS_Rainfall_magnitude "RLS indicates the current amount of rainfall magnitude
RLS指示当前雨量大小";
CM_ SG_ 1056 RLS_LightSensorError "Light sensor error
光传感器故障";
CM_ SG_ 1056 RLS_RainSensorError "Rain Sensor Error
雨传感器故障";
CM_ SG_ 1056 RLS_LightRequest "Indicates whether the light is to be switched on due to the ambient conditions.";
CM_ SG_ 354 VCU_ModeGearSts "gear information";
CM_ SG_ 354 VCU_P_Sts "P档按键状态";
CM_ SG_ 354 VCU_Warning_IMMO_Fail "Indicates the IMMO Fail";
CM_ SG_ 354 VCU_Ready "Indicates Ready State";
CM_ SG_ 354 VCU_RegencyLevInd "Indicates Regency Level";
CM_ SG_ 359 VCU_StsAccPedalFault "Accelerate pedal fault status";
CM_ SG_ 359 VCU_StsSysFault "Drive system fault level";
CM_ SG_ 359 VCU_AccPedalPosition "Accelerate pedal position";
CM_ SG_ 359 VCU_AccPedal_Active "加速踏板信号有效性";
CM_ SG_ 811 CCU_PTCgear_Req_Reserve "PTC Gear Request
PTC档位请求（保留）";
CM_ SG_ 811 CCU_Anion_Generator_Sts "air anion-generator Status
负离子发生器状态";
CM_ SG_ 811 CCU_AC_Req "Compressor request switch signal
压缩机请求";
CM_ SG_ 811 CCU_Onoff_Sts "空调开机关机状态";
CM_ SG_ 811 CCU_AUTO_Status "AC AUTO_Status
自动空调状态";
CM_ SG_ 811 CCU_FrontDefrostSts "Front Defrost_Status
前除霜状态";
CM_ SG_ 811 CCU_AC_Sts "空调制冷状态";
CM_ SG_ 811 CCU_Circulation_Sts "CCU intake cycle state
空调循环模式";
CM_ SG_ 811 CCU_ExternalTemperatureFailSts "External Temperature Fail Sts
车外温度信号故障状态";
CM_ SG_ 811 CCU_PTC_Req "CCU request VCU to enable or disable PTC
CCU请求启用或禁用PTC";
CM_ SG_ 811 CCU_Temp_Sync_Sts "Temperature Synchronization Status
温区同步状态";
CM_ SG_ 811 CCU_evaporator_Temperature "evaporator Temperature
蒸发器温度";
CM_ SG_ 811 CCU_PTCPwr_Req "CCU Request PTC power
CCU请求PTC功率";
CM_ SG_ 811 CCU_CompSpdMEAS_Comp "Compressor speed signal
压缩机转速请求";
CM_ SG_ 811 CCU_ExternalTemperature "External Temperature
车外温度";
CM_ SG_ 670 Time_second "Time_second
秒";
CM_ SG_ 670 GPSSystAtv "Global Position System Active
GPS工作状态";
CM_ SG_ 670 Time_Minute "Time_Minute
分";
CM_ SG_ 670 Time_Hour "Time_Hour
小时";
CM_ SG_ 670 Time_Day "Time_Day
日";
CM_ SG_ 670 Time_Month "Time_Month
月";
CM_ SG_ 670 Time_Year "Time_Year
年";
CM_ SG_ 1760 VCU_ECUAddress "VCU源节点地址";
CM_ SG_ 1760 VCU_CBV "VCU控制向量";
CM_ SG_ 1760 VCU_NM_Ststus "VCU网络管理状态";
CM_ SG_ 1760 VCU_Awaken_Reason "VCU唤醒原因";
CM_ SG_ 1713 ADAS_ECUAddress "ADAS源节点地址";
CM_ SG_ 1713 ADAS_CBV "ADAS控制向量";
CM_ SG_ 1713 ADAS_NM_Ststus "ADAS网络管理状态";
CM_ SG_ 1713 ADAS_Awaken_Reason "ADAS唤醒原因";
CM_ SG_ 1718 CRL_ECUAddress "CRL源节点地址";
CM_ SG_ 1718 CRL_CBV "CRL控制向量";
CM_ SG_ 1718 CRL_NM_Status "CRL网络管理状态";
CM_ SG_ 1718 CRL_Awaken_Reason "CRL唤醒原因";
BA_DEF_ SG_  "GenSigILSupport" ENUM  "No","Yes";
BA_DEF_ SG_  "GenSigEVName" STRING ;
BA_DEF_ SG_  "SigType" ENUM  "Default","Range","RangeSigned","ASCII","Discrete","Control","ReferencePGN","DTC","StringDelimiter","StringLength","StringLengthControl","MessageCounter","MessageChecksum";
BA_DEF_ SG_  "GenSigSendOnInit" ENUM  "Not Initialized","Application","Handler";
BA_DEF_ BO_  "CANFD_BRS" ENUM  "0","1";
BA_DEF_ BO_  "GenMsgRequestable" INT 0 1;
BA_DEF_ BO_  "MsgType" ENUM  "CDD","COM","COM_LONG","COM_LONG_FC","CANNM","XCP_REQ","XCP_RESP","UDS_PHY_REQ","UDS_PHY_RESP","UDS_FUN_REQ","OSEKNM";
BA_DEF_ BO_  "Receivers" STRING ;
BA_DEF_ BO_  "Transmitters" STRING ;
BA_DEF_ BU_  "BitOrder" ENUM  "LSB","MSB";
BA_DEF_  "BusOffRecoveryTime" INT 0 65535;
BA_DEF_  "BusWakeUpDelay" INT 0 65535;
BA_DEF_  "NetworkType" STRING ;
BA_DEF_ BU_  "NodeLayerModules" STRING ;
BA_DEF_ BU_  "NmStationAddress" HEX 0 241;
BA_DEF_ BU_  "NmCAN" INT 1 2;
BA_DEF_ BU_  "ILUsed" ENUM  "No","Yes";
BA_DEF_  "NmType" STRING ;
BA_DEF_  "VersionYear" INT 2010 2999;
BA_DEF_  "ProtocolType" STRING ;
BA_DEF_  "NmMessageCount" INT 0 256;
BA_DEF_  "NmBaseAddress" HEX 1536 1791;
BA_DEF_  "DBName" STRING ;
BA_DEF_  "BusType" STRING ;
BA_DEF_  "Baudrate" INT 0 1000000;
BA_DEF_ SG_  "GenSigInvalidValue" HEX 0 0;
BA_DEF_ SG_  "GenSigStartValue" HEX 0 0;
BA_DEF_ SG_  "GenSigSendType" ENUM  "Cycle","OnWrite","OnWriteWithRepetition","OnChange","OnChangeWithRepetition","IfActive","IfActiveWithRepetition","NoSigSendType","vector_leerstring";
BA_DEF_ BO_  "GenMsgSendType" ENUM  "Cycle","NoMsgSendType","IfActive","Event","CA","CE";
BA_DEF_ BO_  "GenMsgILSupport" ENUM  "No","Yes";
BA_DEF_ BO_  "GenMsgCycleTime" INT 0 0;
BA_DEF_ BO_  "VFrameFormat" ENUM  "StandardCAN","ExtendedCAN","StandardCAN_FD","ExtendedCAN_FD","reserved","J1939PG","reserved","reserved","reserved","reserved","reserved","reserved","reserved","reserved","reserved","reserved","StandardCAN_FD","ExtendedCAN_FD";
BA_DEF_DEF_  "GenSigILSupport" "Yes";
BA_DEF_DEF_  "GenSigEVName" "Env@Nodename_@Signame";
BA_DEF_DEF_  "SigType" "Default";
BA_DEF_DEF_  "GenSigSendOnInit" "Not Initialized";
BA_DEF_DEF_  "CANFD_BRS" "1";
BA_DEF_DEF_  "GenMsgRequestable" 1;
BA_DEF_DEF_  "MsgType" "CDD";
BA_DEF_DEF_  "Receivers" "Default";
BA_DEF_DEF_  "Transmitters" "Default";
BA_DEF_DEF_  "BitOrder" "LSB";
BA_DEF_DEF_  "BusOffRecoveryTime" 160;
BA_DEF_DEF_  "BusWakeUpDelay" 70;
BA_DEF_DEF_  "NetworkType" "HSCAN";
BA_DEF_DEF_  "NodeLayerModules" "OSEKNM01.dll,CANoeILNLVector.dll";
BA_DEF_DEF_  "NmStationAddress" 0;
BA_DEF_DEF_  "NmCAN" 2;
BA_DEF_DEF_  "ILUsed" "Yes";
BA_DEF_DEF_  "NmType" "OSEK";
BA_DEF_DEF_  "VersionYear" 2019;
BA_DEF_DEF_  "ProtocolType" "CAN";
BA_DEF_DEF_  "NmMessageCount" 256;
BA_DEF_DEF_  "NmBaseAddress" 1536;
BA_DEF_DEF_  "DBName" "";
BA_DEF_DEF_  "BusType" "";
BA_DEF_DEF_  "Baudrate" 500000;
BA_DEF_DEF_  "GenSigInvalidValue" 0;
BA_DEF_DEF_  "GenSigStartValue" 0;
BA_DEF_DEF_  "GenSigSendType" "Cycle";
BA_DEF_DEF_  "GenMsgSendType" "Cycle";
BA_DEF_DEF_  "GenMsgILSupport" "Yes";
BA_DEF_DEF_  "GenMsgCycleTime" 100;
BA_DEF_DEF_  "VFrameFormat" "StandardCAN";
BA_ "BusType" "CAN";
BA_ "NmType" "AUTOSAR Nm";
BA_ "DBName" "ACAN";
BA_ "NmStationAddress" BU_ ADAS 177;
BA_ "NmStationAddress" BU_ CRL 182;
BA_ "NmStationAddress" BU_ VCU 224;
BA_ "GenMsgCycleTime" BO_ 128 20;
BA_ "MsgType" BO_ 128 1;
BA_ "GenMsgCycleTime" BO_ 290 20;
BA_ "MsgType" BO_ 290 1;
BA_ "GenMsgCycleTime" BO_ 291 20;
BA_ "MsgType" BO_ 291 1;
BA_ "GenMsgCycleTime" BO_ 292 20;
BA_ "MsgType" BO_ 292 1;
BA_ "MsgType" BO_ 262 1;
BA_ "GenMsgCycleTime" BO_ 293 20;
BA_ "MsgType" BO_ 293 1;
BA_ "GenMsgCycleTime" BO_ 306 20;
BA_ "MsgType" BO_ 306 1;
BA_ "GenMsgCycleTime" BO_ 382 10;
BA_ "MsgType" BO_ 382 1;
BA_ "GenMsgCycleTime" BO_ 383 10;
BA_ "MsgType" BO_ 383 1;
BA_ "GenMsgCycleTime" BO_ 465 20;
BA_ "MsgType" BO_ 465 1;
BA_ "GenMsgCycleTime" BO_ 466 20;
BA_ "MsgType" BO_ 466 1;
BA_ "GenMsgCycleTime" BO_ 467 20;
BA_ "MsgType" BO_ 467 1;
BA_ "GenMsgCycleTime" BO_ 468 20;
BA_ "MsgType" BO_ 468 1;
BA_ "GenMsgCycleTime" BO_ 470 50;
BA_ "MsgType" BO_ 470 1;
BA_ "GenMsgCycleTime" BO_ 471 50;
BA_ "MsgType" BO_ 471 1;
BA_ "MsgType" BO_ 472 1;
BA_ "GenMsgCycleTime" BO_ 475 50;
BA_ "MsgType" BO_ 475 1;
BA_ "MsgType" BO_ 477 1;
BA_ "GenMsgCycleTime" BO_ 981 50;
BA_ "MsgType" BO_ 981 1;
BA_ "GenMsgCycleTime" BO_ 982 50;
BA_ "MsgType" BO_ 982 1;
BA_ "GenMsgCycleTime" BO_ 983 50;
BA_ "MsgType" BO_ 983 1;
BA_ "GenMsgCycleTime" BO_ 504 20;
BA_ "MsgType" BO_ 504 1;
BA_ "MsgType" BO_ 929 1;
BA_ "MsgType" BO_ 945 1;
BA_ "MsgType" BO_ 930 1;
BA_ "MsgType" BO_ 946 1;
BA_ "MsgType" BO_ 931 1;
BA_ "MsgType" BO_ 947 1;
BA_ "MsgType" BO_ 932 1;
BA_ "MsgType" BO_ 948 1;
BA_ "MsgType" BO_ 933 1;
BA_ "MsgType" BO_ 949 1;
BA_ "MsgType" BO_ 934 1;
BA_ "MsgType" BO_ 950 1;
BA_ "MsgType" BO_ 935 1;
BA_ "MsgType" BO_ 951 1;
BA_ "MsgType" BO_ 936 1;
BA_ "MsgType" BO_ 952 1;
BA_ "MsgType" BO_ 937 1;
BA_ "MsgType" BO_ 953 1;
BA_ "MsgType" BO_ 938 1;
BA_ "MsgType" BO_ 954 1;
BA_ "MsgType" BO_ 939 1;
BA_ "MsgType" BO_ 955 1;
BA_ "MsgType" BO_ 940 1;
BA_ "MsgType" BO_ 956 1;
BA_ "GenMsgCycleTime" BO_ 496 0;
BA_ "GenMsgSendType" BO_ 496 3;
BA_ "MsgType" BO_ 496 1;
BA_ "GenMsgCycleTime" BO_ 497 200;
BA_ "MsgType" BO_ 497 1;
BA_ "GenMsgCycleTime" BO_ 498 200;
BA_ "MsgType" BO_ 498 1;
BA_ "MsgType" BO_ 514 1;
BA_ "GenMsgCycleTime" BO_ 560 50;
BA_ "MsgType" BO_ 560 1;
BA_ "GenMsgCycleTime" BO_ 617 20;
BA_ "MsgType" BO_ 617 1;
BA_ "GenMsgCycleTime" BO_ 624 20;
BA_ "MsgType" BO_ 624 1;
BA_ "GenMsgCycleTime" BO_ 676 0;
BA_ "GenMsgSendType" BO_ 676 3;
BA_ "MsgType" BO_ 676 1;
BA_ "GenMsgCycleTime" BO_ 994 20;
BA_ "MsgType" BO_ 994 1;
BA_ "GenMsgCycleTime" BO_ 1009 1000;
BA_ "MsgType" BO_ 1009 1;
BA_ "GenMsgCycleTime" BO_ 1015 200;
BA_ "MsgType" BO_ 1015 1;
BA_ "GenMsgCycleTime" BO_ 1067 500;
BA_ "MsgType" BO_ 1067 1;
BA_ "GenMsgCycleTime" BO_ 1236 150;
BA_ "MsgType" BO_ 1236 1;
BA_ "GenMsgCycleTime" BO_ 265 30;
BA_ "MsgType" BO_ 265 1;
BA_ "GenMsgCycleTime" BO_ 482 20;
BA_ "MsgType" BO_ 482 1;
BA_ "GenMsgCycleTime" BO_ 1056 200;
BA_ "MsgType" BO_ 1056 1;
BA_ "GenMsgCycleTime" BO_ 354 20;
BA_ "MsgType" BO_ 354 1;
BA_ "GenMsgCycleTime" BO_ 359 20;
BA_ "MsgType" BO_ 359 1;
BA_ "GenMsgCycleTime" BO_ 811 50;
BA_ "MsgType" BO_ 811 1;
BA_ "GenMsgCycleTime" BO_ 670 1000;
BA_ "MsgType" BO_ 670 1;
BA_ "GenMsgCycleTime" BO_ 1760 1000;
BA_ "MsgType" BO_ 1760 4;
BA_ "GenMsgCycleTime" BO_ 1713 1000;
BA_ "MsgType" BO_ 1713 4;
BA_ "GenMsgCycleTime" BO_ 1718 1000;
BA_ "GenMsgCycleTime" BO_ 1969 0;
BA_ "GenMsgSendType" BO_ 1969 3;
BA_ "MsgType" BO_ 1969 7;
BA_ "GenMsgCycleTime" BO_ 1977 0;
BA_ "GenMsgSendType" BO_ 1977 3;
BA_ "MsgType" BO_ 1977 8;
BA_ "GenMsgCycleTime" BO_ 2015 0;
BA_ "GenMsgSendType" BO_ 2015 3;
BA_ "MsgType" BO_ 2015 9;
BA_ "GenSigStartValue" SG_ 306 ESC_MasterCylinderPressure 1000;
BA_ "GenSigStartValue" SG_ 382 SAS_SteerWhlRotSpd 8192;
BA_ "GenSigStartValue" SG_ 383 EPS_LKARespTorq 1000;
BA_ "GenSigStartValue" SG_ 383 EPS_DrStrTorqVal 100;
BA_ "GenSigInvalidValue" SG_ 466 ADAS_LSS_AngCmdReqPortnValue 16383;
BA_ "GenSigStartValue" SG_ 466 ADAS_LSS_AngCmdReqPortnValue 7800;
BA_ "GenSigInvalidValue" SG_ 466 ADAS_EPS_TargetSteeringAngle 65535;
BA_ "GenSigStartValue" SG_ 466 ADAS_EPS_TargetSteeringAngle 32773;
BA_ "GenSigInvalidValue" SG_ 467 ADAS_AccelerationReq 4095;
BA_ "GenSigStartValue" SG_ 467 ADAS_AccelerationReq 1000;
BA_ "GenSigInvalidValue" SG_ 467 ADAS_AEB_TgtDecel_ReqValue 65535;
BA_ "GenSigStartValue" SG_ 467 ADAS_AEB_TgtDecel_ReqValue 32787;
BA_ "GenSigInvalidValue" SG_ 467 ADAS_MaxSoftAcceleration 4095;
BA_ "GenSigStartValue" SG_ 467 ADAS_MaxSoftAcceleration 1000;
BA_ "GenSigInvalidValue" SG_ 467 ADAS_MinSoftAcceleration 4095;
BA_ "GenSigStartValue" SG_ 467 ADAS_MinSoftAcceleration 1000;
BA_ "GenSigInvalidValue" SG_ 468 ACC_AdtUpperJerkLimit 255;
BA_ "GenSigInvalidValue" SG_ 468 ACC_AdtLowerJerkLimit 255;
BA_ "GenSigStartValue" SG_ 475 ADAS_AEB_FuncSWResp 1;
BA_ "GenSigStartValue" SG_ 475 AEB_FuncSts 1;
BA_ "GenSigStartValue" SG_ 475 AEB_FCW_SnvtyResp 1;
BA_ "GenSigInvalidValue" SG_ 981 APA_FrontExtenedDistance 255;
BA_ "GenSigInvalidValue" SG_ 981 APA_ParkAssistRExtenedDistance 255;
BA_ "GenSigInvalidValue" SG_ 982 FLS_ExtenedDistance 511;
BA_ "GenSigInvalidValue" SG_ 982 FRS_ExtenedDistance 511;
BA_ "GenSigInvalidValue" SG_ 982 FLC_ExtenedDistance 255;
BA_ "GenSigInvalidValue" SG_ 982 FLM_ExtenedDistance 255;
BA_ "GenSigInvalidValue" SG_ 982 FRM_ExtenedDistance 255;
BA_ "GenSigInvalidValue" SG_ 982 FRC_ExtenedDistance 255;
BA_ "GenSigInvalidValue" SG_ 983 RLS_ExtenedDistance 511;
BA_ "GenSigInvalidValue" SG_ 983 RRS_ExtenedDistance 511;
BA_ "GenSigInvalidValue" SG_ 983 RLC_ExtenedDistance 255;
BA_ "GenSigInvalidValue" SG_ 983 RLM_ExtenedDistance 255;
BA_ "GenSigInvalidValue" SG_ 983 RRM_ExtenedDistance 255;
BA_ "GenSigInvalidValue" SG_ 983 RRC_ExtenedDistance 255;
BA_ "GenSigInvalidValue" SG_ 504 APA_EPS_TargetSteeringAngle 65535;
BA_ "GenSigStartValue" SG_ 504 APA_EPS_TargetSteeringAngle 32773;
BA_ "GenSigSendType" SG_ 496 MHU_APA_Req 7;
BA_ "GenSigSendType" SG_ 496 MHU_APA_ParkIn_Req 7;
BA_ "GenSigSendType" SG_ 496 MHU_APA_ParkOut_Req 7;
BA_ "GenSigSendType" SG_ 496 MHU_APA_ParkingStart_Req 7;
BA_ "GenSigSendType" SG_ 496 MHU_APA_ParkingReCover_Req 7;
BA_ "GenSigSendType" SG_ 496 MHU_APA_ParkOut_Direction 7;
BA_ "GenSigSendType" SG_ 496 MHU_APA_ParkOut_Mode 7;
BA_ "GenSigSendType" SG_ 496 MHU_LSS_Req 7;
BA_ "GenSigSendType" SG_ 496 MHU_LSS_Mode 7;
BA_ "GenSigSendType" SG_ 496 MHU_LSS_WarningMethod 7;
BA_ "GenSigSendType" SG_ 496 MHU_TSR_Req 7;
BA_ "GenSigSendType" SG_ 496 TSR_SpdWarningOffs_S 7;
BA_ "GenSigSendType" SG_ 496 TSR_SLWFuncSwtReq 7;
BA_ "GenSigSendType" SG_ 496 AEB_FuncSwtReq 7;
BA_ "GenSigSendType" SG_ 496 AEB_FCW_SnvtyReq 7;
BA_ "GenSigSendType" SG_ 496 BSD_LCA_FuncSWReq 7;
BA_ "GenSigSendType" SG_ 496 RCTA_FuncSWReq 7;
BA_ "GenSigSendType" SG_ 496 DOW_FuncSWReq 7;
BA_ "GenSigSendType" SG_ 496 RCW_FuncSWReq 7;
BA_ "GenSigSendType" SG_ 496 MHU_APA_ParkingSpace_ID 7;
BA_ "GenSigInvalidValue" SG_ 497 Nav_errorSts 15;
BA_ "GenSigInvalidValue" SG_ 497 Nav_VehToTrafEyeDist 1023;
BA_ "GenSigStartValue" SG_ 497 Nav_VehToTrafEyeDist 1000;
BA_ "GenSigInvalidValue" SG_ 497 Nav_SpdLimValue 63;
BA_ "GenSigInvalidValue" SG_ 497 Nav_TSRTrafSign 63;
BA_ "GenSigStartValue" SG_ 617 WCBS_ACC_VLC_AccInTar 2240;
BA_ "GenSigSendType" SG_ 676 MHU_ESCOFF_SW_Sts 7;
BA_ "GenSigSendType" SG_ 676 MHU_VCU_CreepDisable_stt 7;
BA_ "GenSigSendType" SG_ 676 MHU_AVH_Req 7;
BA_ "GenSigSendType" SG_ 676 MHU_RegencyLevRequest 7;
BA_ "GenSigSendType" SG_ 676 MHU_DM_SwitchModeSts 7;
BA_ "GenSigSendType" SG_ 676 MHU_Trailermode_Req 7;
BA_ "GenSigSendType" SG_ 676 MHU_UPAMuteSwitch 7;
BA_ "GenSigStartValue" SG_ 994 ESC_VehDynYawRate 8192;
BA_ "GenSigStartValue" SG_ 811 CCU_evaporator_Temperature 10;
BA_ "GenSigStartValue" SG_ 811 CCU_ExternalTemperature 80;
BA_ "GenSigStartValue" SG_ 670 Time_Day 1;
BA_ "GenSigStartValue" SG_ 670 Time_Month 1;
BA_ "GenSigSendType" SG_ 1969 Diag_PhyReq 7;
BA_ "GenSigSendType" SG_ 1977 Diag_PhyResp 7;
BA_ "GenSigSendType" SG_ 2015 Diag_FuncReq 7;
VAL_ 128 ACU_CoDSeatOccupSensorStat 1 "Occupied" 0 "Empty" ;
VAL_ 128 ACU_DSeatOccupSensorStat 1 "Occupied" 0 "Empty" ;
VAL_ 128 ACU_CoDSeatbeltBucklestatus 1 "safety belt not tied(Switch on)" 0 "safety belt tied(Switch off )" ;
VAL_ 128 ACU_DSeatbeltBucklestatus 1 "safety belt not tied(Switch on)" 0 "safety belt tied(Switch off )" ;
VAL_ 128 ACU_CoDAirbagStatus 1 "点爆" 0 "未点爆" ;
VAL_ 128 ACU_DAirbagStatus 1 "点爆" 0 "未点爆" ;
VAL_ 128 ACU_RPSeatOccupSensorStat 1 "Occupied" 0 "Empty" ;
VAL_ 128 ACU_MPSeatOccupSensorStat 1 "Occupied" 0 "Empty" ;
VAL_ 128 ACU_LPSeatOccupSensorStat 1 "Occupied" 0 "Empty" ;
VAL_ 128 ACU_RCABsts 1 "点爆" 0 "未点爆" ;
VAL_ 128 ACU_LCABsts 1 "点爆" 0 "未点爆" ;
VAL_ 128 ACU_RSABsts 1 "点爆" 0 "未点爆" ;
VAL_ 128 ACU_LSABsts 1 "点爆" 0 "未点爆" ;
VAL_ 128 ACU_RPSeatbeltBucklestatus 1 "safety belt not tied(Switch on)" 0 "safety belt tied(Switch off )" ;
VAL_ 128 ACU_MPSeatbeltBucklestatus 1 "safety belt not tied(Switch on)" 0 "safety belt tied(Switch off )" ;
VAL_ 128 ACU_LPSeatbeltBucklestatus 1 "safety belt not tied(Switch on)" 0 "safety belt tied(Switch off )" ;
VAL_ 128 ACU_CrashSts 1 "Crashed" 0 "NO Crash" ;
VAL_ 128 ACU_CrashRearOutputSts 1 "Crashed" 0 "Normal" ;
VAL_ 128 ACU_CrashRightOutputSts 1 "Crashed" 0 "Normal" ;
VAL_ 128 ACU_CrashLeftOutputSts 1 "Crashed" 0 "Normal" ;
VAL_ 128 ACU_CrashFrontOutputSts 1 "Crashed" 0 "Normal" ;
VAL_ 128 ACU_AirbagWarningStatus 3 "Reserved" 2 "Flash_Reserved" 1 "ON" 0 "OFF" ;
VAL_ 128 ACU_CoDSeatbletPTighten 1 "点爆" 0 "未点爆" ;
VAL_ 128 ACU_DSeatbletPTighten 1 "点爆" 0 "未点爆" ;
VAL_ 290 ABS_FLWheelSpeedInvalid 1 "Invalid" 0 "Valid" ;
VAL_ 290 ABS_FRWheelSpeedInvalid 1 "Invalid" 0 "Valid" ;
VAL_ 290 ABS_FLWheelDirection 3 "Stop" 2 "Backward" 1 "Forward" 0 "Invalid" ;
VAL_ 290 ABS_FRWheelDirection 3 "Stop" 2 "Backward" 1 "Forward" 0 "Invalid" ;
VAL_ 291 ABS_RLWheelSpeedInvalid 1 "Invalid" 0 "Valid" ;
VAL_ 291 ABS_RRWheelSpeedInvalid 1 "Invalid" 0 "Valid" ;
VAL_ 291 ABS_RLWheelDirection 3 "Stop" 2 "Backward" 1 "Forward" 0 "Invalid" ;
VAL_ 291 ABS_RRWheelDirection 3 "Stop" 2 "Backward" 1 "Forward" 0 "Invalid" ;
VAL_ 292 ABS_FLWheelSpeedRCSts 1 "Invalid" 0 "Valid" ;
VAL_ 292 ABS_FRWheelSpeedRCSts 1 "Invalid" 0 "Valid" ;
VAL_ 292 ABS_RLWheelSpeedRCSts 1 "Invalid" 0 "Valid" ;
VAL_ 292 ABS_RRWheelSpeedRCSts 1 "Invalid" 0 "Valid" ;
VAL_ 262 BCM_TurnIndicatorSts 3 "Left and Right TurnLight" 2 "Right TurnLight" 1 "Left TurnLight" 0 "OFF" ;
VAL_ 262 BCM_PosLmpSts 3 "Signal Invalid" 2 "Fault" 1 "ON" 0 "OFF" ;
VAL_ 262 BCM_LowBeamSts 3 "Signal Invalid" 2 "Fault" 1 "ON" 0 "OFF" ;
VAL_ 262 BCM_HighBeamSts 3 "Signal Invalid" 2 "Fault" 1 "ON" 0 "OFF" ;
VAL_ 262 BCM_RearFogLampLightSts 3 "Signal Invalid" 2 "Fault" 1 "ON" 0 "OFF" ;
VAL_ 262 BCM_BrakeLightSts 3 "Signal Invalid" 2 "Fault" 1 "ON" 0 "OFF" ;
VAL_ 262 BCM_ReverseLightSts 3 "Signal Invalid" 2 "Fault" 1 "ON" 0 "OFF" ;
VAL_ 262 BCM_DayRunningLampSts 3 "Signal Invalid" 2 "Fault" 1 "ON" 0 "OFF" ;
VAL_ 262 BCM_RMarkerLightSts 3 "Signal Invalid" 2 "Fault" 1 "ON" 0 "OFF" ;
VAL_ 262 BCM_Rr_domelampSts 3 "Signal Invalid" 2 "Fault" 1 "ON" 0 "OFF" ;
VAL_ 262 BCM_Fr_domelampSts 3 "Signal Invalid" 2 "Fault" 1 "ON" 0 "OFF" ;
VAL_ 262 BCM_LicensePlateLightSts 3 "Signal Invalid" 2 "Fault" 1 "ON" 0 "OFF" ;
VAL_ 262 BCM_HeadLight_adjustSts 5 "4档" 4 "3档" 3 "2档" 2 "1档" 1 "0档" 0 "No Adjustment" ;
VAL_ 262 BCM_FrontFogLampLightSts 3 "Signal Invalid" 2 "Fault" 1 "ON" 0 "OFF" ;
VAL_ 262 BCM_STAT_InteriorLight 3 "Signal Invalid" 2 "Fault" 1 "ON" 0 "OFF" ;
VAL_ 262 BCM_TurnLight_FaultSts 3 "Left and Right TurnLight Fault" 2 "Right TurnLight Fault" 1 "Left TurnLight Fault" 0 "No Fault" ;
VAL_ 262 BCM_AmbeLightZone2Sts 3 "Signal Invalid" 2 "Fault" 1 "ON" 0 "OFF" ;
VAL_ 262 BCM_AmbeLightZone1Sts 3 "Signal Invalid" 2 "Fault" 1 "ON" 0 "OFF" ;
VAL_ 293 ABSActive 1 "Active" 0 "Inactive" ;
VAL_ 293 ABS_EBDFailed 1 "EBD Failed" 0 "EBD Normal" ;
VAL_ 293 ABSFailed 1 "ABS Failed" 0 "ABS Normal" ;
VAL_ 293 ABS_LowBrakeFluid 1 "failure" 0 "no failure" ;
VAL_ 293 ABS_VehicleSpeedInvalid 1 "Invalid" 0 "Valid" ;
VAL_ 293 ABS_HAZActive 1 "Emergency brake light on" 0 "Emergency brake light off" ;
VAL_ 306 ESC_MasterCylinderPressureV 1 "Invalid" 0 "Valid" ;
VAL_ 306 ESC_HSA_Control_Status 1 "Active" 0 "Inactive" ;
VAL_ 306 ESC_HSA_Status_Fault 1 "HSA Defective" 0 "HSA Normale" ;
VAL_ 306 ESC_TcsDisableSts 1 "Disabled" 0 "Enabled" ;
VAL_ 306 ESC_EscCtrlActv 1 "Active" 0 "Inactive" ;
VAL_ 306 ESC_TcsCtrlActv 1 "Active" 0 "Inactive" ;
VAL_ 306 ESC_EscFlgFlt 1 "Failure" 0 "No failure" ;
VAL_ 306 ESC_TcsFlgFlt 1 "Failure" 0 "No failure" ;
VAL_ 306 ESC_EscDisableSts 1 "Disabled" 0 "Enabled" ;
VAL_ 306 ESC_HBAFlgFlt 1 "Failure" 0 "No failure" ;
VAL_ 306 ESC_HbaCtrlActv 1 "Active" 0 "Inactive" ;
VAL_ 306 BAS_FlgFlt 1 "Failure" 0 "No failure" ;
VAL_ 306 BAS_CtrlActv 1 "Active" 0 "Inactive" ;
VAL_ 306 IBS_ESCOFF_StsFB 1 "ESC forbid" 0 "ESC enable" ;
VAL_ 382 SAS_SASStsSnsr 1 "sensor value valid" 0 "sensor value Invalid" ;
VAL_ 382 SAS_SteeringAngleValid 1 "Valid" 0 "Invalid" ;
VAL_ 382 SAS_SASFailure 1 "No Failure" 0 "Failure" ;
VAL_ 382 SAS_Calibrated 1 "Calibrated" 0 "Not Calibrated" ;
VAL_ 382 SAS_SteerWhlRotSpdStatus 1 "Valid" 0 "Invalid" ;
VAL_ 383 EPS_APA_CtrlAbortFeedback 5 "driver invention" 4 "Other reason" 3 "EPS own problem" 2 "Over Speed" 1 "EPS Failed" 0 "Normal" ;
VAL_ 383 EPS_SterMod 1 "AUTO" 0 "Manual" ;
VAL_ 383 EPS_SterModV 1 "Invalid" 0 "Valid" ;
VAL_ 383 EPS_ADAS_CtrlAbortFeedback 9 "CAN communication error" 8 "Driver invention" 7 "Reject due to request angle speed invalid" 6 "Reject due to request angle invalid" 5 "Reject due to speed" 4 "Reject due to priority" 3 "Reject due to error" 2 "EPS Init" 1 "Disable" 0 "Normal" ;
VAL_ 383 EPS_SterFltMod 1 "fault" 0 "normal" ;
VAL_ 383 EPS_DrStrTorqV 1 "Invalid" 0 "Valid" ;
VAL_ 383 EPS_APA_ModAvail 1 "Available" 0 "Not available" ;
VAL_ 383 EPS_APA_ModActv 1 "APA （自动泊车辅助）" 0 "No Request" ;
VAL_ 383 EPS_ADAS_ModActv 2 "Reserved" 1 "LSS" 0 "No Request" ;
VAL_ 383 EPS_ADAS_ModAvail 1 "Available" 0 "Not available" ;
VAL_ 465 ADAS_ACC_SpdUnit 1 "mph" 0 "kph" ;
VAL_ 465 ADAS_ACC_OperatingSts 8 "ACC Failure mode" 7 "VLC Failure mode" 6 "Standstill" 5 "Override" 4 "Brake-Only Mode" 3 "Active-Control Mode" 2 "StandBy Mode" 1 "Passive Mode" 0 "OFF Mode" ;
VAL_ 465 ADAS_ACC_TimeGapLevel 4 "TimeGap_4 2.1s" 3 "TimeGap_3 1.8s" 2 "TimeGap_2 1.4s" 1 "TimeGap_1 1s" 0 "No TimeGap Set" ;
VAL_ 465 ADAS_ACC_DistanceLevel 4 "Distance_4 four bars" 3 "Distance_3 three bars" 2 "Distance_2 two bars" 1 "Distance_1 one bar" 0 "No DistanceLevel Set" ;
VAL_ 465 ACC_ObjDispSts 1 "Target object detected" 0 "No object" ;
VAL_ 465 ACC_TakeOverReq 1 "Valid TakeOver request" 0 "No TakeOver request" ;
VAL_ 466 ADAS_LSS_AssidFormResp 1 "LCC ON" 0 "LKA ON" ;
VAL_ 466 ADAS_EPS_Vibration_Req 3 "Reserved" 2 "Reserved" 1 "Level 1" 0 "No Request" ;
VAL_ 466 ADAS_LSS_VoiceWarn 3 "Reserved" 2 "LCC Warning" 1 "LKA Warning" 0 "No Request" ;
VAL_ 466 ADAS_LSS_HandsoffWarn 7 "Reserved" 6 "Reserved" 5 "Reserved" 4 "Level4 warning" 3 "Level3 warning" 2 "Level2 warning" 1 "Level1 warning" 0 "No warning" ;
VAL_ 466 ADAS_LSS_FuncResp 1 "ON" 0 "OFF" ;
VAL_ 466 ADAS_EPS_AngReqSts 2 "Reserved" 1 "LSSActive" 0 "No request" ;
VAL_ 466 ADAS_LSS_LeLineTrackingSts 3 "Optical warning" 2 "Intervention" 1 "Line tracking" 0 "No display" ;
VAL_ 466 ADAS_LSS_RiLineTrackingSts 3 "Optical warning" 2 "Intervention" 1 "Line tracking" 0 "No display" ;
VAL_ 468 ADAS_IBS_StopReq 1 "Request" 0 "No request" ;
VAL_ 468 ADAS_IBS_CarStarting 1 "Request" 0 "No request" ;
VAL_ 468 ADAS_ACC_BrakePreferred 1 "Request" 0 "No request" ;
VAL_ 468 ADAS_AEB_AbpReq 1 "Request" 0 "No request" ;
VAL_ 468 ADAS_IBS_EBAReq 1 "Request" 0 "No request" ;
VAL_ 468 ADAS_IBS_MinBreakReq 1 "Request" 0 "No request" ;
VAL_ 468 ADAS_VLCShutDownReq 3 "No Request" 2 "Immediate off" 1 "Fast off" 0 "Soft off" ;
VAL_ 468 ADAS_VLCModeReq 7 "Failure" 6 "Stand Hold" 5 "Override" 4 "Brake Only mode" 3 "Active Control mode" 2 "Standby mode" 1 "Passive mode" 0 "OFF" ;
VAL_ 468 AEB_AWB_Level 15 "Resvered" 14 "Resvered" 13 "Resvered" 12 "Resvered" 11 "Resvered" 10 "Resvered" 9 "Resvered" 8 "Resvered" 7 "Resvered" 6 "Resvered" 5 "Resvered" 4 "Level 4" 3 "Level 3" 2 "Level 2" 1 "Level 1" 0 "No level" ;
VAL_ 468 AEB_ABA_Req 1 "Request" 0 "No Request" ;
VAL_ 468 AEB_VehHldReq 1 "Request" 0 "No Request" ;
VAL_ 468 AEB_TgtDecel_Req 1 "Request" 0 "No Request" ;
VAL_ 468 AEB_AWB_Req 1 "Request" 0 "No Request" ;
VAL_ 468 ADAS_AEB_AbaLevel 3 "Level 3高灵敏度" 2 "Level 2中灵敏度" 1 "Level 1低灵敏度" 0 "Level 0标准灵敏度(默认)" ;
VAL_ 470 ADAS_TSR_SWSts 1 "On" 0 "Off" ;
VAL_ 470 TSR_SLWSwtResp 1 "On" 0 "Off" ;
VAL_ 470 ADAS_TSR_OperationSts 4 "Fault" 3 "NavigationOnlyMode" 2 "VisionMode" 1 "FusionMode" 0 "Off" ;
VAL_ 470 ADAS_TSR_SpeedLimit 63 "Reserved" 62 "Reserved" 61 "Reserved" 60 "Reserved" 59 "Reserved" 58 "Reserved" 57 "Reserved" 56 "Reserved" 55 "Reserved" 54 "Reserved" 53 "Reserved" 52 "Reserved" 51 "Reserved" 50 "Reserved" 49 "Reserved" 48 "Reserved" 47 "Reserved" 46 "Reserved" 45 "Reserved" 44 "Reserved" 43 "Reserved" 42 "Reserved" 41 "Reserved" 40 "Reserved" 39 "Reserved" 38 "Reserved" 37 "Reserved" 36 "Reserved" 35 "Reserved" 34 "Reserved" 33 "Reserved" 32 "Reserved" 31 "SPL 150" 30 "SPL 145" 29 "SPL 140" 28 "SPL 135" 27 "SPL 130" 26 "SPL 125" 25 "SPL 120" 24 "SPL 115" 23 "SPL 110" 22 "SPL 105" 21 "SPL 100" 20 "SPL 95" 19 "SPL 90" 18 "SPL 85" 17 "SPL 80" 16 "SPL 75" 15 "SPL 70" 14 "SPL 65" 13 "SPL 60" 12 "SPL 55" 11 "SPL 50" 10 "SPL 45" 9 "SPL 40" 8 "SPL 35" 7 "SPL 30" 6 "SPL 25" 5 "SPL 20" 4 "SPL 15" 3 "SPL 10" 2 "SPL 5" 1 "SPL cancelled" 0 "No display" ;
VAL_ 470 ADAS_LSS_Available 1 "Not Available" 0 "Available" ;
VAL_ 470 ADAS_LSS_FunSts 3 "Reserved" 2 "LCC On" 1 "LKA On" 0 "Off" ;
VAL_ 470 ADAS_LSS_ErrSts 1 "error" 0 "No error" ;
VAL_ 470 ADAS_LSS_WarnFromResp 3 "Reserved" 2 "Voice+Haptic" 1 "Haptic" 0 "Voice" ;
VAL_ 470 FC_CalibrationSts 3 "Reserved" 2 "Calibration Failed" 1 "Calibration In Process" 0 "Calibration Success" ;
VAL_ 470 FC_BlockageSts 1 "Front Camera Blockage" 0 "Front Camera Not Blockage" ;
VAL_ 471 ADAS_APA_OperationSts 4 "Parking failure (APA end)" 3 "Parking success(APA end)" 2 "Parking" 1 "Park position detected" 0 "Not park" ;
VAL_ 471 ADAS_APA_ModeSelect 2 "自动泊出" 1 "自动泊入" 0 "无APA请求" ;
VAL_ 471 ADAS_APA_SystemSts 7 "Failure" 6 "Abort" 5 "Pause" 4 "Finish" 3 "Active" 2 "Enable" 1 "Standby" 0 "Off" ;
VAL_ 471 ADAS_APA_OverspeedAlarm 1 "Active" 0 "Inactive" ;
VAL_ 471 ADAS_APA_StartParkingReq 1 "Request" 0 "No request" ;
VAL_ 471 ADAS_APA_RenewParkingReq 1 "Request" 0 "No request" ;
VAL_ 471 ADAS_APA_PauseWarning 14 "Reserved" 13 "Reserved" 12 "Reserved" 11 "Reserved" 10 "Reserved" 9 "Reserved" 8 "Reserved" 7 "Reserved" 6 "Reserved" 5 "安全带松开（仅限主驾）" 4 "轨迹内有障碍物" 3 "前舱盖开启" 2 "尾门开启" 1 "车门开启" 0 "No Waring" ;
VAL_ 471 ADAS_APA_AbortWarning 19 "胎压不满足要求；" 18 "RCTA等主动安全功能激活；" 17 "ESC子功能激活；" 16 "车辆无法移动" 14 "车辆已移动，已退出泊车(仅泊出使用)" 13 "泊车空间受限" 12 "用户主动退出" 11 "档位无法切换" 10 "APA系统故障" 9 "车速超限" 8 "关联ECU故障" 7 "坡度过大" 6 "泊车次数超上限" 5 "驾驶员干预手刹" 4 "驾驶员干预方向盘" 3 "驾驶员干预油门" 2 "驾驶员干预档位" 1 "泊车超时" 0 "No Warning" ;
VAL_ 471 ADAS_APA_ParkingType 3 "inclined（斜列）" 2 "Vertical(垂直)" 1 "Horizontal(水平)" 0 "No Request" ;
VAL_ 471 ADAS_APA_ParkingDirection 2 "Right(向右)" 1 "Left(向左)" 0 "No Request" ;
VAL_ 472 ADAS_FrontCamera_Fault 1 "Fault" 0 "No fault" ;
VAL_ 472 ADAS_RearCamera_Fault 1 "Fault" 0 "No fault" ;
VAL_ 472 ADAS_LeftCamera_Fault 1 "Fault" 0 "No fault" ;
VAL_ 472 ADAS_RightCamera_Fault 1 "Fault" 0 "No fault" ;
VAL_ 472 ADAS_ECU_Fault 1 "Fault" 0 "No fault" ;
VAL_ 472 ACC_TxtInfoForDriver 31 "Reserved" 30 "Reserved" 29 "Reserved" 28 "Reserved" 27 "Reserved" 26 "Reserved" 25 "Reserved" 24 "Reserved" 23 "车速过高，自适应巡航已退出" 22 "前雷达被遮挡，自适应巡航功能无法激活" 21 "制动盘过热，自适应巡航功能无法激活" 20 "陡坡缓降工作中，自适应巡航功能无法激活" 19 "拖车模式开启，自适应巡航功能无法激活" 18 "制动紧急制动已启动，自适应巡航功能推出" 17 "泊车工作中，自适应巡航功能无法激活" 16 "请轻踩油门踏板或按下res+     按键" 15 "前车已驶离，请踩加速踏板起步" 14 "请确认WCBS功能是否开启" 13 "请确认EPB是否释放" 12 "请确认档位是否在D档" 11 "请确认车门是否关好" 10 "请确认安全带是否系上" 9 "请检查自适应巡航系统" 8 "ACC已关闭" 7 "ACC已开启" 6 "预留" 5 "危险请制动" 4 "超越加速中" 3 "ACC已激活" 2 "ACC取消" 1 "ACC无法激活" 0 "无显示" ;
VAL_ 472 ACC_DriveoffReq 7 "Reserved" 6 "Reserved" 5 "Reserved" 4 "The front car has started,please take over the car" 3 "The front car has started,please keep your attention" 2 "The front car has started,Please pay attention to the road environment ahead" 1 "The front car has started" 0 "no request" ;
VAL_ 475 ADAS_AEB_FuncSWResp 1 "ON" 0 "OFF" ;
VAL_ 475 AEB_FuncSts 1 "ON" 0 "OFF" ;
VAL_ 475 AEB_VehActive 1 "Active" 0 "No active" ;
VAL_ 475 AEB_VRUActive 1 "Active" 0 "No active" ;
VAL_ 475 AEB_ErrorSts 3 "Unavailable_Trailer Mode" 2 "Unavailable_WCBS OFF" 1 "Error" 0 "None" ;
VAL_ 475 AEB_FCW_SnvtyResp 3 "Low sensitivity" 2 "High sensitivity" 1 "Normal" 0 "OFF" ;
VAL_ 475 TSR_TrafSign 255 "Invalid supp" 254 "Reserved" 253 "Reserved" 252 "Reserved" 251 "Reserved" 250 "Reserved" 249 "Reserved" 248 "Reserved" 247 "Reserved" 246 "Reserved" 245 "Reserved" 244 "Reserved" 243 "Reserved" 242 "Reserved" 241 "Reserved" 240 "Reserved" 239 "Reserved" 238 "Reserved" 237 "Reserved" 236 "Reserved" 235 "Reserved" 234 "Reserved" 233 "Reserved" 232 "Reserved" 231 "Reserved" 230 "Reserved" 229 "Reserved" 228 "Reserved" 227 "Reserved" 226 "Reserved" 225 "Reserved" 224 "Reserved" 223 "Reserved" 222 "Reserved" 221 "Reserved" 220 "Reserved" 219 "Reserved" 218 "Reserved" 217 "Reserved" 216 "Reserved" 215 "Reserved" 214 "Reserved" 213 "Reserved" 212 "Reserved" 211 "Reserved" 210 "Reserved" 209 "Reserved" 208 "Reserved" 207 "Reserved" 206 "Reserved" 205 "Reserved" 204 "Reserved" 203 "Reserved" 202 "Reserved" 201 "Reserved" 200 "Reserved" 199 "Reserved" 198 "Reserved" 197 "Reserved" 196 "Reserved" 195 "Reserved" 194 "Reserved" 193 "Reserved" 192 "Reserved" 191 "Reserved" 190 "Reserved" 189 "Reserved" 188 "Reserved" 187 "Reserved" 186 "Reserved" 185 "Reserved" 184 "Reserved" 183 "Reserved" 182 "Reserved" 181 "Reserved" 180 "Reserved" 179 "Reserved" 178 "Reserved" 177 "Reserved" 176 "Reserved" 175 "Reserved" 174 "Reserved" 173 "Reserved" 172 "Reserved" 171 "Reserved" 170 "Reserved" 169 "Reserved" 168 "Reserved" 167 "Reserved" 166 "Reserved" 165 "Reserved" 164 "Reserved" 163 "Reserved" 162 "Reserved" 161 "Reserved" 160 "Reserved" 159 "Reserved" 158 "Reserved" 157 "Reserved" 156 "Reserved" 155 "Reserved" 154 "Reserved" 153 "Reserved" 152 "Reserved" 151 "Reserved" 150 "Reserved" 149 "Reserved" 148 "Reserved" 147 "Reserved" 146 "Reserved" 145 "Reserved" 144 "Reserved" 143 "Reserved" 142 "Reserved" 141 "Reserved" 140 "Reserved" 139 "Reserved" 138 "Reserved" 137 "Reserved" 136 "Reserved" 135 "Reserved" 134 "Reserved" 133 "Reserved" 132 "Reserved" 131 "Reserved" 130 "Reserved" 129 "Reserved" 128 "Reserved" 127 "Reserved" 126 "Reserved" 125 "Reserved" 124 "Reserved" 123 "Reserved" 122 "Reserved" 121 "Reserved" 120 "Reserved" 119 "Reserved" 118 "Reserved" 117 "Reserved" 116 "Reserved" 115 "Reserved" 114 "Reserved" 113 "Reserved" 112 "Reserved" 111 "Reserved" 110 "Reserved" 109 "Reserved" 108 "Reserved" 107 "Reserved" 106 "Reserved" 105 "Reserved" 104 "Reserved" 103 "Reserved" 102 "Reserved" 101 "Reserved" 100 "Reserved" 99 "Reserved" 98 "Reserved" 97 "Reserved" 96 "Reserved" 95 "Reserved" 94 "Reserved" 93 "Reserved" 92 "Reserved" 91 "Reserved" 90 "Reserved" 89 "Reserved" 88 "Reserved" 87 "Reserved" 86 "Reserved" 85 "Reserved" 84 "Reserved" 83 "Reserved" 82 "Reserved" 81 "Reserved" 80 "Reserved" 79 "Reserved" 78 "Reserved" 77 "Reserved" 76 "Reserved" 75 "Reserved" 74 "Reserved" 73 "Reserved" 72 "Reserved" 71 "Reserved" 70 "Reserved" 69 "Reserved" 68 "Reserved" 67 "Reserved" 66 "Reserved" 65 "Reserved" 64 "Reserved" 63 "Reserved" 62 "Reserved" 61 "End no pass" 60 "No pass" 59 "No entrance" 58 "Stop" 57 "Yield" 56 "Traffic signals" 55 "Roundabout" 54 "Pedestrains crossing" 53 "Children" 52 "Bicycle corssing" 51 "Double curve right" 50 "Double curve left" 49 "Curve right" 48 "Curve left" 47 "Reserved" 46 "Reserved" 45 "Reserved" 44 "Reserved" 43 "Reserved" 42 "Reserved" 41 "Reserved" 40 "Reserved" 39 "Reserved" 38 "Reserved" 37 "Non-numerical speed limit" 36 "Vehicle &VRU zones Exit" 35 "Vehicle &VRU zones Entry" 34 "Implicit Perceived Speed limit in Hungary 01" 33 "Implicit Perceived Speed limit in Spain 01" 32 "Numerical Zones Exit" 31 "Numerical Zones Entry" 30 "VRU zones Exit" 29 "VRU zones Entry" 28 "School zones Exit" 27 "School zones Entry" 26 "Bicycle zones Exit" 25 "Bicycle zones Entry" 24 "Pedestrian  zones Exit" 23 "Pedestrian  zones Entry" 22 "Residential zones Exit" 21 "Residential zones Entry" 20 "City Exit" 19 "City Entry" 18 "Expressway End" 17 "Expressway Start" 16 "Motorway End" 15 "Motorway Start" 14 "Trailer" 13 "Arrow_turnleftright" 12 "Arrow_frontageright" 11 "Arrow_frontageleft" 10 "BendArrow_right" 9 "BendArrow_left" 8 "Arrow_right" 7 "Arrow_left" 6 "Arrow_Straight" 5 "Distance in" 4 "Distance for" 3 "Time" 2 "Snow/Icy" 1 "Rain/Wetness" 0 "None" ;
VAL_ 475 TSR_SpdAssistInfoDisp 255 "Invalid supp" 254 "Reserved" 253 "Reserved" 252 "Reserved" 251 "Reserved" 250 "Reserved" 249 "Reserved" 248 "Reserved" 247 "Reserved" 246 "Reserved" 245 "Reserved" 244 "Reserved" 243 "Reserved" 242 "Reserved" 241 "Reserved" 240 "Reserved" 239 "Reserved" 238 "Reserved" 237 "Reserved" 236 "Reserved" 235 "Reserved" 234 "Reserved" 233 "Reserved" 232 "Reserved" 231 "Reserved" 230 "Reserved" 229 "Reserved" 228 "Reserved" 227 "Reserved" 226 "Reserved" 225 "Reserved" 224 "Reserved" 223 "Reserved" 222 "Reserved" 221 "Reserved" 220 "Reserved" 219 "Reserved" 218 "Reserved" 217 "Reserved" 216 "Reserved" 215 "Reserved" 214 "Reserved" 213 "Reserved" 212 "Reserved" 211 "Reserved" 210 "Reserved" 209 "Reserved" 208 "Reserved" 207 "Reserved" 206 "Reserved" 205 "Reserved" 204 "Reserved" 203 "Reserved" 202 "Reserved" 201 "Reserved" 200 "Reserved" 199 "Reserved" 198 "Reserved" 197 "Reserved" 196 "Reserved" 195 "Reserved" 194 "Reserved" 193 "Reserved" 192 "Reserved" 191 "Reserved" 190 "Reserved" 189 "Reserved" 188 "Reserved" 187 "Reserved" 186 "Reserved" 185 "Reserved" 184 "Reserved" 183 "Reserved" 182 "Reserved" 181 "Reserved" 180 "Reserved" 179 "Reserved" 178 "Reserved" 177 "Reserved" 176 "Reserved" 175 "Reserved" 174 "Reserved" 173 "Reserved" 172 "Reserved" 171 "Reserved" 170 "Reserved" 169 "Reserved" 168 "Reserved" 167 "Reserved" 166 "Reserved" 165 "Reserved" 164 "Reserved" 163 "Reserved" 162 "Reserved" 161 "Reserved" 160 "Reserved" 159 "Reserved" 158 "Reserved" 157 "Reserved" 156 "Reserved" 155 "Reserved" 154 "Reserved" 153 "Reserved" 152 "Reserved" 151 "Reserved" 150 "Reserved" 149 "Reserved" 148 "Reserved" 147 "Reserved" 146 "Reserved" 145 "Reserved" 144 "Reserved" 143 "Reserved" 142 "Reserved" 141 "Reserved" 140 "Reserved" 139 "Reserved" 138 "Reserved" 137 "Reserved" 136 "Reserved" 135 "Reserved" 134 "Reserved" 133 "Reserved" 132 "Reserved" 131 "Reserved" 130 "Reserved" 129 "Reserved" 128 "Reserved" 127 "Reserved" 126 "Reserved" 125 "Reserved" 124 "Reserved" 123 "Reserved" 122 "Reserved" 121 "Reserved" 120 "Reserved" 119 "Reserved" 118 "Reserved" 117 "Reserved" 116 "Reserved" 115 "Reserved" 114 "Reserved" 113 "Reserved" 112 "Reserved" 111 "Reserved" 110 "Reserved" 109 "Reserved" 108 "Reserved" 107 "Reserved" 106 "Reserved" 105 "Reserved" 104 "Reserved" 103 "Reserved" 102 "Reserved" 101 "Reserved" 100 "Reserved" 99 "Reserved" 98 "Reserved" 97 "Reserved" 96 "Reserved" 95 "Reserved" 94 "Reserved" 93 "Reserved" 92 "Reserved" 91 "Reserved" 90 "Reserved" 89 "Reserved" 88 "Reserved" 87 "Reserved" 86 "Reserved" 85 "Reserved" 84 "Reserved" 83 "Reserved" 82 "Reserved" 81 "Reserved" 80 "Reserved" 79 "Reserved" 78 "Reserved" 77 "Reserved" 76 "Reserved" 75 "Reserved" 74 "Reserved" 73 "Reserved" 72 "Reserved" 71 "Reserved" 70 "Reserved" 69 "Reserved" 68 "Reserved" 67 "Reserved" 66 "Reserved" 65 "Reserved" 64 "Reserved" 63 "Reserved" 62 "Reserved" 61 "End no pass" 60 "No pass" 59 "No entrance" 58 "Stop" 57 "Yield" 56 "Traffic signals" 55 "Roundabout" 54 "Pedestrains crossing" 53 "Children" 52 "Bicycle corssing" 51 "Double curve right" 50 "Double curve left" 49 "Curve right" 48 "Curve left" 47 "Reserved" 46 "Reserved" 45 "Reserved" 44 "Reserved" 43 "Reserved" 42 "Reserved" 41 "Reserved" 40 "Reserved" 39 "Reserved" 38 "Reserved" 37 "Non-numerical speed limit" 36 "Vehicle &VRU zones Exit" 35 "Vehicle &VRU zones Entry" 34 "Implicit Perceived Speed limit in Hungary 01" 33 "Implicit Perceived Speed limit in Spain 01" 32 "Numerical Zones Exit" 31 "Numerical Zones Entry" 30 "VRU zones Exit" 29 "VRU zones Entry" 28 "School zones Exit" 27 "School zones Entry" 26 "Bicycle zones Exit" 25 "Bicycle zones Entry" 24 "Pedestrian  zones Exit" 23 "Pedestrian  zones Entry" 22 "Residential zones Exit" 21 "Residential zones Entry" 20 "City Exit" 19 "City Entry" 18 "Expressway End" 17 "Expressway Start" 16 "Motorway End" 15 "Motorway Start" 14 "Trailer" 13 "Arrow_turnleftright" 12 "Arrow_frontageright" 11 "Arrow_frontageleft" 10 "BendArrow_right" 9 "BendArrow_left" 8 "Arrow_right" 7 "Arrow_left" 6 "Arrow_Straight" 5 "Distance in" 4 "Distance for" 3 "Time" 2 "Snow/Icy" 1 "Rain/Wetness" 0 "None" ;
VAL_ 475 TSR_WarningOffset 15 "Reserved" 14 "Reserved" 13 "Reserved" 12 "Reserved" 11 "Reserved" 10 "Reserved" 9 "Reserved" 8 "+5（MPH）" 7 "+3（MPH）" 6 "-3（MPH）" 5 "-5（MPH）" 4 "+10（KPH）" 3 "+5（KPH）" 2 "-5（KPH）" 1 "-10（KPH）" 0 "0" ;
VAL_ 475 TSR_SLWVisualWarn 1 "Request" 0 "No Request" ;
VAL_ 475 TSR_SLWVoiceWarn 1 "Request" 0 "No Request" ;
VAL_ 475 AEB_FCW_Warning 3 "Reserved" 2 "warning Level 1" 1 "Latent warning" 0 "No warning" ;
VAL_ 476 BSD_LCA_FuncSwtResp 1 "ON" 0 "OFF" ;
VAL_ 476 RCTA_FuncSwtResp 1 "ON" 0 "OFF" ;
VAL_ 476 RCTA_FuncSts 3 "Fault" 2 "Active" 1 "Passive" 0 "OFF" ;
VAL_ 476 RCW_FuncSts 3 "Fault" 2 "Active" 1 "Passive" 0 "OFF" ;
VAL_ 476 RCR_SysErrorSts 3 "Revered" 2 "Unavailable_Trailer Mode" 1 "Error" 0 "No Error" ;
VAL_ 476 BSD_LCA_FuncSts 3 "Fault" 2 "Active" 1 "Passive" 0 "OFF" ;
VAL_ 476 BSD_LCA_WarningReqRight 3 "Revered" 2 "Warning level2" 1 "Warning level1" 0 "No warning" ;
VAL_ 476 RCR_BlockagedSts 1 "Blindness" 0 "No Blindness" ;
VAL_ 476 RCW_FuncSwtResp 1 "ON" 0 "OFF" ;
VAL_ 476 BSD_LCA_WarningReqLeft 3 "Revered" 2 "Warning level2" 1 "Warning level1" 0 "No warning" ;
VAL_ 476 RCR_VoiceWarningReq 3 "Warning level3(长响）" 2 "Warning level2(4Hz)" 1 "Warning level1(2Hz)" 0 "No warning" ;
VAL_ 476 RCTA_WarningReqRight 1 "Warning" 0 "No warning" ;
VAL_ 476 RCTA_WarningReqLeft 1 "Warning" 0 "No warning" ;
VAL_ 476 RCW_WarningReq 1 "Warning" 0 "No warning" ;
VAL_ 476 RCW_Hazard_lightReq 1 "Request" 0 "No Request" ;
VAL_ 476 DOW_WarningReqRight 3 "Reserved" 2 "Warning level2" 1 "Warning level1" 0 "No warning" ;
VAL_ 476 DOW_WarningReqLeft 3 "Reserved" 2 "Warning level2" 1 "Warning level1" 0 "No warning" ;
VAL_ 476 DOW_FuncSts 3 "Fault" 2 "Active" 1 "Passive" 0 "OFF" ;
VAL_ 476 DOW_FuncSwtResp 1 "ON" 0 "OFF" ;
VAL_ 477 ADAS_APA_Soundremind 6 "泊车完成" 5 "泊车失败" 4 "泊车暂停" 3 "泊车进行中" 2 "泊车开始" 1 "找到车位" 0 "No Waring" ;
VAL_ 477 ADAS_APA_ParkingModeReq 1 "Request" 0 "No request" ;
VAL_ 477 ADAS_APA_OtherWarning 7 "Reserved" 6 "Reserved" 5 "Reserved" 4 "Reserved" 3 "Reserved" 2 "该泊出类型不支持，请重新选择" 1 "该泊出方向不支持，请重新选择" 0 "No Waring" ;
VAL_ 477 ADAS_APA_RemindTxt1 14 "Reserved" 13 "Reserved" 12 "Reserved" 11 "Reserved" 10 "拖车钩存在" 9 "车速超限" 8 "电源模式错误" 7 "ACC开启" 6 "VCU故障" 5 "胎压不满足要求" 4 "EPB故障" 3 "WCBS故障" 2 "EPS故障" 1 "APA系统故障" 0 "No Warning" ;
VAL_ 477 ADAS_APA_RemindTxt2 14 "Reserved" 13 "Reserved" 12 "Reserved" 11 "Reserved" 10 "Reserved" 9 "Reserved" 8 "Reserved" 7 "Reserved" 6 "Reserved" 5 "请松开刹车" 4 "请松开方向盘" 3 "请挂入P档" 2 "已找到车位" 1 "请向前行驶搜索车位" 0 "No Waring" ;
VAL_ 477 ADAS_APA_LightReq 3 "Hazard light request" 2 "Right Request" 1 "Lift Request" 0 "No Request" ;
VAL_ 477 ADAS_APA_SearchingWarning 14 "Reserved" 13 "Reserved" 12 "Reserved" 11 "Reserved" 10 "Reserved" 9 "Reserved" 8 "Reserved" 7 "Reserved" 6 "Reserved" 5 "Reserved" 4 "车辆过快、请减速" 3 "前舱盖开启" 2 "尾门开启" 1 "车门开启" 0 "No Waring" ;
VAL_ 981 APA_FrontSystemSts 3 "Failed" 2 "Active" 1 "Standby" 0 "Disabled" ;
VAL_ 981 APA_RearSystemSts 3 "Failed" 2 "Active" 1 "Standby" 0 "Disabled" ;
VAL_ 981 APA_ChimeRequest 9 "系统故障" 8 "后UPA长鸣" 7 "后UPA间歇鸣叫1（4Hz）" 6 "后UPA间歇鸣叫2（2Hz）" 5 "后UPA间歇鸣叫3（1Hz）" 4 "前UPA长鸣" 3 "前UPA间歇鸣叫1（4Hz）" 2 "前UPA间歇鸣叫2（2Hz）" 1 "前UPA间歇鸣叫3（1Hz）" 0 "无声音请求" ;
VAL_ 981 APA_FRegion1ObjectSts 7 "无效invalid" 6 "Reserved预留" 5 "探头故障" 4 "Zone4" 3 "Zone3" 2 "Zone2" 1 "Zone1" 0 "无障碍物" ;
VAL_ 981 APA_FRegion2ObjectSts 7 "无效invalid" 6 "Reserved预留" 5 "探头故障" 4 "Zone4" 3 "Zone3" 2 "Zone2" 1 "Zone1" 0 "无障碍物" ;
VAL_ 981 APA_FRegion3ObjectSts 7 "无效invalid" 6 "Reserved预留" 5 "探头故障" 4 "Zone4" 3 "Zone3" 2 "Zone2" 1 "Zone1" 0 "无障碍物" ;
VAL_ 981 APA_FRegion4ObjectSts 7 "无效invalid" 6 "Reserved预留" 5 "探头故障" 4 "Zone4" 3 "Zone3" 2 "Zone2" 1 "Zone1" 0 "无障碍物" ;
VAL_ 981 APA_ParkAssistRRegion1ObjectSts 7 "无效invalid" 6 "Reserved预留" 5 "探头故障" 4 "Zone4" 3 "Zone3" 2 "Zone2" 1 "Zone1" 0 "无障碍物" ;
VAL_ 981 APA_ParkAssistRRegion2ObjectSts 7 "无效invalid" 6 "Reserved预留" 5 "探头故障" 4 "Zone4" 3 "Zone3" 2 "Zone2" 1 "Zone1" 0 "无障碍物" ;
VAL_ 981 APA_ParkAssistRRegion3ObjectSts 7 "无效invalid" 6 "Reserved预留" 5 "探头故障" 4 "Zone4" 3 "Zone3" 2 "Zone2" 1 "Zone1" 0 "无障碍物" ;
VAL_ 981 APA_ParkAssistRRegion4ObjectSts 7 "无效invalid" 6 "Reserved预留" 5 "探头故障" 4 "Zone4" 3 "Zone3" 2 "Zone2" 1 "Zone1" 0 "无障碍物" ;
VAL_ 982 ADAS_USS_FaultFLI 1 "Fault" 0 "No fault" ;
VAL_ 982 ADAS_USS_FaultFRI 1 "Fault" 0 "No fault" ;
VAL_ 982 ADAS_USS_FaultFLO 1 "Fault" 0 "No fault" ;
VAL_ 982 ADAS_USS_FaultFRO 1 "Fault" 0 "No fault" ;
VAL_ 982 ADAS_USS_FaultFLS 1 "Fault" 0 "No fault" ;
VAL_ 982 ADAS_USS_FaultFRS 1 "Fault" 0 "No fault" ;
VAL_ 983 ADAS_USS_FaultRLI 1 "Fault" 0 "No fault" ;
VAL_ 983 ADAS_USS_FaultRLO 1 "Fault" 0 "No fault" ;
VAL_ 983 ADAS_USS_FaultRRI 1 "Fault" 0 "No fault" ;
VAL_ 983 ADAS_USS_FaultRRO 1 "Fault" 0 "No fault" ;
VAL_ 983 ADAS_USS_FaultRLS 1 "Fault" 0 "No fault" ;
VAL_ 983 ADAS_USS_FaultRRS 1 "Fault" 0 "No fault" ;
VAL_ 504 APA_EPS_AngReqSts 1 "APAActive" 0 "No request" ;
VAL_ 504 ADAS_APA_BrakeModeSts 5 "Abort(泊车中断模式)" 4 "Suspend(泊车暂停模式)" 3 "Finish(泊车完成模式)" 2 "Active(泊车激活模式)" 1 "Standby(功能待命模式)" 0 "OFF(功能关闭模式(默认))" ;
VAL_ 504 APA_WCB_BrakeFunctionMode 7 "Reserved" 6 "Reserved" 5 "Reserved" 4 "Reserved" 3 "Automated Parking" 2 "Emergency Brake" 1 "Comfortable Brake" 0 "No request" ;
VAL_ 504 APA_WCB_ExpectedGearPosition 7 "Invalid" 6 "Reserved" 5 "Reserved" 4 "D" 3 "N" 2 "R" 1 "P" 0 "No request" ;
VAL_ 945 APA_slot_ID_1_Type 3 "inclined（斜列库位）" 2 "horizontal（水平库位）" 1 "vertical（垂直库位）" 0 "No Action" ;
VAL_ 946 APA_slot_ID_2_Type 3 "inclined（斜列库位）" 2 "horizontal（水平库位）" 1 "vertical（垂直库位）" 0 "No Action" ;
VAL_ 947 APA_slot_ID_3_Type 3 "inclined（斜列库位）" 2 "horizontal（水平库位）" 1 "vertical（垂直库位）" 0 "No Action" ;
VAL_ 948 APA_slot_ID_4_Type 3 "inclined（斜列库位）" 2 "horizontal（水平库位）" 1 "vertical（垂直库位）" 0 "No Action" ;
VAL_ 949 APA_slot_ID_5_Type 3 "inclined（斜列库位）" 2 "horizontal（水平库位）" 1 "vertical（垂直库位）" 0 "No Action" ;
VAL_ 950 APA_slot_ID_6_Type 3 "inclined（斜列库位）" 2 "horizontal（水平库位）" 1 "vertical（垂直库位）" 0 "No Action" ;
VAL_ 951 APA_slot_ID_7_Type 3 "inclined（斜列库位）" 2 "horizontal（水平库位）" 1 "vertical（垂直库位）" 0 "No Action" ;
VAL_ 952 APA_slot_ID_8_Type 3 "inclined（斜列库位）" 2 "horizontal（水平库位）" 1 "vertical（垂直库位）" 0 "No Action" ;
VAL_ 953 APA_slot_ID_9_Type 3 "inclined（斜列库位）" 2 "horizontal（水平库位）" 1 "vertical（垂直库位）" 0 "No Action" ;
VAL_ 954 APA_slot_ID_10_Type 3 "inclined（斜列库位）" 2 "horizontal（水平库位）" 1 "vertical（垂直库位）" 0 "No Action" ;
VAL_ 955 APA_slot_ID_11_Type 3 "inclined（斜列库位）" 2 "horizontal（水平库位）" 1 "vertical（垂直库位）" 0 "No Action" ;
VAL_ 956 APA_slot_ID_12_Type 3 "inclined（斜列库位）" 2 "horizontal（水平库位）" 1 "vertical（垂直库位）" 0 "No Action" ;
VAL_ 496 MHU_APA_Req 2 "No Request" 1 "Request" 0 "No Action" ;
VAL_ 496 MHU_APA_ParkIn_Req 2 "No Request" 1 "Request" 0 "No Action" ;
VAL_ 496 MHU_APA_ParkOut_Req 2 "No Request" 1 "Request" 0 "No Action" ;
VAL_ 496 MHU_APA_ParkingStart_Req 2 "No Request" 1 "Request" 0 "No Action" ;
VAL_ 496 MHU_APA_ParkingReCover_Req 2 "No Request" 1 "Request" 0 "No Action" ;
VAL_ 496 MHU_APA_ParkOut_Direction 2 "右" 1 "左" 0 "No Action" ;
VAL_ 496 MHU_APA_ParkOut_Mode 3 "inclined（斜列泊出）" 2 "horizontal（水平泊出）" 1 "vertical（垂直泊出）" 0 "No Action" ;
VAL_ 496 MHU_LSS_Req 2 "OFF" 1 "ON" 0 "No Action" ;
VAL_ 496 MHU_LSS_Mode 2 "LCC ON" 1 "LKA ON" 0 "No Action" ;
VAL_ 496 MHU_LSS_WarningMethod 3 "Voice+Haptic" 2 "Haptic" 1 "Voice" 0 "No Action" ;
VAL_ 496 MHU_TSR_Req 2 "No Request" 1 "Request" 0 "No Action" ;
VAL_ 496 TSR_SpdWarningOffs_S 9 "+5（MPH）" 8 "+3（MPH）" 7 "-3（MPH）" 6 "-5（MPH）" 5 "+10（KPH）" 4 "+5（KPH）" 3 "-5（KPH）" 2 "-10（KPH）" 1 "0（KPH）" 0 "No Action" ;
VAL_ 496 TSR_SLWFuncSwtReq 2 "OFF" 1 "ON" 0 "No Action" ;
VAL_ 496 AEB_FuncSwtReq 2 "OFF" 1 "ON" 0 "No Action" ;
VAL_ 496 AEB_FCW_SnvtyReq 4 "Low sensitivity" 3 "High sensitivity" 2 "Normal" 1 "OFF" 0 "No Action" ;
VAL_ 496 BSD_LCA_FuncSWReq 2 "OFF" 1 "ON" 0 "No Action" ;
VAL_ 496 RCTA_FuncSWReq 2 "OFF" 1 "ON" 0 "No Action" ;
VAL_ 496 DOW_FuncSWReq 2 "OFF" 1 "ON" 0 "No Action" ;
VAL_ 496 RCW_FuncSWReq 2 "OFF" 1 "ON" 0 "No Action" ;
VAL_ 497 Nav_RoadType 15 "Reserved" 14 "Reserved" 13 "Reserved" 12 "Reserved" 11 "Reserved" 10 "Channel" 9 "Side rode" 8 "Tunnel" 7 "ramp" 6 "City or Village rode" 5 "County rode" 4 "Provincial rode" 3 "National rode" 2 "City expressway" 1 "Expressway" 0 "Unknown" ;
VAL_ 497 Nav_errorSts 1 "error" 0 "no error" ;
VAL_ 497 Nav_SpdLimValue 63 "Invalid" 62 "Reserved" 61 "Reserved" 60 "Reserved" 59 "Reserved" 58 "Reserved" 57 "Reserved" 56 "Reserved" 55 "Reserved" 54 "Reserved" 53 "Reserved" 52 "Reserved" 51 "Reserved" 50 "Reserved" 49 "Reserved" 48 "Reserved" 47 "Reserved" 46 "Reserved" 45 "Reserved" 44 "Reserved" 43 "Reserved" 42 "Reserved" 41 "Reserved" 40 "Reserved" 39 "Reserved" 38 "Reserved" 37 "Reserved" 36 "Reserved" 35 "Reserved" 34 "Reserved" 33 "Reserved" 32 "Reserved" 31 "Reserved" 30 "SPL 150" 29 "SPL 145" 28 "SPL 140" 27 "SPL 135" 26 "SPL 130" 25 "SPL 125" 24 "SPL 120" 23 "SPL 115" 22 "SPL 110" 21 "SPL 105" 20 "SPL 100" 19 "SPL 95" 18 "SPL 90" 17 "SPL 85" 16 "SPL 80" 15 "SPL 75" 14 "SPL 70" 13 "SPL 65" 12 "SPL 60" 11 "SPL 55" 10 "SPL 50" 9 "SPL 45" 8 "SPL 40" 7 "SPL 35" 6 "SPL 30" 5 "SPL 25" 4 "SPL 20" 3 "SPL 15" 2 "SPL 10" 1 "SPL 5" 0 "No Display" ;
VAL_ 497 Nav_SpdLimType 3 "Rode Default" 2 "Electronic eye" 1 "Traffic sign" 0 "Unknown" ;
VAL_ 497 Nav_SpdLimUnit 3 "Reserved" 2 "MPH" 1 "KMH" 0 "Unknown" ;
VAL_ 497 Nav_TSRTrafSign 63 "Invalid supp" 62 "Reserved" 61 "Reserved" 60 "Reserved" 59 "Reserved" 58 "Reserved" 57 "Reserved" 56 "Reserved" 55 "Reserved" 54 "Reserved" 53 "Reserved" 52 "Reserved" 51 "Reserved" 50 "Reserved" 49 "Reserved" 48 "Reserved" 47 "Reserved" 46 "Reserved" 45 "End no pass" 44 "No pass" 43 "No entrance" 42 "Stop" 41 "Yield" 40 "Traffic signals" 39 "Roundabout" 38 "Pedestrains crossing" 37 "Children" 36 "Bicycle corssing" 35 "Double curve right" 34 "Double curve left" 33 "Curve right" 32 "Curve left" 31 "Reserved" 30 "Reserved" 29 "Reserved" 28 "Reserved" 27 "Reserved" 26 "Reserved" 25 "Reserved" 24 "Reserved" 23 "Reserved" 22 "Residential zones Exit" 21 "Residential zones Entry" 20 "City Exit" 19 "City Entry" 18 "Motorway End" 17 "Motorway Start" 16 "Highway End" 15 "Highway Start" 14 "Trailer" 13 "Arrow_turnleftright" 12 "Arrow_frontageright" 11 "Arrow_frontageleft" 10 "BendArrow_right" 9 "BendArrow_left" 8 "Arrow_right" 7 "Arrow_left" 6 "Arrow_Straight" 5 "Distance in" 4 "Distance for" 3 "Time" 2 "Snow/Icy" 1 "Rain/Wetness" 0 "None" ;
VAL_ 498 Nav_TimeMod 1 "12" 0 "24" ;
VAL_ 498 Nav_TimeIndcn 2 "pm" 1 "am" 0 "Invalid" ;
VAL_ 514 BCM_FLWin_Postion 11 "Position11(100%)" 10 "Position10(90%)" 9 "Position9(80%)" 8 "Position8(70%)" 7 "Position7(60%)" 6 "Position6(50%)" 5 "Position5(40%)" 4 "Position4(30%)" 3 "Position3(20%)" 2 "Position2(10%)" 1 "Position1(0%)" 0 "No Request" ;
VAL_ 514 BCM_FRWin_Postion 11 "Position11(100%)" 10 "Position10(90%)" 9 "Position9(80%)" 8 "Position8(70%)" 7 "Position7(60%)" 6 "Position6(50%)" 5 "Position5(40%)" 4 "Position4(30%)" 3 "Position3(20%)" 2 "Position2(10%)" 1 "Position1(0%)" 0 "No Request" ;
VAL_ 514 BCM_RLWinIN_Postion 11 "Position11(100%)" 10 "Position10(90%)" 9 "Position9(80%)" 8 "Position8(70%)" 7 "Position7(60%)" 6 "Position6(50%)" 5 "Position5(40%)" 4 "Position4(30%)" 3 "Position3(20%)" 2 "Position2(10%)" 1 "Position1(0%)" 0 "No Request" ;
VAL_ 514 BCM_RRWin_Postion 11 "Position11(100%)" 10 "Position10(90%)" 9 "Position9(80%)" 8 "Position8(70%)" 7 "Position7(60%)" 6 "Position6(50%)" 5 "Position5(40%)" 4 "Position4(30%)" 3 "Position3(20%)" 2 "Position2(10%)" 1 "Position1(0%)" 0 "No Request" ;
VAL_ 514 BCM_WinLockSts 1 "Window Locked" 0 "Window Unlock" ;
VAL_ 514 BCM_RLWinAntipinchSts 1 "Anti-pinch Active" 0 "Normal" ;
VAL_ 514 BCM_RRWinAntipinchSts 1 "Anti-pinch Active" 0 "Normal" ;
VAL_ 514 BCM_FLWinAntipinchSts 1 "Anti-pinch Active" 0 "Normal" ;
VAL_ 514 BCM_FRWinAntipinchSts 1 "Anti-pinch Active" 0 "Normal" ;
VAL_ 514 BCM_FrontWipeSWSts 4 "Wipe auto" 3 "Wipe int" 2 "Wipe high" 1 "Wipe low" 0 "Wipe off" ;
VAL_ 514 BCM_AutoWipeSts 1 "ON" 0 "OFF" ;
VAL_ 514 BCM_FrontWipeSts 2 "Wipe high" 1 "Wipe low" 0 "Wipe off" ;
VAL_ 514 BCM_FrontWipeReturn 1 "归位" 0 "未归位" ;
VAL_ 514 BCM_FrontWinWashSWSts 1 "ON" 0 "OFF" ;
VAL_ 514 BCM_RearWipeSWSts 2 "Wipe&Wash" 1 "Wipe" 0 "Off" ;
VAL_ 514 BCM_RearWipeSts 2 "Wipe high" 1 "Wipe low" 0 "Wipe off" ;
VAL_ 514 BCM_RearWipeReturn 1 "归位" 0 "未归位" ;
VAL_ 514 BCM_RearWinWashSWSts 1 "ON" 0 "OFF" ;
VAL_ 560 EPB_SysBrkLtsReq 1 "True(点亮)" 0 "False(熄灭)" ;
VAL_ 560 EPB_SysDspMsgReqV 1 "Invalid" 0 "Valid" ;
VAL_ 560 EPB_SysStatIndReqV 1 "Invalid" 0 "Valid" ;
VAL_ 560 EPB_SysWrnIndReqV 1 "Invalid" 0 "Valid" ;
VAL_ 560 EPB_SysWrnIndReq 2 "FlashRate#1 Indication(闪烁指示)" 1 "Continuous Indication(连续指示)" 0 "No Indication(不指示)" ;
VAL_ 560 EPB_SysStatIndReq 2 "FlashRate#1 Indication(闪烁指示)" 1 "Continuous Indication(连续指示)" 0 "No Indication(不指示)" ;
VAL_ 560 EPB_SysDspMsgReq 7 "Message #7" 6 "Message #6" 5 "Message #5" 4 "Message #4" 3 "Message #3" 2 "Message #2" 1 "Message #1" 0 "Off" ;
VAL_ 560 EPB_AVHWrnIndReq 1 "Continuous Indication" 0 "No Indication" ;
VAL_ 560 EPB_AVHWrnIndReqV 1 "Invalid" 0 "Valid" ;
VAL_ 560 EPB_AVHStatIndReq 1 "Continuous Indication" 0 "No Indication" ;
VAL_ 560 EPB_AVHStatIndReqV 1 "Invalid" 0 "Valid" ;
VAL_ 560 EPB_AVHFeedbackSts 1 "AVH Disable" 0 "AVH Enable" ;
VAL_ 560 EPB_Sts 4 "Locking（夹紧过程中）" 3 "Releasing（释放过程中）" 2 "Locked（夹紧）" 1 "Released（释放）" 0 "Unknown（未知）" ;
VAL_ 560 WCBS_Trailermode_Feedback 1 "Trailermode inactive" 0 "Trailermode active" ;
VAL_ 617 WCBS_ACC_VLC_Active 1 "Active" 0 "Inactive" ;
VAL_ 617 WCBS_ACC_CDD_Active 1 "Active" 0 "Inactive" ;
VAL_ 617 WCBS_ACC_VLC_Avl 1 "Available" 0 "Not Available" ;
VAL_ 617 WCBS_ACC_CDD_Avl 1 "Available" 0 "Not Available" ;
VAL_ 617 WCBS_ABAAtv 1 "Active" 0 "Inactive" ;
VAL_ 617 WCBS_ABAAva 1 "Available" 0 "Not Available" ;
VAL_ 617 WCBS_ABPAtv 1 "Active" 0 "Inactive" ;
VAL_ 617 WCBS_ABPAva 1 "Available" 0 "Not Available" ;
VAL_ 617 WCBS_AWBAtv 1 "Active" 0 "Inactive" ;
VAL_ 617 WCBS_AWBAvl 1 "Available" 0 "Not Available" ;
VAL_ 617 WCBS_AEBAtv 1 "Active;" 0 "Inactive." ;
VAL_ 617 WCBS_AEBAva 1 "Available" 0 "Not Available" ;
VAL_ 617 WCBS_VStandstillSta 3 "Unused and Reserved（预留）" 2 "invalid (short unavailability, max 3s)（无效）" 1 "standstill（静止）" 0 "not standstill（未静止）" ;
VAL_ 617 WCBS_BrkFrcSta 1 "Exist BrakeForce" 0 "No BrakeForce（4个轮缸均无制动压力）" ;
VAL_ 617 WCBS_ESCDeteACCErroSta 3 "Unused and Reserved（预留）" 2 "Irreversible Error（指示 DAS 系统 VLC 发生不可逆失效请求中断）" 1 "Reversible Error（指示 DAS 系统 VLC 发生可逆失效请求中断）" 0 "No Error（无故障）" ;
VAL_ 617 WCBS_APA_VLC_FailureStatus 15 "reserve8" 14 "reserve7" 13 "reserve6" 12 "reserve5" 11 "reserve4" 10 "reserve3" 9 "reserve2" 8 "reserve1" 7 "Error/Invalid(指示系统故障，直接退出)" 6 "Undefined Error(指示其他故障(包含通信故障))" 5 "Unexpected Gear Intervention:指示换挡杆被操作" 4 "车速超限，车速>=6km/h,100ms" 3 "Unexpected EPB Action(指示电子驻车工作异常)" 2 "Unexpected Gear Position(指示换挡异常)" 1 "Vehicle Blocked(指示车辆受阻，无法安全移动)" 0 "No Error" ;
VAL_ 617 WCBS_APA_VLC_Status 7 "Reserved" 6 "Reserved" 5 "Reserved" 4 "Reserved" 3 "Automated Parking" 2 "Emergency Brake" 1 "Comfortable Brake" 0 "No request" ;
VAL_ 617 WCBS_APA_VLC_Available 1 "Available" 0 "Not Available" ;
VAL_ 617 WCBS_APA_VLC_Active 1 "Active" 0 "Inactive" ;
VAL_ 617 WCBS_APA_EmgyBrkAvlb 1 "Available" 0 "Not Available" ;
VAL_ 617 WCBS_APA_CDD_Active 1 "Active" 0 "Inactive" ;
VAL_ 624 AB_BrkPedalSwSts 1 "pressed" 0 "unpressed" ;
VAL_ 624 AB_BrkPedalSwStsV 1 "Invalid" 0 "Valid" ;
VAL_ 624 AB_Fault_Status 3 "制动功能正常，冗余系统故障（文字提示）" 2 "Level 2Fault（功能故障，点亮红灯）" 1 "Level 1 Fault（功能降级，点亮黄灯）" 0 "No Fault" ;
VAL_ 624 AB_IBS_Sys_Fault_Sts 1 "Fault" 0 "No Fault" ;
VAL_ 676 MHU_ESCOFF_SW_Sts 2 "ESC ON" 1 "ESC OFF" 0 "No Action" ;
VAL_ 676 MHU_VCU_CreepDisable_stt 2 "Creep Enable" 1 "Creep Disable" 0 "No Action" ;
VAL_ 676 MHU_AVH_Req 2 "ON(开启)" 1 "OFF(关闭)" 0 "No Action" ;
VAL_ 676 MHU_RegencyLevRequest 3 "Request Regency Leve2高" 2 "Request Regency Leve1低" 1 "OFF" 0 "No Request" ;
VAL_ 676 MHU_DM_SwitchModeSts 3 "Sport Mode" 2 "Eco Mode" 1 "Comfort Mode" 0 "No request" ;
VAL_ 676 MHU_Trailermode_Req 2 "ON(开启)" 1 "OFF(关闭)" 0 "No Action" ;
VAL_ 676 MHU_UPAMuteSwitch 2 "ON" 1 "OFF" 0 "No Action" ;
VAL_ 994 ESC_LateralACC_Valid 1 "Valid" 0 "Invalid" ;
VAL_ 994 ESC_LongitudeACC_Valid 1 "Valid" 0 "Invalid" ;
VAL_ 994 ESC_VehDynYawRate_Valid 1 "Valid" 0 "Invalid" ;
VAL_ 1009 IPC_IPCTotalOdometerV 1 "invalid" 0 "valid" ;
VAL_ 1015 MFS_ACC_CruiseSpdIncrease 7 "Signal invalid" 2 "Long Press(+1km/h,continuous)" 1 "Short Press(+5km/h)" 0 "Button not Pressed" ;
VAL_ 1015 MFS_ACC_CruiseOn_Off 7 "Signal invalid" 2 "Long Press" 1 "Short Press" 0 "Button not Pressed" ;
VAL_ 1015 MFS_L2_Failure 1 "Error" 0 "No Error" ;
VAL_ 1015 MFS_ACC_CruiseGapSet 7 "Signal invalid" 2 "Long Press" 1 "Short Press" 0 "Button not Pressed" ;
VAL_ 1015 MFS_ACC_CruiseSpdDecrease 7 "Signal invalid" 2 "Long Press(-1km/h,continuous)" 1 "Short Press(-5km/h)" 0 "Button not Pressed" ;
VAL_ 1015 MFS_ACC_CruiseCancel 7 "Signal invalid" 2 "Long Press" 1 "Short Press" 0 "Button not Pressed" ;
VAL_ 1067 TPMS_RFpressureSts 4 "Unknown" 3 "Leakage" 2 "High" 1 "Low" 0 "Normal" ;
VAL_ 1067 TPMS_LFpressureSts 4 "Unknown" 3 "Leakage" 2 "High" 1 "Low" 0 "Normal" ;
VAL_ 1067 TPMS_SysSts 1 "Fault" 0 "Normal" ;
VAL_ 1067 TPMS_RRpressureSts 4 "Unknown" 3 "Leakage" 2 "High" 1 "Low" 0 "Normal" ;
VAL_ 1067 TPMS_LRpressureSts 4 "Unknown" 3 "Leakage" 2 "High" 1 "Low" 0 "Normal" ;
VAL_ 1067 TPMS_RRpressureV 1 "Invalid" 0 "Valid" ;
VAL_ 1067 TPMS_LRpressureV 1 "Invalid" 0 "Valid" ;
VAL_ 1067 TPMS_RFpressureV 1 "Invalid" 0 "Valid" ;
VAL_ 1067 TPMS_LFpressureV 1 "Invalid" 0 "Valid" ;
VAL_ 1236 BCM_CoverAjarStatus 1 "CoverAjar" 0 "CoverClosed" ;
VAL_ 1236 BCM_TrunckAjarStatus 1 "TrunkAjar" 0 "TrunkClosed" ;
VAL_ 1236 BCM_DriverSideDoorAjarSts 1 "DoorAjar" 0 "DoorClosed" ;
VAL_ 1236 BCM_CodriversSideDoorAjarSts 1 "DoorAjar" 0 "DoorClosed" ;
VAL_ 1236 BCM_RearLeftDoorAjarStatus 1 "DoorAjar" 0 "DoorClosed" ;
VAL_ 1236 BCM_RearRightDoorAjarStatus 1 "DoorAjar" 0 "DoorClosed" ;
VAL_ 1236 BCM_DoorLockStatusRL 3 "Error(Reserved)" 2 "Reserved" 1 "Locked" 0 "Unlocked" ;
VAL_ 1236 BCM_DoorLockStatusRR 3 "Error(Reserved)" 2 "Reserved" 1 "Locked" 0 "Unlocked" ;
VAL_ 1236 BCM_DoorLockStatusCodrivres 3 "Error(Reserved)" 2 "Reserved" 1 "Locked" 0 "Unlocked" ;
VAL_ 1236 BCM_DoorLockStatusDrv 3 "Error(Reserved)" 2 "Reserved" 1 "Locked" 0 "Unlocked" ;
VAL_ 1236 BCM_ATWS_St 5 "Partially Armed" 4 "Alarm报警" 3 "Remind保持当前状态" 2 "Disarmed未设防" 1 "Prearmed预设防" 0 "Armed 设防" ;
VAL_ 1236 BCM_TailGateSts 1 "Open" 0 "Close" ;
VAL_ 265 BCM_STAT_Horn 3 "Signal invalid" 1 "ON" 0 "OFF" ;
VAL_ 265 BCM_STAT_HazardWarn 3 "Signal invalid" 2 "Reserved" 1 "Active" 0 "Not active" ;
VAL_ 265 BCM_LowBeamSWSts 3 "Auto" 2 "Low Beam" 1 "Position Lamp" 0 "OFF档" ;
VAL_ 265 BCM_TurnLightSWSts 2 "Right Turn Light" 1 "Left Turn Light" 0 "OFF档" ;
VAL_ 265 BCM_Tail_MicroSW 1 "Pressed(按下)" 0 "Not pressed(未按下)" ;
VAL_ 265 STAT_Central_LockSts 3 "Signal invalid" 1 "ON" 0 "OFF" ;
VAL_ 265 BCM_RFogLampSWSts 1 "Open(断开)" 0 "Close(闭合)" ;
VAL_ 265 BCM_FFogLampSWSts 1 "Open(断开)" 0 "Close(闭合)" ;
VAL_ 265 BCM_HighBeamSWSts 2 "Passing Light" 1 "High Beaam" 0 "OFF档" ;
VAL_ 482 PEPS_PowerModeValidity 2 "Valid" 1 "Invalid" 0 "Not available" ;
VAL_ 482 PEPS_PowerMode 4 "START" 2 "ON" 1 "ACC" 0 "OFF" ;
VAL_ 482 PEPS_IGN1RelayValidity 1 "Valid" 0 "Invalid" ;
VAL_ 482 PEPS_IGN1RelaySts 1 "Active" 0 "Inactive" ;
VAL_ 482 PEPS_Learning_Status 2 "Learnt" 1 "Virgin" 0 "Invalid" ;
VAL_ 482 BCM_WPC_Off_Req 2 "Reserve" 1 "Off" 0 "No Request" ;
VAL_ 1056 RLS_Rainfall_magnitude 3 "Heavy rain(大雨)(24h内＞50mm)" 2 "Moderate rain(中雨)(预留)" 1 "Light rain(小雨)(预留)" 0 "No rain" ;
VAL_ 1056 RLS_LightSensorError 1 "Error" 0 "No error" ;
VAL_ 1056 RLS_RainSensorError 1 "Error" 0 "No error" ;
VAL_ 1056 RLS_LightRequest 1 "Switch light on" 0 "Switch light off" ;
VAL_ 354 VCU_ModeGearSts 4 "D" 3 "N" 2 "R" 1 "P" 0 "Invalid" ;
VAL_ 354 VCU_P_Sts 1 "Press" 0 "NO Action" ;
VAL_ 354 VCU_Warning_IMMO_Fail 2 "unknown" 1 "Fail" 0 "No warning" ;
VAL_ 354 VCU_Ready 1 "Ready" 0 "Not Ready" ;
VAL_ 354 VCU_RegencyLevInd 3 "Regency Leve2 高" 2 "Regency Leve1 低" 1 "OFF" 0 "Default" ;
VAL_ 354 VCU_LimpHomeSts 1 "in Limphome Mode" 0 "not in Limphome Mode" ;
VAL_ 359 VCU_StsAccPedalFault 1 "Fault" 0 "Normal" ;
VAL_ 359 VCU_StsSysFault 14 "Invalid(无效)" 13 "EmPowerdown(紧急下电)" 11 "Powerdown(延迟下电)" 9 "ZeroTorque(零扭矩)" 7 "Limphome(跛行回家)" 5 "Derating(降功率)" 3 "Warning(报警)" 1 "Normal(正常)" 0 "Init(初始化)(预留)" ;
VAL_ 359 VCU_AccPedal_Active 1 "Invalid" 0 "Valid" ;
VAL_ 811 CCU_PTCgear_Req_Reserve 7 "六挡" 6 "五挡" 5 "四挡" 4 "三挡" 3 "二挡" 2 "一挡" 1 "0挡" 0 "无请求" ;
VAL_ 811 CCU_Anion_Generator_Sts 3 "Invalid" 2 "Sleep" 1 "Operation" 0 "No Operation" ;
VAL_ 811 CCU_AC_Req 3 "Invalid" 1 "Requset" 0 "No requset" ;
VAL_ 811 CCU_Onoff_Sts 1 "ON" 0 "OFF" ;
VAL_ 811 CCU_AUTO_Status 1 "ON" 0 "OFF" ;
VAL_ 811 CCU_FrontDefrostSts 1 "ON" 0 "OFF" ;
VAL_ 811 CCU_AC_Sts 1 "ON" 0 "OFF" ;
VAL_ 811 CCU_Circulation_Sts 1 "Internal circulation" 0 "Outer circulation" ;
VAL_ 811 CCU_ExternalTemperatureFailSts 1 "invalid" 0 "valid" ;
VAL_ 811 CCU_PTC_Req 3 "Invalid" 1 "Requset" 0 "No requset" ;
VAL_ 811 CCU_Temp_Sync_Sts 1 "ON" 0 "OFF" ;
VAL_ 670 GPSSystAtv 1 "inactive" 0 "active" ;
